[part 3 of 11: packages /Communication/PDUs to /SoftwareTypes/ComponentTypes]
AUTOSAR XML (schema 00048)
package /Communication/PDUs  (continued)
  pdu SIGIPDU_RR_GetPackageData_call_Cis_ICC_8155_Android_ADCC_AomDB: has-dynamic-length=true, length=1312, transmission-mode-true-timing=event-controlled-timing=number-of-repetitions=0
    signal SIG_RR_GetPackageData_call_Cis_ICC_8155_Android_ADCC_AomDB: start 0, 10432 bit, opaque, data-transformations=SOME_IP_Default_Transformation, data-type-policy=TRANSFORMING-I-SIGNAL, someip-transformation-i-signal-props{transformer=SOME_IP_Default_Transformer, message-type=REQUEST}, dynamic-length=true, transfer-property=TRIGGERED, to ADCC
  pdu SIGIPDU_RR_GetPackageData_return_Cis_ICC_8155_Android_ADCC_AomDB: has-dynamic-length=true, length=2097164, transmission-mode-true-timing=event-controlled-timing=number-of-repetitions=0
    signal SIG_RR_GetPackageData_return_Cis_ICC_8155_Android_ADCC_AomDB: start 0, 16777248 bit, opaque, data-transformations=SOME_IP_Default_Transformation, data-type-policy=TRANSFORMING-I-SIGNAL, someip-transformation-i-signal-props{transformer=SOME_IP_Default_Transformer, message-type=RESPONSE}, dynamic-length=true, transfer-property=TRIGGERED, to ICC_8155_Android
  general purpose i pdu TPSIGIPDU_RR_GetPackageData_return_Cis_ICC_8155_Android_ADCC_AomDB: category=SOMEIP_SEGMENTED_IPDU, length=1400
  pdu SIGIPDU_RR_GetPackageData_call_Cis_ICC_8155_QNX_ADCC_AomDB: has-dynamic-length=true, length=1312, transmission-mode-true-timing=event-controlled-timing=number-of-repetitions=0
    signal SIG_RR_GetPackageData_call_Cis_ICC_8155_QNX_ADCC_AomDB: start 0, 10432 bit, opaque, data-transformations=SOME_IP_Default_Transformation, data-type-policy=TRANSFORMING-I-SIGNAL, someip-transformation-i-signal-props{transformer=SOME_IP_Default_Transformer, message-type=REQUEST}, dynamic-length=true, transfer-property=TRIGGERED, to ADCC
  pdu SIGIPDU_RR_GetPackageData_return_Cis_ICC_8155_QNX_ADCC_AomDB: has-dynamic-length=true, length=2097164, transmission-mode-true-timing=event-controlled-timing=number-of-repetitions=0
    signal SIG_RR_GetPackageData_return_Cis_ICC_8155_QNX_ADCC_AomDB: start 0, 16777248 bit, opaque, data-transformations=SOME_IP_Default_Transformation, data-type-policy=TRANSFORMING-I-SIGNAL, someip-transformation-i-signal-props{transformer=SOME_IP_Default_Transformer, message-type=RESPONSE}, dynamic-length=true, transfer-property=TRIGGERED, to ICC_8155_QNX
  general purpose i pdu TPSIGIPDU_RR_GetPackageData_return_Cis_ICC_8155_QNX_ADCC_AomDB: category=SOMEIP_SEGMENTED_IPDU, length=1400
  pdu SIGIPDU_Event_notifyRtMatchRes_ADCC_RtMM: has-dynamic-length=false, length=14304, transmission-mode-true-timing=event-controlled-timing=number-of-repetitions=0
    signal SIG_Event_notifyRtMatchRes_ADCC_RtMM: start 0, 114368 bit, opaque, data-transformations=SOME_IP_Default_Transformation, data-type-policy=TRANSFORMING-I-SIGNAL, someip-transformation-i-signal-props{transformer=SOME_IP_Default_Transformer, message-type=NOTIFICATION}, transfer-property=TRIGGERED, to ICC_8155_Android
  general purpose i pdu TPSIGIPDU_Event_notifyRtMatchRes_ADCC_RtMM: category=SOMEIP_SEGMENTED_IPDU, length=1400
  pdu SIGIPDU_Event_notifyRtMatchRes_ADCC_RtMM_1: has-dynamic-length=false, length=14304, transmission-mode-true-timing=event-controlled-timing=number-of-repetitions=0
    signal SIG_Event_notifyRtMatchRes_ADCC_RtMM_1: start 0, 114368 bit, opaque, data-transformations=SOME_IP_Default_Transformation, data-type-policy=TRANSFORMING-I-SIGNAL, someip-transformation-i-signal-props{transformer=SOME_IP_Default_Transformer, message-type=NOTIFICATION}, transfer-property=TRIGGERED, to ICC_8155_QNX
  general purpose i pdu TPSIGIPDU_Event_notifyRtMatchRes_ADCC_RtMM_1: category=SOMEIP_SEGMENTED_IPDU, length=1400
  pdu SIGIPDU_Event_NtfDynamicObjectList_FCM_DrivingHmiEnv: has-dynamic-length=true, length=2032, transmission-mode-true-timing=event-controlled-timing=number-of-repetitions=0
    signal SIG_Event_NtfDynamicObjectList_FCM_DrivingHmiEnv: start 0, 16192 bit, opaque, data-transformations=SOME_IP_Default_Transformation, data-type-policy=TRANSFORMING-I-SIGNAL, someip-transformation-i-signal-props{transformer=SOME_IP_Default_Transformer, message-type=NOTIFICATION}, dynamic-length=true, transfer-property=TRIGGERED, to ICC_8155_QNX
  general purpose i pdu TPSIGIPDU_Event_NtfDynamicObjectList_FCM_DrivingHmiEnv: category=SOMEIP_SEGMENTED_IPDU, length=1400
  pdu SIGIPDU_Event_NtfStaticObjectList_FCM_DrivingHmiEnv: has-dynamic-length=true, length=1696, transmission-mode-true-timing=event-controlled-timing=number-of-repetitions=0
    signal SIG_Event_NtfStaticObjectList_FCM_DrivingHmiEnv: start 0, 13504 bit, opaque, data-transformations=SOME_IP_Default_Transformation, data-type-policy=TRANSFORMING-I-SIGNAL, someip-transformation-i-signal-props{transformer=SOME_IP_Default_Transformer, message-type=NOTIFICATION}, dynamic-length=true, transfer-property=TRIGGERED, to ICC_8155_QNX
  general purpose i pdu TPSIGIPDU_Event_NtfStaticObjectList_FCM_DrivingHmiEnv: category=SOMEIP_SEGMENTED_IPDU, length=1400
  pdu SIGIPDU_Event_NtfLaneLineList_FCM_DrivingHmiEnv: has-dynamic-length=true, length=332, transmission-mode-true-timing=event-controlled-timing=number-of-repetitions=0
    signal SIG_Event_NtfLaneLineList_FCM_DrivingHmiEnv: start 0, 2592 bit, opaque, data-transformations=SOME_IP_Default_Transformation, data-type-policy=TRANSFORMING-I-SIGNAL, someip-transformation-i-signal-props{transformer=SOME_IP_Default_Transformer, message-type=NOTIFICATION}, dynamic-length=true, transfer-property=TRIGGERED, to ICC_8155_QNX
  pdu SIGIPDU_Event_NtfLaneLineList_2_FCM_DrivingHmiEnv: has-dynamic-length=true, length=146224, transmission-mode-true-timing=event-controlled-timing=number-of-repetitions=0
    signal SIG_Event_NtfLaneLineList_2_FCM_DrivingHmiEnv: start 0, 1169728 bit, opaque, data-transformations=SOME_IP_Default_Transformation, data-type-policy=TRANSFORMING-I-SIGNAL, someip-transformation-i-signal-props{transformer=SOME_IP_Default_Transformer, message-type=NOTIFICATION}, dynamic-length=true, transfer-property=TRIGGERED, to ICC_8155_QNX
  general purpose i pdu TPSIGIPDU_Event_NtfLaneLineList_2_FCM_DrivingHmiEnv: category=SOMEIP_SEGMENTED_IPDU, length=1400
  pdu SIGIPDU_Event_NtfEgoFusionPose_FCM_DrivingHmiEnv: has-dynamic-length=false, length=56, transmission-mode-true-timing=event-controlled-timing=number-of-repetitions=0
    signal SIG_Event_NtfEgoFusionPose_FCM_DrivingHmiEnv: start 0, 384 bit, opaque, data-transformations=SOME_IP_Default_Transformation, data-type-policy=TRANSFORMING-I-SIGNAL, someip-transformation-i-signal-props{transformer=SOME_IP_Default_Transformer, message-type=NOTIFICATION}, transfer-property=TRIGGERED, to ICC_8155_QNX
  pdu SIGIPDU_Event_NtfDynamicObjectList_2_FCM_DrivingHmiEnv: has-dynamic-length=true, length=8416, transmission-mode-true-timing=event-controlled-timing=number-of-repetitions=0
    signal SIG_Event_NtfDynamicObjectList_2_FCM_DrivingHmiEnv: start 0, 67264 bit, opaque, data-transformations=SOME_IP_Default_Transformation, data-type-policy=TRANSFORMING-I-SIGNAL, someip-transformation-i-signal-props{transformer=SOME_IP_Default_Transformer, message-type=NOTIFICATION}, dynamic-length=true, transfer-property=TRIGGERED, to ICC_8155_QNX
  general purpose i pdu TPSIGIPDU_Event_NtfDynamicObjectList_2_FCM_DrivingHmiEnv: category=SOMEIP_SEGMENTED_IPDU, length=1400
  pdu SIGIPDU_Event_NtfStaticObjectList_2_FCM_DrivingHmiEnv: has-dynamic-length=true, length=4816, transmission-mode-true-timing=event-controlled-timing=number-of-repetitions=0
    signal SIG_Event_NtfStaticObjectList_2_FCM_DrivingHmiEnv: start 0, 38464 bit, opaque, data-transformations=SOME_IP_Default_Transformation, data-type-policy=TRANSFORMING-I-SIGNAL, someip-transformation-i-signal-props{transformer=SOME_IP_Default_Transformer, message-type=NOTIFICATION}, dynamic-length=true, transfer-property=TRIGGERED, to ICC_8155_QNX
  general purpose i pdu TPSIGIPDU_Event_NtfStaticObjectList_2_FCM_DrivingHmiEnv: category=SOMEIP_SEGMENTED_IPDU, length=1400
  pdu SIGIPDU_Event_NtfDynamicObjectList_FCM_DrivingHmiEnv_1: has-dynamic-length=true, length=2032, transmission-mode-true-timing=event-controlled-timing=number-of-repetitions=0
    signal SIG_Event_NtfDynamicObjectList_FCM_DrivingHmiEnv_1: start 0, 16192 bit, opaque, data-transformations=SOME_IP_Default_Transformation, data-type-policy=TRANSFORMING-I-SIGNAL, someip-transformation-i-signal-props{transformer=SOME_IP_Default_Transformer, message-type=NOTIFICATION}, dynamic-length=true, transfer-property=TRIGGERED, to ICC_8155_Android
  general purpose i pdu TPSIGIPDU_Event_NtfDynamicObjectList_FCM_DrivingHmiEnv_1: category=SOMEIP_SEGMENTED_IPDU, length=1400
  pdu SIGIPDU_Event_NtfStaticObjectList_FCM_DrivingHmiEnv_1: has-dynamic-length=true, length=1696, transmission-mode-true-timing=event-controlled-timing=number-of-repetitions=0
    signal SIG_Event_NtfStaticObjectList_FCM_DrivingHmiEnv_1: start 0, 13504 bit, opaque, data-transformations=SOME_IP_Default_Transformation, data-type-policy=TRANSFORMING-I-SIGNAL, someip-transformation-i-signal-props{transformer=SOME_IP_Default_Transformer, message-type=NOTIFICATION}, dynamic-length=true, transfer-property=TRIGGERED, to ICC_8155_Android
  general purpose i pdu TPSIGIPDU_Event_NtfStaticObjectList_FCM_DrivingHmiEnv_1: category=SOMEIP_SEGMENTED_IPDU, length=1400
  pdu SIGIPDU_Event_NtfLaneLineList_FCM_DrivingHmiEnv_1: has-dynamic-length=true, length=332, transmission-mode-true-timing=event-controlled-timing=number-of-repetitions=0
    signal SIG_Event_NtfLaneLineList_FCM_DrivingHmiEnv_1: start 0, 2592 bit, opaque, data-transformations=SOME_IP_Default_Transformation, data-type-policy=TRANSFORMING-I-SIGNAL, someip-transformation-i-signal-props{transformer=SOME_IP_Default_Transformer, message-type=NOTIFICATION}, dynamic-length=true, transfer-property=TRIGGERED, to ICC_8155_Android
  pdu SIGIPDU_Event_NtfLaneLineList_2_FCM_DrivingHmiEnv_1: has-dynamic-length=true, length=146224, transmission-mode-true-timing=event-controlled-timing=number-of-repetitions=0
    signal SIG_Event_NtfLaneLineList_2_FCM_DrivingHmiEnv_1: start 0, 1169728 bit, opaque, data-transformations=SOME_IP_Default_Transformation, data-type-policy=TRANSFORMING-I-SIGNAL, someip-transformation-i-signal-props{transformer=SOME_IP_Default_Transformer, message-type=NOTIFICATION}, dynamic-length=true, transfer-property=TRIGGERED, to ICC_8155_Android
  general purpose i pdu TPSIGIPDU_Event_NtfLaneLineList_2_FCM_DrivingHmiEnv_1: category=SOMEIP_SEGMENTED_IPDU, length=1400
  pdu SIGIPDU_Event_NtfEgoFusionPose_FCM_DrivingHmiEnv_1: has-dynamic-length=false, length=56, transmission-mode-true-timing=event-controlled-timing=number-of-repetitions=0
    signal SIG_Event_NtfEgoFusionPose_FCM_DrivingHmiEnv_1: start 0, 384 bit, opaque, data-transformations=SOME_IP_Default_Transformation, data-type-policy=TRANSFORMING-I-SIGNAL, someip-transformation-i-signal-props{transformer=SOME_IP_Default_Transformer, message-type=NOTIFICATION}, transfer-property=TRIGGERED, to ICC_8155_Android
  pdu SIGIPDU_Event_NtfDynamicObjectList_2_FCM_DrivingHmiEnv_1: has-dynamic-length=true, length=8416, transmission-mode-true-timing=event-controlled-timing=number-of-repetitions=0
    signal SIG_Event_NtfDynamicObjectList_2_FCM_DrivingHmiEnv_1: start 0, 67264 bit, opaque, data-transformations=SOME_IP_Default_Transformation, data-type-policy=TRANSFORMING-I-SIGNAL, someip-transformation-i-signal-props{transformer=SOME_IP_Default_Transformer, message-type=NOTIFICATION}, dynamic-length=true, transfer-property=TRIGGERED, to ICC_8155_Android
  general purpose i pdu TPSIGIPDU_Event_NtfDynamicObjectList_2_FCM_DrivingHmiEnv_1: category=SOMEIP_SEGMENTED_IPDU, length=1400
  pdu SIGIPDU_Event_NtfStaticObjectList_2_FCM_DrivingHmiEnv_1: has-dynamic-length=true, length=4816, transmission-mode-true-timing=event-controlled-timing=number-of-repetitions=0
    signal SIG_Event_NtfStaticObjectList_2_FCM_DrivingHmiEnv_1: start 0, 38464 bit, opaque, data-transformations=SOME_IP_Default_Transformation, data-type-policy=TRANSFORMING-I-SIGNAL, someip-transformation-i-signal-props{transformer=SOME_IP_Default_Transformer, message-type=NOTIFICATION}, dynamic-length=true, transfer-property=TRIGGERED, to ICC_8155_Android
  general purpose i pdu TPSIGIPDU_Event_NtfStaticObjectList_2_FCM_DrivingHmiEnv_1: category=SOMEIP_SEGMENTED_IPDU, length=1400
  pdu SIGIPDU_Event_NtfActiveSafetyFcnInfo_FCM_ActiveSafetyInfo: has-dynamic-length=false, length=27, transmission-mode-true-timing=event-controlled-timing=number-of-repetitions=0
    signal SIG_Event_NtfActiveSafetyFcnInfo_FCM_ActiveSafetyInfo: start 0, 40 bit, opaque, data-transformations=SOMEIP_E2E_Transformer_PROFILE_04_B, data-type-policy=TRANSFORMING-I-SIGNAL, transfer-property=TRIGGERED, to ICC_8155_Android
  pdu SIGIPDU_Event_NtfAEBTargetObjInfo_FCM_ActiveSafetyInfo: has-dynamic-length=false, length=24, transmission-mode-true-timing=event-controlled-timing=number-of-repetitions=0
    signal SIG_Event_NtfAEBTargetObjInfo_FCM_ActiveSafetyInfo: start 0, 128 bit, opaque, data-transformations=SOME_IP_Default_Transformation, data-type-policy=TRANSFORMING-I-SIGNAL, someip-transformation-i-signal-props{transformer=SOME_IP_Default_Transformer, message-type=NOTIFICATION}, transfer-property=TRIGGERED, to ICC_8155_Android
  pdu SIGIPDU_Event_NtfActiveSafetyFcnInfo_2_FCM_ActiveSafetyInfo: has-dynamic-length=false, length=64, transmission-mode-true-timing=event-controlled-timing=number-of-repetitions=0
    signal SIG_Event_NtfActiveSafetyFcnInfo_2_FCM_ActiveSafetyInfo: start 0, 448 bit, opaque, data-transformations=SOME_IP_Default_Transformation, data-type-policy=TRANSFORMING-I-SIGNAL, someip-transformation-i-signal-props{transformer=SOME_IP_Default_Transformer, message-type=NOTIFICATION}, transfer-property=TRIGGERED, to ICC_8155_Android
  pdu SIGIPDU_Event_NtfAEBTargetObjInfo_2_FCM_ActiveSafetyInfo: has-dynamic-length=false, length=32, transmission-mode-true-timing=event-controlled-timing=number-of-repetitions=0
    signal SIG_Event_NtfAEBTargetObjInfo_2_FCM_ActiveSafetyInfo: start 0, 192 bit, opaque, data-transformations=SOME_IP_Default_Transformation, data-type-policy=TRANSFORMING-I-SIGNAL, someip-transformation-i-signal-props{transformer=SOME_IP_Default_Transformer, message-type=NOTIFICATION}, transfer-property=TRIGGERED, to ICC_8155_Android
  pdu SIGIPDU_Event_NtfActiveSafetyFcnInfo_FCM_ActiveSafetyInfo_1: has-dynamic-length=false, length=27, transmission-mode-true-timing=event-controlled-timing=number-of-repetitions=0
    signal SIG_Event_NtfActiveSafetyFcnInfo_FCM_ActiveSafetyInfo_1: start 0, 40 bit, opaque, data-transformations=SOMEIP_E2E_Transformer_PROFILE_04_B, data-type-policy=TRANSFORMING-I-SIGNAL, transfer-property=TRIGGERED, to ICC_8155_QNX
  pdu SIGIPDU_Event_NtfAEBTargetObjInfo_FCM_ActiveSafetyInfo_1: has-dynamic-length=false, length=24, transmission-mode-true-timing=event-controlled-timing=number-of-repetitions=0
    signal SIG_Event_NtfAEBTargetObjInfo_FCM_ActiveSafetyInfo_1: start 0, 128 bit, opaque, data-transformations=SOME_IP_Default_Transformation, data-type-policy=TRANSFORMING-I-SIGNAL, someip-transformation-i-signal-props{transformer=SOME_IP_Default_Transformer, message-type=NOTIFICATION}, transfer-property=TRIGGERED, to ICC_8155_QNX
  pdu SIGIPDU_Event_NtfActiveSafetyFcnInfo_2_FCM_ActiveSafetyInfo_1: has-dynamic-length=false, length=64, transmission-mode-true-timing=event-controlled-timing=number-of-repetitions=0
    signal SIG_Event_NtfActiveSafetyFcnInfo_2_FCM_ActiveSafetyInfo_1: start 0, 448 bit, opaque, data-transformations=SOME_IP_Default_Transformation, data-type-policy=TRANSFORMING-I-SIGNAL, someip-transformation-i-signal-props{transformer=SOME_IP_Default_Transformer, message-type=NOTIFICATION}, transfer-property=TRIGGERED, to ICC_8155_QNX
  pdu SIGIPDU_Event_NtfAEBTargetObjInfo_2_FCM_ActiveSafetyInfo_1: has-dynamic-length=false, length=32, transmission-mode-true-timing=event-controlled-timing=number-of-repetitions=0
    signal SIG_Event_NtfAEBTargetObjInfo_2_FCM_ActiveSafetyInfo_1: start 0, 192 bit, opaque, data-transformations=SOME_IP_Default_Transformation, data-type-policy=TRANSFORMING-I-SIGNAL, someip-transformation-i-signal-props{transformer=SOME_IP_Default_Transformer, message-type=NOTIFICATION}, transfer-property=TRIGGERED, to ICC_8155_QNX
  pdu SIGIPDU_Event_NtfTrafficSign_FCM_DrivingFuncInfo: has-dynamic-length=false, length=24, transmission-mode-true-timing=event-controlled-timing=number-of-repetitions=0
    signal SIG_Event_NtfTrafficSign_FCM_DrivingFuncInfo: start 0, 128 bit, opaque, data-transformations=SOME_IP_Default_Transformation, data-type-policy=TRANSFORMING-I-SIGNAL, someip-transformation-i-signal-props{transformer=SOME_IP_Default_Transformer, message-type=NOTIFICATION}, transfer-property=TRIGGERED, to ICC_8155_Android
  pdu SIGIPDU_Event_NtfISLIinfo_FCM_DrivingFuncInfo: has-dynamic-length=false, length=16, transmission-mode-true-timing=event-controlled-timing=number-of-repetitions=0
    signal SIG_Event_NtfISLIinfo_FCM_DrivingFuncInfo: start 0, 64 bit, opaque, data-transformations=SOME_IP_Default_Transformation, data-type-policy=TRANSFORMING-I-SIGNAL, someip-transformation-i-signal-props{transformer=SOME_IP_Default_Transformer, message-type=NOTIFICATION}, transfer-property=TRIGGERED, to ICC_8155_Android
  pdu SIGIPDU_Event_NtfACCinfo_FCM_DrivingFuncInfo: has-dynamic-length=false, length=40, transmission-mode-true-timing=event-controlled-timing=number-of-repetitions=0
    signal SIG_Event_NtfACCinfo_FCM_DrivingFuncInfo: start 0, 144 bit, opaque, data-transformations=SOMEIP_E2E_Transformer_PROFILE_04_B, data-type-policy=TRANSFORMING-I-SIGNAL, transfer-property=TRIGGERED, to ICC_8155_Android
  pdu SIGIPDU_Event_NtfICAInfo_FCM_DrivingFuncInfo: has-dynamic-length=false, length=12, transmission-mode-true-timing=event-controlled-timing=number-of-repetitions=0
    signal SIG_Event_NtfICAInfo_FCM_DrivingFuncInfo: start 0, 32 bit, opaque, data-transformations=SOME_IP_Default_Transformation, data-type-policy=TRANSFORMING-I-SIGNAL, someip-transformation-i-signal-props{transformer=SOME_IP_Default_Transformer, message-type=NOTIFICATION}, transfer-property=TRIGGERED, to ICC_8155_Android
  pdu SIGIPDU_Event_NtfIntelligentEvasionInfo_FCM_DrivingFuncInfo: has-dynamic-length=false, length=11, transmission-mode-true-timing=event-controlled-timing=number-of-repetitions=0
    signal SIG_Event_NtfIntelligentEvasionInfo_FCM_DrivingFuncInfo: start 0, 24 bit, opaque, data-transformations=SOME_IP_Default_Transformation, data-type-policy=TRANSFORMING-I-SIGNAL, someip-transformation-i-signal-props{transformer=SOME_IP_Default_Transformer, message-type=NOTIFICATION}, transfer-property=TRIGGERED, to ICC_8155_Android
  pdu SIGIPDU_Event_NtfHodDmsInfo_FCM_DrivingFuncInfo: has-dynamic-length=false, length=12, transmission-mode-true-timing=event-controlled-timing=number-of-repetitions=0
    signal SIG_Event_NtfHodDmsInfo_FCM_DrivingFuncInfo: start 0, 32 bit, opaque, data-transformations=SOME_IP_Default_Transformation, data-type-policy=TRANSFORMING-I-SIGNAL, someip-transformation-i-signal-props{transformer=SOME_IP_Default_Transformer, message-type=NOTIFICATION}, transfer-property=TRIGGERED, to ICC_8155_Android
  pdu SIGIPDU_Event_NtfLSSInfo_FCM_DrivingFuncInfo: has-dynamic-length=false, length=16, transmission-mode-true-timing=event-controlled-timing=number-of-repetitions=0
    signal SIG_Event_NtfLSSInfo_FCM_DrivingFuncInfo: start 0, 64 bit, opaque, data-transformations=SOME_IP_Default_Transformation, data-type-policy=TRANSFORMING-I-SIGNAL, someip-transformation-i-signal-props{transformer=SOME_IP_Default_Transformer, message-type=NOTIFICATION}, transfer-property=TRIGGERED, to ICC_8155_Android
  pdu SIGIPDU_Event_NtfESSInfo_FCM_DrivingFuncInfo: has-dynamic-length=false, length=12, transmission-mode-true-timing=event-controlled-timing=number-of-repetitions=0
    signal SIG_Event_NtfESSInfo_FCM_DrivingFuncInfo: start 0, 32 bit, opaque, data-transformations=SOME_IP_Default_Transformation, data-type-policy=TRANSFORMING-I-SIGNAL, someip-transformation-i-signal-props{transformer=SOME_IP_Default_Transformer, message-type=NOTIFICATION}, transfer-property=TRIGGERED, to ICC_8155_Android
  pdu SIGIPDU_Event_NtfDAIInfo_FCM_DrivingFuncInfo: has-dynamic-length=false, length=10, transmission-mode-true-timing=event-controlled-timing=number-of-repetitions=0
    signal SIG_Event_NtfDAIInfo_FCM_DrivingFuncInfo: start 0, 16 bit, opaque, data-transformations=SOME_IP_Default_Transformation, data-type-policy=TRANSFORMING-I-SIGNAL, someip-transformation-i-signal-props{transformer=SOME_IP_Default_Transformer, message-type=NOTIFICATION}, transfer-property=TRIGGERED, to ICC_8155_Android
  pdu SIGIPDU_Event_NtfISLIinfo_2_FCM_DrivingFuncInfo: has-dynamic-length=false, length=69, transmission-mode-true-timing=event-controlled-timing=number-of-repetitions=0
    signal SIG_Event_NtfISLIinfo_2_FCM_DrivingFuncInfo: start 0, 488 bit, opaque, data-transformations=SOME_IP_Default_Transformation, data-type-policy=TRANSFORMING-I-SIGNAL, someip-transformation-i-signal-props{transformer=SOME_IP_Default_Transformer, message-type=NOTIFICATION}, transfer-property=TRIGGERED, to ICC_8155_Android
  pdu SIGIPDU_Event_NtfLSSInfo_2_FCM_DrivingFuncInfo: has-dynamic-length=false, length=68, transmission-mode-true-timing=event-controlled-timing=number-of-repetitions=0
    signal SIG_Event_NtfLSSInfo_2_FCM_DrivingFuncInfo: start 0, 480 bit, opaque, data-transformations=SOME_IP_Default_Transformation, data-type-policy=TRANSFORMING-I-SIGNAL, someip-transformation-i-signal-props{transformer=SOME_IP_Default_Transformer, message-type=NOTIFICATION}, transfer-property=TRIGGERED, to ICC_8155_Android
  pdu SIGIPDU_Event_NtfDrivingSoundInfo_FCM_DrivingFuncInfo: has-dynamic-length=false, length=39, transmission-mode-true-timing=event-controlled-timing=number-of-repetitions=0
    signal SIG_Event_NtfDrivingSoundInfo_FCM_DrivingFuncInfo: start 0, 248 bit, opaque, data-transformations=SOME_IP_Default_Transformation, data-type-policy=TRANSFORMING-I-SIGNAL, someip-transformation-i-signal-props{transformer=SOME_IP_Default_Transformer, message-type=NOTIFICATION}, transfer-property=TRIGGERED, to ICC_8155_Android
  pdu SIGIPDU_Event_NtfIHCInfo_FCM_DrivingFuncInfo: has-dynamic-length=false, length=60, transmission-mode-true-timing=event-controlled-timing=number-of-repetitions=0
    signal SIG_Event_NtfIHCInfo_FCM_DrivingFuncInfo: start 0, 416 bit, opaque, data-transformations=SOME_IP_Default_Transformation, data-type-policy=TRANSFORMING-I-SIGNAL, someip-transformation-i-signal-props{transformer=SOME_IP_Default_Transformer, message-type=NOTIFICATION}, transfer-property=TRIGGERED, to ICC_8155_Android
  pdu SIGIPDU_Event_NtfHNOPfunctionInfo_FCM_DrivingFuncInfo: has-dynamic-length=false, length=536, transmission-mode-true-timing=event-controlled-timing=number-of-repetitions=0
    signal SIG_Event_NtfHNOPfunctionInfo_FCM_DrivingFuncInfo: start 0, 4224 bit, opaque, data-transformations=SOME_IP_Default_Transformation, data-type-policy=TRANSFORMING-I-SIGNAL, someip-transformation-i-signal-props{transformer=SOME_IP_Default_Transformer, message-type=NOTIFICATION}, transfer-property=TRIGGERED, to ICC_8155_Android
  pdu SIGIPDU_Event_NtfTrafficSign_FCM_DrivingFuncInfo_1: has-dynamic-length=false, length=24, transmission-mode-true-timing=event-controlled-timing=number-of-repetitions=0
    signal SIG_Event_NtfTrafficSign_FCM_DrivingFuncInfo_1: start 0, 128 bit, opaque, data-transformations=SOME_IP_Default_Transformation, data-type-policy=TRANSFORMING-I-SIGNAL, someip-transformation-i-signal-props{transformer=SOME_IP_Default_Transformer, message-type=NOTIFICATION}, transfer-property=TRIGGERED, to ICC_8155_QNX
  pdu SIGIPDU_Event_NtfISLIinfo_FCM_DrivingFuncInfo_1: has-dynamic-length=false, length=16, transmission-mode-true-timing=event-controlled-timing=number-of-repetitions=0
    signal SIG_Event_NtfISLIinfo_FCM_DrivingFuncInfo_1: start 0, 64 bit, opaque, data-transformations=SOME_IP_Default_Transformation, data-type-policy=TRANSFORMING-I-SIGNAL, someip-transformation-i-signal-props{transformer=SOME_IP_Default_Transformer, message-type=NOTIFICATION}, transfer-property=TRIGGERED, to ICC_8155_QNX
  pdu SIGIPDU_Event_NtfACCinfo_FCM_DrivingFuncInfo_1: has-dynamic-length=false, length=40, transmission-mode-true-timing=event-controlled-timing=number-of-repetitions=0
    signal SIG_Event_NtfACCinfo_FCM_DrivingFuncInfo_1: start 0, 144 bit, opaque, data-transformations=SOMEIP_E2E_Transformer_PROFILE_04_B, data-type-policy=TRANSFORMING-I-SIGNAL, transfer-property=TRIGGERED, to ICC_8155_QNX
  pdu SIGIPDU_Event_NtfICAInfo_FCM_DrivingFuncInfo_1: has-dynamic-length=false, length=12, transmission-mode-true-timing=event-controlled-timing=number-of-repetitions=0
    signal SIG_Event_NtfICAInfo_FCM_DrivingFuncInfo_1: start 0, 32 bit, opaque, data-transformations=SOME_IP_Default_Transformation, data-type-policy=TRANSFORMING-I-SIGNAL, someip-transformation-i-signal-props{transformer=SOME_IP_Default_Transformer, message-type=NOTIFICATION}, transfer-property=TRIGGERED, to ICC_8155_QNX
  pdu SIGIPDU_Event_NtfIntelligentEvasionInfo_FCM_DrivingFuncInfo_1: has-dynamic-length=false, length=11, transmission-mode-true-timing=event-controlled-timing=number-of-repetitions=0
    signal SIG_Event_NtfIntelligentEvasionInfo_FCM_DrivingFuncInfo_1: start 0, 24 bit, opaque, data-transformations=SOME_IP_Default_Transformation, data-type-policy=TRANSFORMING-I-SIGNAL, someip-transformation-i-signal-props{transformer=SOME_IP_Default_Transformer, message-type=NOTIFICATION}, transfer-property=TRIGGERED, to ICC_8155_QNX
  pdu SIGIPDU_Event_NtfHodDmsInfo_FCM_DrivingFuncInfo_1: has-dynamic-length=false, length=12, transmission-mode-true-timing=event-controlled-timing=number-of-repetitions=0
    signal SIG_Event_NtfHodDmsInfo_FCM_DrivingFuncInfo_1: start 0, 32 bit, opaque, data-transformations=SOME_IP_Default_Transformation, data-type-policy=TRANSFORMING-I-SIGNAL, someip-transformation-i-signal-props{transformer=SOME_IP_Default_Transformer, message-type=NOTIFICATION}, transfer-property=TRIGGERED, to ICC_8155_QNX
  pdu SIGIPDU_Event_NtfLSSInfo_FCM_DrivingFuncInfo_1: has-dynamic-length=false, length=16, transmission-mode-true-timing=event-controlled-timing=number-of-repetitions=0
    signal SIG_Event_NtfLSSInfo_FCM_DrivingFuncInfo_1: start 0, 64 bit, opaque, data-transformations=SOME_IP_Default_Transformation, data-type-policy=TRANSFORMING-I-SIGNAL, someip-transformation-i-signal-props{transformer=SOME_IP_Default_Transformer, message-type=NOTIFICATION}, transfer-property=TRIGGERED, to ICC_8155_QNX
  pdu SIGIPDU_Event_NtfESSInfo_FCM_DrivingFuncInfo_1: has-dynamic-length=false, length=12, transmission-mode-true-timing=event-controlled-timing=number-of-repetitions=0
    signal SIG_Event_NtfESSInfo_FCM_DrivingFuncInfo_1: start 0, 32 bit, opaque, data-transformations=SOME_IP_Default_Transformation, data-type-policy=TRANSFORMING-I-SIGNAL, someip-transformation-i-signal-props{transformer=SOME_IP_Default_Transformer, message-type=NOTIFICATION}, transfer-property=TRIGGERED, to ICC_8155_QNX
  pdu SIGIPDU_Event_NtfDAIInfo_FCM_DrivingFuncInfo_1: has-dynamic-length=false, length=10, transmission-mode-true-timing=event-controlled-timing=number-of-repetitions=0
    signal SIG_Event_NtfDAIInfo_FCM_DrivingFuncInfo_1: start 0, 16 bit, opaque, data-transformations=SOME_IP_Default_Transformation, data-type-policy=TRANSFORMING-I-SIGNAL, someip-transformation-i-signal-props{transformer=SOME_IP_Default_Transformer, message-type=NOTIFICATION}, transfer-property=TRIGGERED, to ICC_8155_QNX
  pdu SIGIPDU_Event_NtfISLIinfo_2_FCM_DrivingFuncInfo_1: has-dynamic-length=false, length=69, transmission-mode-true-timing=event-controlled-timing=number-of-repetitions=0
    signal SIG_Event_NtfISLIinfo_2_FCM_DrivingFuncInfo_1: start 0, 488 bit, opaque, data-transformations=SOME_IP_Default_Transformation, data-type-policy=TRANSFORMING-I-SIGNAL, someip-transformation-i-signal-props{transformer=SOME_IP_Default_Transformer, message-type=NOTIFICATION}, transfer-property=TRIGGERED, to ICC_8155_QNX
  pdu SIGIPDU_Event_NtfLSSInfo_2_FCM_DrivingFuncInfo_1: has-dynamic-length=false, length=68, transmission-mode-true-timing=event-controlled-timing=number-of-repetitions=0
    signal SIG_Event_NtfLSSInfo_2_FCM_DrivingFuncInfo_1: start 0, 480 bit, opaque, data-transformations=SOME_IP_Default_Transformation, data-type-policy=TRANSFORMING-I-SIGNAL, someip-transformation-i-signal-props{transformer=SOME_IP_Default_Transformer, message-type=NOTIFICATION}, transfer-property=TRIGGERED, to ICC_8155_QNX
  pdu SIGIPDU_Event_NtfDrivingSoundInfo_FCM_DrivingFuncInfo_1: has-dynamic-length=false, length=39, transmission-mode-true-timing=event-controlled-timing=number-of-repetitions=0
    signal SIG_Event_NtfDrivingSoundInfo_FCM_DrivingFuncInfo_1: start 0, 248 bit, opaque, data-transformations=SOME_IP_Default_Transformation, data-type-policy=TRANSFORMING-I-SIGNAL, someip-transformation-i-signal-props{transformer=SOME_IP_Default_Transformer, message-type=NOTIFICATION}, transfer-property=TRIGGERED, to ICC_8155_QNX
  pdu SIGIPDU_Event_NtfIHCInfo_FCM_DrivingFuncInfo_1: has-dynamic-length=false, length=60, transmission-mode-true-timing=event-controlled-timing=number-of-repetitions=0
    signal SIG_Event_NtfIHCInfo_FCM_DrivingFuncInfo_1: start 0, 416 bit, opaque, data-transformations=SOME_IP_Default_Transformation, data-type-policy=TRANSFORMING-I-SIGNAL, someip-transformation-i-signal-props{transformer=SOME_IP_Default_Transformer, message-type=NOTIFICATION}, transfer-property=TRIGGERED, to ICC_8155_QNX
  pdu SIGIPDU_Event_NtfHNOPfunctionInfo_FCM_DrivingFuncInfo_1: has-dynamic-length=false, length=536, transmission-mode-true-timing=event-controlled-timing=number-of-repetitions=0
    signal SIG_Event_NtfHNOPfunctionInfo_FCM_DrivingFuncInfo_1: start 0, 4224 bit, opaque, data-transformations=SOME_IP_Default_Transformation, data-type-policy=TRANSFORMING-I-SIGNAL, someip-transformation-i-signal-props{transformer=SOME_IP_Default_Transformer, message-type=NOTIFICATION}, transfer-property=TRIGGERED, to ICC_8155_QNX
  pdu SIGIPDU_Event_notifyDVRSts_FCM_DVRSts: has-dynamic-length=false, length=9, transmission-mode-true-timing=event-controlled-timing=number-of-repetitions=0
    signal SIG_Event_notifyDVRSts_FCM_DVRSts: start 0, 8 bit, opaque, data-transformations=SOME_IP_Default_Transformation, data-type-policy=TRANSFORMING-I-SIGNAL, someip-transformation-i-signal-props{transformer=SOME_IP_Default_Transformer, message-type=NOTIFICATION}, transfer-property=TRIGGERED, to ICC_8155_Android
  pdu SIGIPDU_Event_notifyDVRcameraSts_FCM_DVRSts: has-dynamic-length=false, length=9, transmission-mode-true-timing=event-controlled-timing=number-of-repetitions=0
    signal SIG_Event_notifyDVRcameraSts_FCM_DVRSts: start 0, 8 bit, opaque, data-transformations=SOME_IP_Default_Transformation, data-type-policy=TRANSFORMING-I-SIGNAL, someip-transformation-i-signal-props{transformer=SOME_IP_Default_Transformer, message-type=NOTIFICATION}, transfer-property=TRIGGERED, to ICC_8155_Android
  pdu SIGIPDU_Event_notifyCameraInterParm_FCM_DVRSts: has-dynamic-length=false, length=104, transmission-mode-true-timing=event-controlled-timing=number-of-repetitions=0
    signal SIG_Event_notifyCameraInterParm_FCM_DVRSts: start 0, 768 bit, opaque, data-transformations=SOME_IP_Default_Transformation, data-type-policy=TRANSFORMING-I-SIGNAL, someip-transformation-i-signal-props{transformer=SOME_IP_Default_Transformer, message-type=NOTIFICATION}, transfer-property=TRIGGERED, to ICC_8155_Android
  pdu SIGIPDU_RR_getCameraInterParm_call_Cis_ICC_8155_Android_FCM_DVRSts: has-dynamic-length=true, length=8, transmission-mode-true-timing=event-controlled-timing=number-of-repetitions=0
    signal SIG_RR_getCameraInterParm_call_Cis_ICC_8155_Android_FCM_DVRSts: start 0, 0 bit, opaque, data-transformations=SOME_IP_Default_Transformation, data-type-policy=TRANSFORMING-I-SIGNAL, someip-transformation-i-signal-props{transformer=SOME_IP_Default_Transformer, message-type=REQUEST}, dynamic-length=true, transfer-property=TRIGGERED, to FCM
  pdu SIGIPDU_RR_getCameraInterParm_return_Cis_ICC_8155_Android_FCM_DVRSts: has-dynamic-length=false, length=104, transmission-mode-true-timing=event-controlled-timing=number-of-repetitions=0
    signal SIG_RR_getCameraInterParm_return_Cis_ICC_8155_Android_FCM_DVRSts: start 0, 768 bit, opaque, data-transformations=SOME_IP_Default_Transformation, data-type-policy=TRANSFORMING-I-SIGNAL, someip-transformation-i-signal-props{transformer=SOME_IP_Default_Transformer, message-type=RESPONSE}, transfer-property=TRIGGERED, to ICC_8155_Android
  pdu SIGIPDU_Event_notifyDVRSts_FCM_DVRSts_1: has-dynamic-length=false, length=9, transmission-mode-true-timing=event-controlled-timing=number-of-repetitions=0
    signal SIG_Event_notifyDVRSts_FCM_DVRSts_1: start 0, 8 bit, opaque, data-transformations=SOME_IP_Default_Transformation, data-type-policy=TRANSFORMING-I-SIGNAL, someip-transformation-i-signal-props{transformer=SOME_IP_Default_Transformer, message-type=NOTIFICATION}, transfer-property=TRIGGERED, to ICC_8155_QNX
  pdu SIGIPDU_Event_notifyDVRcameraSts_FCM_DVRSts_1: has-dynamic-length=false, length=9, transmission-mode-true-timing=event-controlled-timing=number-of-repetitions=0
    signal SIG_Event_notifyDVRcameraSts_FCM_DVRSts_1: start 0, 8 bit, opaque, data-transformations=SOME_IP_Default_Transformation, data-type-policy=TRANSFORMING-I-SIGNAL, someip-transformation-i-signal-props{transformer=SOME_IP_Default_Transformer, message-type=NOTIFICATION}, transfer-property=TRIGGERED, to ICC_8155_QNX
  pdu SIGIPDU_Event_notifyCameraInterParm_FCM_DVRSts_1: has-dynamic-length=false, length=104, transmission-mode-true-timing=event-controlled-timing=number-of-repetitions=0
    signal SIG_Event_notifyCameraInterParm_FCM_DVRSts_1: start 0, 768 bit, opaque, data-transformations=SOME_IP_Default_Transformation, data-type-policy=TRANSFORMING-I-SIGNAL, someip-transformation-i-signal-props{transformer=SOME_IP_Default_Transformer, message-type=NOTIFICATION}, transfer-property=TRIGGERED, to ICC_8155_QNX
  pdu SIGIPDU_RR_getCameraInterParm_call_Cis_ICC_8155_QNX_FCM_DVRSts: has-dynamic-length=true, length=8, transmission-mode-true-timing=event-controlled-timing=number-of-repetitions=0
    signal SIG_RR_getCameraInterParm_call_Cis_ICC_8155_QNX_FCM_DVRSts: start 0, 0 bit, opaque, data-transformations=SOME_IP_Default_Transformation, data-type-policy=TRANSFORMING-I-SIGNAL, someip-transformation-i-signal-props{transformer=SOME_IP_Default_Transformer, message-type=REQUEST}, dynamic-length=true, transfer-property=TRIGGERED, to FCM
  pdu SIGIPDU_RR_getCameraInterParm_return_Cis_ICC_8155_QNX_FCM_DVRSts: has-dynamic-length=false, length=104, transmission-mode-true-timing=event-controlled-timing=number-of-repetitions=0
    signal SIG_RR_getCameraInterParm_return_Cis_ICC_8155_QNX_FCM_DVRSts: start 0, 768 bit, opaque, data-transformations=SOME_IP_Default_Transformation, data-type-policy=TRANSFORMING-I-SIGNAL, someip-transformation-i-signal-props{transformer=SOME_IP_Default_Transformer, message-type=RESPONSE}, transfer-property=TRIGGERED, to ICC_8155_QNX
  pdu SIGIPDU_RR_GetUUIDCodeResponse_call_Cis_TBOX_FCM_UUID: has-dynamic-length=false, length=9, transmission-mode-true-timing=event-controlled-timing=number-of-repetitions=0
    signal SIG_RR_GetUUIDCodeResponse_call_Cis_TBOX_FCM_UUID: start 0, 8 bit, opaque, data-transformations=SOME_IP_Default_Transformation, data-type-policy=TRANSFORMING-I-SIGNAL, someip-transformation-i-signal-props{transformer=SOME_IP_Default_Transformer, message-type=REQUEST}, transfer-property=TRIGGERED, to FCM
  pdu SIGIPDU_RR_GetUUIDCodeResponse_return_Cis_TBOX_FCM_UUID: has-dynamic-length=false, length=140, transmission-mode-true-timing=event-controlled-timing=number-of-repetitions=0
    signal SIG_RR_GetUUIDCodeResponse_return_Cis_TBOX_FCM_UUID: start 0, 1056 bit, opaque, data-transformations=SOME_IP_Default_Transformation, data-type-policy=TRANSFORMING-I-SIGNAL, someip-transformation-i-signal-props{transformer=SOME_IP_Default_Transformer, message-type=RESPONSE}, transfer-property=TRIGGERED, to TBOX
  pdu SIGIPDU_RR_GetUUIDCodeResponse_call_Cis_ADCC_FCM_UUID: has-dynamic-length=false, length=9, transmission-mode-true-timing=event-controlled-timing=number-of-repetitions=0
    signal SIG_RR_GetUUIDCodeResponse_call_Cis_ADCC_FCM_UUID: start 0, 8 bit, opaque, data-transformations=SOME_IP_Default_Transformation, data-type-policy=TRANSFORMING-I-SIGNAL, someip-transformation-i-signal-props{transformer=SOME_IP_Default_Transformer, message-type=REQUEST}, transfer-property=TRIGGERED, to FCM
  pdu SIGIPDU_RR_GetUUIDCodeResponse_return_Cis_ADCC_FCM_UUID: has-dynamic-length=false, length=140, transmission-mode-true-timing=event-controlled-timing=number-of-repetitions=0
    signal SIG_RR_GetUUIDCodeResponse_return_Cis_ADCC_FCM_UUID: start 0, 1056 bit, opaque, data-transformations=SOME_IP_Default_Transformation, data-type-policy=TRANSFORMING-I-SIGNAL, someip-transformation-i-signal-props{transformer=SOME_IP_Default_Transformer, message-type=RESPONSE}, transfer-property=TRIGGERED, to ADCC
  pdu SIGIPDU_RR_GetUUIDCodeResponse_call_Cis_LCM_FCM_UUID: has-dynamic-length=false, length=9, transmission-mode-true-timing=event-controlled-timing=number-of-repetitions=0
    signal SIG_RR_GetUUIDCodeResponse_call_Cis_LCM_FCM_UUID: start 0, 8 bit, opaque, data-transformations=SOME_IP_Default_Transformation, data-type-policy=TRANSFORMING-I-SIGNAL, someip-transformation-i-signal-props{transformer=SOME_IP_Default_Transformer, message-type=REQUEST}, transfer-property=TRIGGERED, to FCM
  pdu SIGIPDU_RR_GetUUIDCodeResponse_return_Cis_LCM_FCM_UUID: has-dynamic-length=false, length=140, transmission-mode-true-timing=event-controlled-timing=number-of-repetitions=0
    signal SIG_RR_GetUUIDCodeResponse_return_Cis_LCM_FCM_UUID: start 0, 1056 bit, opaque, data-transformations=SOME_IP_Default_Transformation, data-type-policy=TRANSFORMING-I-SIGNAL, someip-transformation-i-signal-props{transformer=SOME_IP_Default_Transformer, message-type=RESPONSE}, transfer-property=TRIGGERED, to LCM
  pdu SIGIPDU_RR_GetUUIDCodeResponse_call_Cis_ICC_8155_Android_FCM_UUID: has-dynamic-length=false, length=9, transmission-mode-true-timing=event-controlled-timing=number-of-repetitions=0
    signal SIG_RR_GetUUIDCodeResponse_call_Cis_ICC_8155_Android_FCM_UUID: start 0, 8 bit, opaque, data-transformations=SOME_IP_Default_Transformation, data-type-policy=TRANSFORMING-I-SIGNAL, someip-transformation-i-signal-props{transformer=SOME_IP_Default_Transformer, message-type=REQUEST}, transfer-property=TRIGGERED, to FCM
  pdu SIGIPDU_RR_GetUUIDCodeResponse_return_Cis_ICC_8155_Android_FCM_UUID: has-dynamic-length=false, length=140, transmission-mode-true-timing=event-controlled-timing=number-of-repetitions=0
    signal SIG_RR_GetUUIDCodeResponse_return_Cis_ICC_8155_Android_FCM_UUID: start 0, 1056 bit, opaque, data-transformations=SOME_IP_Default_Transformation, data-type-policy=TRANSFORMING-I-SIGNAL, someip-transformation-i-signal-props{transformer=SOME_IP_Default_Transformer, message-type=RESPONSE}, transfer-property=TRIGGERED, to ICC_8155_Android
  pdu SIGIPDU_Event_NtfIMUInfo_LCM_ICC_Data: has-dynamic-length=false, length=40, transmission-mode-true-timing=event-controlled-timing=number-of-repetitions=0
    signal SIG_Event_NtfIMUInfo_LCM_ICC_Data: start 0, 256 bit, opaque, data-transformations=SOME_IP_Default_Transformation, data-type-policy=TRANSFORMING-I-SIGNAL, someip-transformation-i-signal-props{transformer=SOME_IP_Default_Transformer, message-type=NOTIFICATION}, transfer-property=TRIGGERED, to ICC_8155_QNX
  pdu SIGIPDU_Event_NtfGRawInfo_LCM_ADCC_RawData: has-dynamic-length=true, length=1036, transmission-mode-true-timing=event-controlled-timing=number-of-repetitions=0
    signal SIG_Event_NtfGRawInfo_LCM_ADCC_RawData: start 0, 8224 bit, opaque, data-transformations=SOME_IP_Default_Transformation, data-type-policy=TRANSFORMING-I-SIGNAL, someip-transformation-i-signal-props{transformer=SOME_IP_Default_Transformer, message-type=NOTIFICATION}, dynamic-length=true, transfer-property=TRIGGERED, to ADCC
  pdu SIGIPDU_Event_NtfActiveSafetyFcnInfo_Act_ADCC_ActiveSafetyInfo: has-dynamic-length=false, length=27, transmission-mode-true-timing=event-controlled-timing=number-of-repetitions=0
    signal SIG_Event_NtfActiveSafetyFcnInfo_Act_ADCC_ActiveSafetyInfo: start 0, 40 bit, opaque, data-transformations=SOMEIP_E2E_Transformer_PROFILE_04_B, data-type-policy=TRANSFORMING-I-SIGNAL, transfer-property=TRIGGERED, to ICC_8155_Android
  pdu SIGIPDU_Event_NtfAEBTargetObjInfo_Act_ADCC_ActiveSafetyInfo: has-dynamic-length=false, length=24, transmission-mode-true-timing=event-controlled-timing=number-of-repetitions=0
    signal SIG_Event_NtfAEBTargetObjInfo_Act_ADCC_ActiveSafetyInfo: start 0, 128 bit, opaque, data-transformations=SOME_IP_Default_Transformation, data-type-policy=TRANSFORMING-I-SIGNAL, someip-transformation-i-signal-props{transformer=SOME_IP_Default_Transformer, message-type=NOTIFICATION}, transfer-property=TRIGGERED, to ICC_8155_Android
  pdu SIGIPDU_Event_NtfActiveSafetyFcnInfo_Act_2_ADCC_ActiveSafetyInfo: has-dynamic-length=false, length=64, transmission-mode-true-timing=event-controlled-timing=number-of-repetitions=0
    signal SIG_Event_NtfActiveSafetyFcnInfo_Act_2_ADCC_ActiveSafetyInfo: start 0, 448 bit, opaque, data-transformations=SOME_IP_Default_Transformation, data-type-policy=TRANSFORMING-I-SIGNAL, someip-transformation-i-signal-props{transformer=SOME_IP_Default_Transformer, message-type=NOTIFICATION}, transfer-property=TRIGGERED, to ICC_8155_Android
  pdu SIGIPDU_Event_NtfAEBTargetObjInfo_Act_2_ADCC_ActiveSafetyInfo: has-dynamic-length=true, length=92, transmission-mode-true-timing=event-controlled-timing=number-of-repetitions=0
    signal SIG_Event_NtfAEBTargetObjInfo_Act_2_ADCC_ActiveSafetyInfo: start 0, 672 bit, opaque, data-transformations=SOME_IP_Default_Transformation, data-type-policy=TRANSFORMING-I-SIGNAL, someip-transformation-i-signal-props{transformer=SOME_IP_Default_Transformer, message-type=NOTIFICATION}, dynamic-length=true, transfer-property=TRIGGERED, to ICC_8155_Android
  pdu SIGIPDU_Event_NtfAEBTargetObjInfo_Act_3_ADCC_ActiveSafetyInfo: has-dynamic-length=false, length=32, transmission-mode-true-timing=event-controlled-timing=number-of-repetitions=0
    signal SIG_Event_NtfAEBTargetObjInfo_Act_3_ADCC_ActiveSafetyInfo: start 0, 192 bit, opaque, data-transformations=SOME_IP_Default_Transformation, data-type-policy=TRANSFORMING-I-SIGNAL, someip-transformation-i-signal-props{transformer=SOME_IP_Default_Transformer, message-type=NOTIFICATION}, transfer-property=TRIGGERED, to ICC_8155_Android
  pdu SIGIPDU_Event_NtfActiveSafetyFcnInfo_Act_ADCC_ActiveSafetyInfo_1: has-dynamic-length=false, length=27, transmission-mode-true-timing=event-controlled-timing=number-of-repetitions=0
    signal SIG_Event_NtfActiveSafetyFcnInfo_Act_ADCC_ActiveSafetyInfo_1: start 0, 40 bit, opaque, data-transformations=SOMEIP_E2E_Transformer_PROFILE_04_B, data-type-policy=TRANSFORMING-I-SIGNAL, transfer-property=TRIGGERED, to ICC_8155_QNX
  pdu SIGIPDU_Event_NtfAEBTargetObjInfo_Act_ADCC_ActiveSafetyInfo_1: has-dynamic-length=false, length=24, transmission-mode-true-timing=event-controlled-timing=number-of-repetitions=0
    signal SIG_Event_NtfAEBTargetObjInfo_Act_ADCC_ActiveSafetyInfo_1: start 0, 128 bit, opaque, data-transformations=SOME_IP_Default_Transformation, data-type-policy=TRANSFORMING-I-SIGNAL, someip-transformation-i-signal-props{transformer=SOME_IP_Default_Transformer, message-type=NOTIFICATION}, transfer-property=TRIGGERED, to ICC_8155_QNX
  pdu SIGIPDU_Event_NtfActiveSafetyFcnInfo_Act_2_ADCC_ActiveSafetyInfo_1: has-dynamic-length=false, length=64, transmission-mode-true-timing=event-controlled-timing=number-of-repetitions=0
    signal SIG_Event_NtfActiveSafetyFcnInfo_Act_2_ADCC_ActiveSafetyInfo_1: start 0, 448 bit, opaque, data-transformations=SOME_IP_Default_Transformation, data-type-policy=TRANSFORMING-I-SIGNAL, someip-transformation-i-signal-props{transformer=SOME_IP_Default_Transformer, message-type=NOTIFICATION}, transfer-property=TRIGGERED, to ICC_8155_QNX
  pdu SIGIPDU_Event_NtfAEBTargetObjInfo_Act_2_ADCC_ActiveSafetyInfo_1: has-dynamic-length=true, length=92, transmission-mode-true-timing=event-controlled-timing=number-of-repetitions=0
    signal SIG_Event_NtfAEBTargetObjInfo_Act_2_ADCC_ActiveSafetyInfo_1: start 0, 672 bit, opaque, data-transformations=SOME_IP_Default_Transformation, data-type-policy=TRANSFORMING-I-SIGNAL, someip-transformation-i-signal-props{transformer=SOME_IP_Default_Transformer, message-type=NOTIFICATION}, dynamic-length=true, transfer-property=TRIGGERED, to ICC_8155_QNX
  pdu SIGIPDU_Event_NtfAEBTargetObjInfo_Act_3_ADCC_ActiveSafetyInfo_1: has-dynamic-length=false, length=32, transmission-mode-true-timing=event-controlled-timing=number-of-repetitions=0
    signal SIG_Event_NtfAEBTargetObjInfo_Act_3_ADCC_ActiveSafetyInfo_1: start 0, 192 bit, opaque, data-transformations=SOME_IP_Default_Transformation, data-type-policy=TRANSFORMING-I-SIGNAL, someip-transformation-i-signal-props{transformer=SOME_IP_Default_Transformer, message-type=NOTIFICATION}, transfer-property=TRIGGERED, to ICC_8155_QNX
  pdu SIGIPDU_RR_GetUUIDCodeResponse_UUID_call_Cis_TBOX_ADCC_UUID: has-dynamic-length=false, length=9, transmission-mode-true-timing=event-controlled-timing=number-of-repetitions=0
    signal SIG_RR_GetUUIDCodeResponse_UUID_call_Cis_TBOX_ADCC_UUID: start 0, 8 bit, opaque, data-transformations=SOME_IP_Default_Transformation, data-type-policy=TRANSFORMING-I-SIGNAL, someip-transformation-i-signal-props{transformer=SOME_IP_Default_Transformer, message-type=REQUEST}, transfer-property=TRIGGERED, to ADCC
  pdu SIGIPDU_RR_GetUUIDCodeResponse_UUID_return_Cis_TBOX_ADCC_UUID: has-dynamic-length=false, length=140, transmission-mode-true-timing=event-controlled-timing=number-of-repetitions=0
    signal SIG_RR_GetUUIDCodeResponse_UUID_return_Cis_TBOX_ADCC_UUID: start 0, 1056 bit, opaque, data-transformations=SOME_IP_Default_Transformation, data-type-policy=TRANSFORMING-I-SIGNAL, someip-transformation-i-signal-props{transformer=SOME_IP_Default_Transformer, message-type=RESPONSE}, transfer-property=TRIGGERED, to TBOX
  pdu SIGIPDU_RR_GetUUIDCodeResponse_UUID_call_Cis_LCM_ADCC_UUID: has-dynamic-length=false, length=9, transmission-mode-true-timing=event-controlled-timing=number-of-repetitions=0
    signal SIG_RR_GetUUIDCodeResponse_UUID_call_Cis_LCM_ADCC_UUID: start 0, 8 bit, opaque, data-transformations=SOME_IP_Default_Transformation, data-type-policy=TRANSFORMING-I-SIGNAL, someip-transformation-i-signal-props{transformer=SOME_IP_Default_Transformer, message-type=REQUEST}, transfer-property=TRIGGERED, to ADCC
  pdu SIGIPDU_RR_GetUUIDCodeResponse_UUID_return_Cis_LCM_ADCC_UUID: has-dynamic-length=false, length=140, transmission-mode-true-timing=event-controlled-timing=number-of-repetitions=0
    signal SIG_RR_GetUUIDCodeResponse_UUID_return_Cis_LCM_ADCC_UUID: start 0, 1056 bit, opaque, data-transformations=SOME_IP_Default_Transformation, data-type-policy=TRANSFORMING-I-SIGNAL, someip-transformation-i-signal-props{transformer=SOME_IP_Default_Transformer, message-type=RESPONSE}, transfer-property=TRIGGERED, to LCM
  pdu SIGIPDU_RR_GetUUIDCodeResponse_UUID_call_Cis_ICC_8155_Android_ADCC_UUID: has-dynamic-length=false, length=9, transmission-mode-true-timing=event-controlled-timing=number-of-repetitions=0
    signal SIG_RR_GetUUIDCodeResponse_UUID_call_Cis_ICC_8155_Android_ADCC_UUID: start 0, 8 bit, opaque, data-transformations=SOME_IP_Default_Transformation, data-type-policy=TRANSFORMING-I-SIGNAL, someip-transformation-i-signal-props{transformer=SOME_IP_Default_Transformer, message-type=REQUEST}, transfer-property=TRIGGERED, to ADCC
  pdu SIGIPDU_RR_GetUUIDCodeResponse_UUID_return_Cis_ICC_8155_Android_ADCC_UUID: has-dynamic-length=false, length=140, transmission-mode-true-timing=event-controlled-timing=number-of-repetitions=0
    signal SIG_RR_GetUUIDCodeResponse_UUID_return_Cis_ICC_8155_Android_ADCC_UUID: start 0, 1056 bit, opaque, data-transformations=SOME_IP_Default_Transformation, data-type-policy=TRANSFORMING-I-SIGNAL, someip-transformation-i-signal-props{transformer=SOME_IP_Default_Transformer, message-type=RESPONSE}, transfer-property=TRIGGERED, to ICC_8155_Android
  pdu SIGIPDU_Event_NtfSensorSt_FCM_FCM_SensorInfo: has-dynamic-length=false, length=37, transmission-mode-true-timing=event-controlled-timing=number-of-repetitions=0
    signal SIG_Event_NtfSensorSt_FCM_FCM_SensorInfo: start 0, 232 bit, opaque, data-transformations=SOME_IP_Default_Transformation, data-type-policy=TRANSFORMING-I-SIGNAL, someip-transformation-i-signal-props{transformer=SOME_IP_Default_Transformer, message-type=NOTIFICATION}, transfer-property=TRIGGERED, to ICC_8155_Android
  pdu SIGIPDU_Event_NtfSensorSt_FCM_FCM_SensorInfo_1: has-dynamic-length=false, length=37, transmission-mode-true-timing=event-controlled-timing=number-of-repetitions=0
    signal SIG_Event_NtfSensorSt_FCM_FCM_SensorInfo_1: start 0, 232 bit, opaque, data-transformations=SOME_IP_Default_Transformation, data-type-policy=TRANSFORMING-I-SIGNAL, someip-transformation-i-signal-props{transformer=SOME_IP_Default_Transformer, message-type=NOTIFICATION}, transfer-property=TRIGGERED, to ICC_8155_QNX
  pdu SIGIPDU_Event_Event_NetworkStatus_ICC_TBOX_SystemInfo_ICC: has-dynamic-length=false, length=88, transmission-mode-true-timing=event-controlled-timing=number-of-repetitions=0
    signal SIG_Event_Event_NetworkStatus_ICC_TBOX_SystemInfo_ICC: start 0, 640 bit, opaque, data-transformations=SOME_IP_Default_Transformation, data-type-policy=TRANSFORMING-I-SIGNAL, someip-transformation-i-signal-props{transformer=SOME_IP_Default_Transformer, message-type=NOTIFICATION}, transfer-property=TRIGGERED, to ADCC
  pdu SIGIPDU_RR_RR_SIMCardinfo_ICC_call_Cis_ADCC_TBOX_SystemInfo_ICC: has-dynamic-length=true, length=8, transmission-mode-true-timing=event-controlled-timing=number-of-repetitions=0
    signal SIG_RR_RR_SIMCardinfo_ICC_call_Cis_ADCC_TBOX_SystemInfo_ICC: start 0, 0 bit, opaque, data-transformations=SOME_IP_Default_Transformation, data-type-policy=TRANSFORMING-I-SIGNAL, someip-transformation-i-signal-props{transformer=SOME_IP_Default_Transformer, message-type=REQUEST}, dynamic-length=true, transfer-property=TRIGGERED, to ICC_8155_QNX
  pdu SIGIPDU_RR_RR_SIMCardinfo_ICC_return_Cis_ADCC_TBOX_SystemInfo_ICC: has-dynamic-length=false, length=76, transmission-mode-true-timing=event-controlled-timing=number-of-repetitions=0
    signal SIG_RR_RR_SIMCardinfo_ICC_return_Cis_ADCC_TBOX_SystemInfo_ICC: start 0, 544 bit, opaque, data-transformations=SOME_IP_Default_Transformation, data-type-policy=TRANSFORMING-I-SIGNAL, someip-transformation-i-signal-props{transformer=SOME_IP_Default_Transformer, message-type=RESPONSE}, transfer-property=TRIGGERED, to ADCC
  pdu SIGIPDU_RR_RR_TSPConnectionState_ICC_call_Cis_ADCC_TBOX_SystemInfo_ICC: has-dynamic-length=true, length=8, transmission-mode-true-timing=event-controlled-timing=number-of-repetitions=0
    signal SIG_RR_RR_TSPConnectionState_ICC_call_Cis_ADCC_TBOX_SystemInfo_ICC: start 0, 0 bit, opaque, data-transformations=SOME_IP_Default_Transformation, data-type-policy=TRANSFORMING-I-SIGNAL, someip-transformation-i-signal-props{transformer=SOME_IP_Default_Transformer, message-type=REQUEST}, dynamic-length=true, transfer-property=TRIGGERED, to ICC_8155_QNX
  pdu SIGIPDU_RR_RR_TSPConnectionState_ICC_return_Cis_ADCC_TBOX_SystemInfo_ICC: has-dynamic-length=false, length=9, transmission-mode-true-timing=event-controlled-timing=number-of-repetitions=0
    signal SIG_RR_RR_TSPConnectionState_ICC_return_Cis_ADCC_TBOX_SystemInfo_ICC: start 0, 8 bit, opaque, data-transformations=SOME_IP_Default_Transformation, data-type-policy=TRANSFORMING-I-SIGNAL, someip-transformation-i-signal-props{transformer=SOME_IP_Default_Transformer, message-type=RESPONSE}, transfer-property=TRIGGERED, to ADCC
  pdu SIGIPDU_RR_RR_KL15State_ICC_call_Cis_ADCC_TBOX_SystemInfo_ICC: has-dynamic-length=true, length=8, transmission-mode-true-timing=event-controlled-timing=number-of-repetitions=0
    signal SIG_RR_RR_KL15State_ICC_call_Cis_ADCC_TBOX_SystemInfo_ICC: start 0, 0 bit, opaque, data-transformations=SOME_IP_Default_Transformation, data-type-policy=TRANSFORMING-I-SIGNAL, someip-transformation-i-signal-props{transformer=SOME_IP_Default_Transformer, message-type=REQUEST}, dynamic-length=true, transfer-property=TRIGGERED, to ICC_8155_QNX
  pdu SIGIPDU_RR_RR_KL15State_ICC_return_Cis_ADCC_TBOX_SystemInfo_ICC: has-dynamic-length=false, length=9, transmission-mode-true-timing=event-controlled-timing=number-of-repetitions=0
    signal SIG_RR_RR_KL15State_ICC_return_Cis_ADCC_TBOX_SystemInfo_ICC: start 0, 8 bit, opaque, data-transformations=SOME_IP_Default_Transformation, data-type-policy=TRANSFORMING-I-SIGNAL, someip-transformation-i-signal-props{transformer=SOME_IP_Default_Transformer, message-type=RESPONSE}, transfer-property=TRIGGERED, to ADCC
  pdu SIGIPDU_Event_notifyDVRSts_ADCC_ADCC_DVRSts: has-dynamic-length=false, length=9, transmission-mode-true-timing=event-controlled-timing=number-of-repetitions=0
    signal SIG_Event_notifyDVRSts_ADCC_ADCC_DVRSts: start 0, 8 bit, opaque, data-transformations=SOME_IP_Default_Transformation, data-type-policy=TRANSFORMING-I-SIGNAL, someip-transformation-i-signal-props{transformer=SOME_IP_Default_Transformer, message-type=NOTIFICATION}, transfer-property=TRIGGERED, to ICC_8155_Android
  pdu SIGIPDU_Event_notifyDVRcameraSts_ADCC_ADCC_DVRSts: has-dynamic-length=false, length=9, transmission-mode-true-timing=event-controlled-timing=number-of-repetitions=0
    signal SIG_Event_notifyDVRcameraSts_ADCC_ADCC_DVRSts: start 0, 8 bit, opaque, data-transformations=SOME_IP_Default_Transformation, data-type-policy=TRANSFORMING-I-SIGNAL, someip-transformation-i-signal-props{transformer=SOME_IP_Default_Transformer, message-type=NOTIFICATION}, transfer-property=TRIGGERED, to ICC_8155_Android
  pdu SIGIPDU_Event_notifyCameraInterParm_ADCC_ADCC_DVRSts: has-dynamic-length=false, length=104, transmission-mode-true-timing=event-controlled-timing=number-of-repetitions=0
    signal SIG_Event_notifyCameraInterParm_ADCC_ADCC_DVRSts: start 0, 768 bit, opaque, data-transformations=SOME_IP_Default_Transformation, data-type-policy=TRANSFORMING-I-SIGNAL, someip-transformation-i-signal-props{transformer=SOME_IP_Default_Transformer, message-type=NOTIFICATION}, transfer-property=TRIGGERED, to ICC_8155_Android
  pdu SIGIPDU_RR_getCameraInterParm_ADCC_call_Cis_ICC_8155_Android_ADCC_DVRSts: has-dynamic-length=true, length=8, transmission-mode-true-timing=event-controlled-timing=number-of-repetitions=0
    signal SIG_RR_getCameraInterParm_ADCC_call_Cis_ICC_8155_Android_ADCC_DVRSts: start 0, 0 bit, opaque, data-transformations=SOME_IP_Default_Transformation, data-type-policy=TRANSFORMING-I-SIGNAL, someip-transformation-i-signal-props{transformer=SOME_IP_Default_Transformer, message-type=REQUEST}, dynamic-length=true, transfer-property=TRIGGERED, to ADCC
  pdu SIGIPDU_RR_getCameraInterParm_ADCC_return_Cis_ICC_8155_Android_ADCC_DVRSts: has-dynamic-length=false, length=104, transmission-mode-true-timing=event-controlled-timing=number-of-repetitions=0
    signal SIG_RR_getCameraInterParm_ADCC_return_Cis_ICC_8155_Android_ADCC_DVRSts: start 0, 768 bit, opaque, data-transformations=SOME_IP_Default_Transformation, data-type-policy=TRANSFORMING-I-SIGNAL, someip-transformation-i-signal-props{transformer=SOME_IP_Default_Transformer, message-type=RESPONSE}, transfer-property=TRIGGERED, to ICC_8155_Android
  pdu SIGIPDU_Event_notifyDVRSts_ADCC_ADCC_DVRSts_1: has-dynamic-length=false, length=9, transmission-mode-true-timing=event-controlled-timing=number-of-repetitions=0
    signal SIG_Event_notifyDVRSts_ADCC_ADCC_DVRSts_1: start 0, 8 bit, opaque, data-transformations=SOME_IP_Default_Transformation, data-type-policy=TRANSFORMING-I-SIGNAL, someip-transformation-i-signal-props{transformer=SOME_IP_Default_Transformer, message-type=NOTIFICATION}, transfer-property=TRIGGERED, to ICC_8155_QNX
  pdu SIGIPDU_Event_notifyDVRcameraSts_ADCC_ADCC_DVRSts_1: has-dynamic-length=false, length=9, transmission-mode-true-timing=event-controlled-timing=number-of-repetitions=0
    signal SIG_Event_notifyDVRcameraSts_ADCC_ADCC_DVRSts_1: start 0, 8 bit, opaque, data-transformations=SOME_IP_Default_Transformation, data-type-policy=TRANSFORMING-I-SIGNAL, someip-transformation-i-signal-props{transformer=SOME_IP_Default_Transformer, message-type=NOTIFICATION}, transfer-property=TRIGGERED, to ICC_8155_QNX
  pdu SIGIPDU_Event_notifyCameraInterParm_ADCC_ADCC_DVRSts_1: has-dynamic-length=false, length=104, transmission-mode-true-timing=event-controlled-timing=number-of-repetitions=0
    signal SIG_Event_notifyCameraInterParm_ADCC_ADCC_DVRSts_1: start 0, 768 bit, opaque, data-transformations=SOME_IP_Default_Transformation, data-type-policy=TRANSFORMING-I-SIGNAL, someip-transformation-i-signal-props{transformer=SOME_IP_Default_Transformer, message-type=NOTIFICATION}, transfer-property=TRIGGERED, to ICC_8155_QNX
  pdu SIGIPDU_RR_getCameraInterParm_ADCC_call_Cis_ICC_8155_QNX_ADCC_DVRSts: has-dynamic-length=true, length=8, transmission-mode-true-timing=event-controlled-timing=number-of-repetitions=0
    signal SIG_RR_getCameraInterParm_ADCC_call_Cis_ICC_8155_QNX_ADCC_DVRSts: start 0, 0 bit, opaque, data-transformations=SOME_IP_Default_Transformation, data-type-policy=TRANSFORMING-I-SIGNAL, someip-transformation-i-signal-props{transformer=SOME_IP_Default_Transformer, message-type=REQUEST}, dynamic-length=true, transfer-property=TRIGGERED, to ADCC
  pdu SIGIPDU_RR_getCameraInterParm_ADCC_return_Cis_ICC_8155_QNX_ADCC_DVRSts: has-dynamic-length=false, length=104, transmission-mode-true-timing=event-controlled-timing=number-of-repetitions=0
    signal SIG_RR_getCameraInterParm_ADCC_return_Cis_ICC_8155_QNX_ADCC_DVRSts: start 0, 768 bit, opaque, data-transformations=SOME_IP_Default_Transformation, data-type-policy=TRANSFORMING-I-SIGNAL, someip-transformation-i-signal-props{transformer=SOME_IP_Default_Transformer, message-type=RESPONSE}, transfer-property=TRIGGERED, to ICC_8155_QNX
  pdu SIGIPDU_Event_notifyData_ID_ADAS_DataInLoop: has-dynamic-length=false, length=12, transmission-mode-true-timing=event-controlled-timing=number-of-repetitions=0
    signal SIG_Event_notifyData_ID_ADAS_DataInLoop: start 0, 32 bit, opaque, data-transformations=SOME_IP_Default_Transformation, data-type-policy=TRANSFORMING-I-SIGNAL, someip-transformation-i-signal-props{transformer=SOME_IP_Default_Transformer, message-type=NOTIFICATION}, transfer-property=TRIGGERED, to ICC_8155_Android
  pdu SIGIPDU_Event_notifyDataInLoop_1_ADAS_DataInLoop: has-dynamic-length=false, length=1208, transmission-mode-true-timing=event-controlled-timing=number-of-repetitions=0
    signal SIG_Event_notifyDataInLoop_1_ADAS_DataInLoop: start 0, 9600 bit, opaque, data-transformations=SOME_IP_Default_Transformation, data-type-policy=TRANSFORMING-I-SIGNAL, someip-transformation-i-signal-props{transformer=SOME_IP_Default_Transformer, message-type=NOTIFICATION}, transfer-property=TRIGGERED, to ICC_8155_Android
  pdu SIGIPDU_Event_notifyDataInLoop_2_ADAS_DataInLoop: has-dynamic-length=false, length=1208, transmission-mode-true-timing=event-controlled-timing=number-of-repetitions=0
    signal SIG_Event_notifyDataInLoop_2_ADAS_DataInLoop: start 0, 9600 bit, opaque, data-transformations=SOME_IP_Default_Transformation, data-type-policy=TRANSFORMING-I-SIGNAL, someip-transformation-i-signal-props{transformer=SOME_IP_Default_Transformer, message-type=NOTIFICATION}, transfer-property=TRIGGERED, to ICC_8155_Android
  pdu SIGIPDU_Event_notifyDataInLoop_3_ADAS_DataInLoop: has-dynamic-length=false, length=1208, transmission-mode-true-timing=event-controlled-timing=number-of-repetitions=0
    signal SIG_Event_notifyDataInLoop_3_ADAS_DataInLoop: start 0, 9600 bit, opaque, data-transformations=SOME_IP_Default_Transformation, data-type-policy=TRANSFORMING-I-SIGNAL, someip-transformation-i-signal-props{transformer=SOME_IP_Default_Transformer, message-type=NOTIFICATION}, transfer-property=TRIGGERED, to ICC_8155_Android
  pdu SIGIPDU_Event_notifyDataInLoop_ADAS_DataInLoop: has-dynamic-length=false, length=1208, transmission-mode-true-timing=event-controlled-timing=number-of-repetitions=0
    signal SIG_Event_notifyDataInLoop_ADAS_DataInLoop: start 0, 9600 bit, opaque, data-transformations=SOME_IP_Default_Transformation, data-type-policy=TRANSFORMING-I-SIGNAL, someip-transformation-i-signal-props{transformer=SOME_IP_Default_Transformer, message-type=NOTIFICATION}, transfer-property=TRIGGERED, to ICC_8155_Android
  pdu SIGIPDU_Event_notifyUnixTimestamp_IVI_UnixTimestamp: has-dynamic-length=false, length=16, transmission-mode-true-timing=event-controlled-timing=number-of-repetitions=0
    signal SIG_Event_notifyUnixTimestamp_IVI_UnixTimestamp: start 0, 64 bit, opaque, data-transformations=SOME_IP_Default_Transformation, data-type-policy=TRANSFORMING-I-SIGNAL, someip-transformation-i-signal-props{transformer=SOME_IP_Default_Transformer, message-type=NOTIFICATION}, transfer-property=TRIGGERED, to FCM
  pdu SIGIPDU_Event_notifyGNSSInfo_ADAS_GNSSInfo: has-dynamic-length=false, length=4122, transmission-mode-true-timing=event-controlled-timing=number-of-repetitions=0
    signal SIG_Event_notifyGNSSInfo_ADAS_GNSSInfo: start 0, 32912 bit, opaque, data-transformations=SOME_IP_Default_Transformation, data-type-policy=TRANSFORMING-I-SIGNAL, someip-transformation-i-signal-props{transformer=SOME_IP_Default_Transformer, message-type=NOTIFICATION}, transfer-property=TRIGGERED, to ICC_8155_Android
  general purpose i pdu TPSIGIPDU_Event_notifyGNSSInfo_ADAS_GNSSInfo: category=SOMEIP_SEGMENTED_IPDU, length=1400
  pdu SIGIPDU_RR_RR_ADASGNSSType_call_Cis_ICC_8155_Android_ADAS_GNSSInfo: has-dynamic-length=false, length=9, transmission-mode-true-timing=event-controlled-timing=number-of-repetitions=0
    signal SIG_RR_RR_ADASGNSSType_call_Cis_ICC_8155_Android_ADAS_GNSSInfo: start 0, 8 bit, opaque, data-transformations=SOME_IP_Default_Transformation, data-type-policy=TRANSFORMING-I-SIGNAL, someip-transformation-i-signal-props{transformer=SOME_IP_Default_Transformer, message-type=REQUEST}, transfer-property=TRIGGERED, to ADCC
  pdu SIGIPDU_RR_RR_ADASGNSSType_return_Cis_ICC_8155_Android_ADAS_GNSSInfo: has-dynamic-length=false, length=9, transmission-mode-true-timing=event-controlled-timing=number-of-repetitions=0
    signal SIG_RR_RR_ADASGNSSType_return_Cis_ICC_8155_Android_ADAS_GNSSInfo: start 0, 8 bit, opaque, data-transformations=SOME_IP_Default_Transformation, data-type-policy=TRANSFORMING-I-SIGNAL, someip-transformation-i-signal-props{transformer=SOME_IP_Default_Transformer, message-type=RESPONSE}, transfer-property=TRIGGERED, to ICC_8155_Android
  pdu SIGIPDU_Event_notifyGNSSInfo_ADAS_GNSSInfo_1: has-dynamic-length=false, length=4122, transmission-mode-true-timing=event-controlled-timing=number-of-repetitions=0
    signal SIG_Event_notifyGNSSInfo_ADAS_GNSSInfo_1: start 0, 32912 bit, opaque, data-transformations=SOME_IP_Default_Transformation, data-type-policy=TRANSFORMING-I-SIGNAL, someip-transformation-i-signal-props{transformer=SOME_IP_Default_Transformer, message-type=NOTIFICATION}, transfer-property=TRIGGERED, to ICC_8155_QNX
  general purpose i pdu TPSIGIPDU_Event_notifyGNSSInfo_ADAS_GNSSInfo_1: category=SOMEIP_SEGMENTED_IPDU, length=1400
  pdu SIGIPDU_RR_RR_ADASGNSSType_call_Cis_ICC_8155_QNX_ADAS_GNSSInfo: has-dynamic-length=false, length=9, transmission-mode-true-timing=event-controlled-timing=number-of-repetitions=0
    signal SIG_RR_RR_ADASGNSSType_call_Cis_ICC_8155_QNX_ADAS_GNSSInfo: start 0, 8 bit, opaque, data-transformations=SOME_IP_Default_Transformation, data-type-policy=TRANSFORMING-I-SIGNAL, someip-transformation-i-signal-props{transformer=SOME_IP_Default_Transformer, message-type=REQUEST}, transfer-property=TRIGGERED, to ADCC
  pdu SIGIPDU_RR_RR_ADASGNSSType_return_Cis_ICC_8155_QNX_ADAS_GNSSInfo: has-dynamic-length=false, length=9, transmission-mode-true-timing=event-controlled-timing=number-of-repetitions=0
    signal SIG_RR_RR_ADASGNSSType_return_Cis_ICC_8155_QNX_ADAS_GNSSInfo: start 0, 8 bit, opaque, data-transformations=SOME_IP_Default_Transformation, data-type-policy=TRANSFORMING-I-SIGNAL, someip-transformation-i-signal-props{transformer=SOME_IP_Default_Transformer, message-type=RESPONSE}, transfer-property=TRIGGERED, to ICC_8155_QNX
package /SoftwareTypes/ComponentTypes
  composition sw component type RootCompositionType
    component AM_CompositionPrototype67: type=AM_CompositionPrototype67
  composition sw component type AM_CompositionPrototype67
    101 x component:
      eHMI_ParkingUI_Provider: type=eHMI_ParkingUI_Provider
      eHMI_ParkingUIConsumer_ADCC: type=eHMI_ParkingUI_Consumer
      eHMI_ADASSetting_Provider: type=eHMI_ADASSetting_Provider
      eHMI_ADASSettingConsumer_ADCC: type=eHMI_ADASSetting_Consumer
      eHMI_ADASSettingConsumer_FCM: type=eHMI_ADASSetting_Consumer
      eHMI_DVRSet_Provider: type=eHMI_DVRSet_Provider
      eHMI_DVRSetConsumer_FCM: type=eHMI_DVRSet_Consumer
      TBOX_TimeManagement_Provider: type=TBOX_TimeManagement_Provider
      TBOX_TimeManagementConsumer_ICC_8155_Android: type=TBOX_TimeManagement_Consumer
      TBOX_ResSwtSts_Provider: type=TBOX_ResSwtSts_Provider
      TBOX_ResSwtStsConsumer_ICC_8155_Android: type=TBOX_ResSwtSts_Consumer
      TBOX_SystemInfo_Provider: type=TBOX_SystemInfo_Provider
      TBOX_SystemInfoConsumer_ADCC: type=TBOX_SystemInfo_Consumer
      TBOX_SystemInfoConsumer_LCM: type=TBOX_SystemInfo_Consumer
      TBOX_SystemInfoConsumer_ICC_8155_Android: type=TBOX_SystemInfo_Consumer
      TBOX_BEICALL_Provider: type=TBOX_BEICALL_Provider
      TBOX_BEICALLConsumer_ICC_8155_Android: type=TBOX_BEICALL_Consumer
      TBOX_USBUpdate_Provider: type=TBOX_USBUpdate_Provider
      TBOX_USBUpdateConsumer_ICC_8155_Android: type=TBOX_USBUpdate_Consumer
      TBOX_USBTBOXlog_Provider: type=TBOX_USBTBOXlog_Provider
      TBOX_USBTBOXlogConsumer_ICC_8155_Android: type=TBOX_USBTBOXlog_Consumer
      TBOX_GNSSInfo_Provider: type=TBOX_GNSSInfo_Provider
      TBOX_GNSSInfoConsumer_ICC_8155_Android: type=TBOX_GNSSInfo_Consumer
      TBOX_GNSSInfoConsumer_ADCC: type=TBOX_GNSSInfo_Consumer
      ICC_Android_OutService_Provider: type=ICC_Android_OutService_Provider
      ICC_Android_OutServiceConsumer_TBOX: type=ICC_Android_OutService_Consumer
      ICC_Aom_Provider: type=ICC_Aom_Provider
      ICC_AomConsumer_ADCC: type=ICC_Aom_Consumer
      ICC_SDmapInfo_Provider: type=ICC_SDmapInfo_Provider
      ICC_SDmapInfoConsumer_ADCC: type=ICC_SDmapInfo_Consumer
      ICC_SDmapInfoConsumer_FCM: type=ICC_SDmapInfo_Consumer
      ICC_SDmapInfo_2_Provider: type=ICC_SDmapInfo_2_Provider
      ICC_SDmapInfo_2Consumer_ADCC: type=ICC_SDmapInfo_2_Consumer
      ICC_SDmapInfo_2Consumer_FCM: type=ICC_SDmapInfo_2_Consumer
      ADCC_DrivingHmiEnv_Provider: type=ADCC_DrivingHmiEnv_Provider
      ADCC_DrivingHmiEnvConsumer_ICC_8155_Android: type=ADCC_DrivingHmiEnv_Consumer
      ADCC_DrivingHmiEnvConsumer_ICC_8155_QNX: type=ADCC_DrivingHmiEnv_Consumer
      ADCC_SensorInfo_Provider: type=ADCC_SensorInfo_Provider
      ADCC_SensorInfoConsumer_ICC_8155_Android: type=ADCC_SensorInfo_Consumer
      ADCC_SensorInfoConsumer_ICC_8155_QNX: type=ADCC_SensorInfo_Consumer
      ADCC_DrivingFuncInfo_Provider: type=ADCC_DrivingFuncInfo_Provider
      ADCC_DrivingFuncInfoConsumer_ICC_8155_Android: type=ADCC_DrivingFuncInfo_Consumer
      ADCC_DrivingFuncInfoConsumer_ICC_8155_QNX: type=ADCC_DrivingFuncInfo_Consumer
      ADCC_ParkingFuncInfo_Provider: type=ADCC_ParkingFuncInfo_Provider
      ADCC_ParkingFuncInfoConsumer_ICC_8155_Android: type=ADCC_ParkingFuncInfo_Consumer
      ADCC_ParkingFuncInfoConsumer_ICC_8155_QNX: type=ADCC_ParkingFuncInfo_Consumer
      ADCC_ParkingHmiEnv_Provider: type=ADCC_ParkingHmiEnv_Provider
      ADCC_ParkingHmiEnvConsumer_ICC_8155_Android: type=ADCC_ParkingHmiEnv_Consumer
      ADCC_ParkingHmiEnvConsumer_ICC_8155_QNX: type=ADCC_ParkingHmiEnv_Consumer
      ADCC_AomMMSt_Provider: type=ADCC_AomMMSt_Provider
      ADCC_AomMMStConsumer_ICC_8155_Android: type=ADCC_AomMMSt_Consumer
      ADCC_AomMMStConsumer_ICC_8155_QNX: type=ADCC_AomMMSt_Consumer
      ADCC_AomDB_Provider: type=ADCC_AomDB_Provider
      ADCC_AomDBConsumer_ICC_8155_Android: type=ADCC_AomDB_Consumer
      ADCC_AomDBConsumer_ICC_8155_QNX: type=ADCC_AomDB_Consumer
      ADCC_RtMM_Provider: type=ADCC_RtMM_Provider
      ADCC_RtMMConsumer_ICC_8155_Android: type=ADCC_RtMM_Consumer
      ADCC_RtMMConsumer_ICC_8155_QNX: type=ADCC_RtMM_Consumer
      FCM_DrivingHmiEnv_Provider: type=FCM_DrivingHmiEnv_Provider
      FCM_DrivingHmiEnvConsumer_ICC_8155_QNX: type=FCM_DrivingHmiEnv_Consumer
      FCM_DrivingHmiEnvConsumer_ICC_8155_Android: type=FCM_DrivingHmiEnv_Consumer
      FCM_ActiveSafetyInfo_Provider: type=FCM_ActiveSafetyInfo_Provider
      FCM_ActiveSafetyInfoConsumer_ICC_8155_Android: type=FCM_ActiveSafetyInfo_Consumer
      FCM_ActiveSafetyInfoConsumer_ICC_8155_QNX: type=FCM_ActiveSafetyInfo_Consumer
      FCM_DrivingFuncInfo_Provider: type=FCM_DrivingFuncInfo_Provider
      FCM_DrivingFuncInfoConsumer_ICC_8155_Android: type=FCM_DrivingFuncInfo_Consumer
      FCM_DrivingFuncInfoConsumer_ICC_8155_QNX: type=FCM_DrivingFuncInfo_Consumer
      FCM_DVRSts_Provider: type=FCM_DVRSts_Provider
      FCM_DVRStsConsumer_ICC_8155_Android: type=FCM_DVRSts_Consumer
      FCM_DVRStsConsumer_ICC_8155_QNX: type=FCM_DVRSts_Consumer
      FCM_UUID_Provider: type=FCM_UUID_Provider
      FCM_UUIDConsumer_TBOX: type=FCM_UUID_Consumer
      FCM_UUIDConsumer_ADCC: type=FCM_UUID_Consumer
      FCM_UUIDConsumer_LCM: type=FCM_UUID_Consumer
      FCM_UUIDConsumer_ICC_8155_Android: type=FCM_UUID_Consumer
      LCM_ICC_Data_Provider: type=LCM_ICC_Data_Provider
      LCM_ICC_DataConsumer_ICC_8155_QNX: type=LCM_ICC_Data_Consumer
      LCM_ADCC_RawData_Provider: type=LCM_ADCC_RawData_Provider
      LCM_ADCC_RawDataConsumer_ADCC: type=LCM_ADCC_RawData_Consumer
      ADCC_ActiveSafetyInfo_Provider: type=ADCC_ActiveSafetyInfo_Provider
      ADCC_ActiveSafetyInfoConsumer_ICC_8155_Android: type=ADCC_ActiveSafetyInfo_Consumer
      ADCC_ActiveSafetyInfoConsumer_ICC_8155_QNX: type=ADCC_ActiveSafetyInfo_Consumer
      ADCC_UUID_Provider: type=ADCC_UUID_Provider
      ADCC_UUIDConsumer_TBOX: type=ADCC_UUID_Consumer
      ADCC_UUIDConsumer_LCM: type=ADCC_UUID_Consumer
      ADCC_UUIDConsumer_ICC_8155_Android: type=ADCC_UUID_Consumer
      FCM_SensorInfo_Provider: type=FCM_SensorInfo_Provider
      FCM_SensorInfoConsumer_ICC_8155_Android: type=FCM_SensorInfo_Consumer
      FCM_SensorInfoConsumer_ICC_8155_QNX: type=FCM_SensorInfo_Consumer
      TBOX_SystemInfo_ICC_Provider: type=TBOX_SystemInfo_ICC_Provider
      TBOX_SystemInfo_ICCConsumer_ADCC: type=TBOX_SystemInfo_ICC_Consumer
      ADCC_DVRSts_Provider: type=ADCC_DVRSts_Provider
      ADCC_DVRStsConsumer_ICC_8155_Android: type=ADCC_DVRSts_Consumer
      ADCC_DVRStsConsumer_ICC_8155_QNX: type=ADCC_DVRSts_Consumer
      ADAS_DataInLoop_Provider: type=ADAS_DataInLoop_Provider
      ADAS_DataInLoopConsumer_ICC_8155_Android: type=ADAS_DataInLoop_Consumer
      IVI_UnixTimestamp_Provider: type=IVI_UnixTimestamp_Provider
      IVI_UnixTimestampConsumer_FCM: type=IVI_UnixTimestamp_Consumer
      ADAS_GNSSInfo_Provider: type=ADAS_GNSSInfo_Provider
      ADAS_GNSSInfoConsumer_ICC_8155_Android: type=ADAS_GNSSInfo_Consumer
      ADAS_GNSSInfoConsumer_ICC_8155_QNX: type=ADAS_GNSSInfo_Consumer
    connect TBOX_ResSwtSts_Provider.ServerPort_TBOX_ResSwtSts -> TBOX_ResSwtStsConsumer_ICC_8155_Android.ClientPort_TBOX_ResSwtSts
    connect TBOX_SystemInfo_Provider.ServerPort_TBOX_SystemInfo -> TBOX_SystemInfoConsumer_ADCC.ClientPort_TBOX_SystemInfo
    connect TBOX_SystemInfo_Provider.ServerPort_TBOX_SystemInfo -> TBOX_SystemInfoConsumer_LCM.ClientPort_TBOX_SystemInfo
    connect TBOX_SystemInfo_Provider.ServerPort_TBOX_SystemInfo -> TBOX_SystemInfoConsumer_ICC_8155_Android.ClientPort_TBOX_SystemInfo
    connect TBOX_BEICALL_Provider.ServerPort_TBOX_BEICALL -> TBOX_BEICALLConsumer_ICC_8155_Android.ClientPort_TBOX_BEICALL
    connect TBOX_USBUpdate_Provider.ServerPort_TBOX_USBUpdate -> TBOX_USBUpdateConsumer_ICC_8155_Android.ClientPort_TBOX_USBUpdate
    connect TBOX_USBTBOXlog_Provider.ServerPort_TBOX_USBTBOXlog -> TBOX_USBTBOXlogConsumer_ICC_8155_Android.ClientPort_TBOX_USBTBOXlog
    connect TBOX_GNSSInfo_Provider.ServerPort_TBOX_GNSSInfo -> TBOX_GNSSInfoConsumer_ICC_8155_Android.ClientPort_TBOX_GNSSInfo
    connect TBOX_GNSSInfo_Provider.ServerPort_TBOX_GNSSInfo -> TBOX_GNSSInfoConsumer_ADCC.ClientPort_TBOX_GNSSInfo
    connect ICC_Aom_Provider.ServerPort_ICC_Aom -> ICC_AomConsumer_ADCC.ClientPort_ICC_Aom
    connect ADCC_SensorInfo_Provider.ServerPort_ADCC_SensorInfo -> ADCC_SensorInfoConsumer_ICC_8155_Android.ClientPort_ADCC_SensorInfo
    connect ADCC_SensorInfo_Provider.ServerPort_ADCC_SensorInfo -> ADCC_SensorInfoConsumer_ICC_8155_QNX.ClientPort_ADCC_SensorInfo
    connect ADCC_AomDB_Provider.ServerPort_ADCC_AomDB -> ADCC_AomDBConsumer_ICC_8155_Android.ClientPort_ADCC_AomDB
    connect ADCC_AomDB_Provider.ServerPort_ADCC_AomDB -> ADCC_AomDBConsumer_ICC_8155_QNX.ClientPort_ADCC_AomDB
    connect FCM_DVRSts_Provider.ServerPort_FCM_DVRSts -> FCM_DVRStsConsumer_ICC_8155_Android.ClientPort_FCM_DVRSts
    connect FCM_DVRSts_Provider.ServerPort_FCM_DVRSts -> FCM_DVRStsConsumer_ICC_8155_QNX.ClientPort_FCM_DVRSts
    connect FCM_UUID_Provider.ServerPort_FCM_UUID -> FCM_UUIDConsumer_TBOX.ClientPort_FCM_UUID
    connect FCM_UUID_Provider.ServerPort_FCM_UUID -> FCM_UUIDConsumer_ADCC.ClientPort_FCM_UUID
    connect FCM_UUID_Provider.ServerPort_FCM_UUID -> FCM_UUIDConsumer_LCM.ClientPort_FCM_UUID
    connect FCM_UUID_Provider.ServerPort_FCM_UUID -> FCM_UUIDConsumer_ICC_8155_Android.ClientPort_FCM_UUID
    connect ADCC_UUID_Provider.ServerPort_ADCC_UUID -> ADCC_UUIDConsumer_TBOX.ClientPort_ADCC_UUID
    connect ADCC_UUID_Provider.ServerPort_ADCC_UUID -> ADCC_UUIDConsumer_LCM.ClientPort_ADCC_UUID
    connect ADCC_UUID_Provider.ServerPort_ADCC_UUID -> ADCC_UUIDConsumer_ICC_8155_Android.ClientPort_ADCC_UUID
    connect TBOX_SystemInfo_ICC_Provider.ServerPort_TBOX_SystemInfo_ICC -> TBOX_SystemInfo_ICCConsumer_ADCC.ClientPort_TBOX_SystemInfo_ICC
    connect ADCC_DVRSts_Provider.ServerPort_ADCC_DVRSts -> ADCC_DVRStsConsumer_ICC_8155_Android.ClientPort_ADCC_DVRSts
    connect ADCC_DVRSts_Provider.ServerPort_ADCC_DVRSts -> ADCC_DVRStsConsumer_ICC_8155_QNX.ClientPort_ADCC_DVRSts
    connect ADAS_GNSSInfo_Provider.ServerPort_ADAS_GNSSInfo -> ADAS_GNSSInfoConsumer_ICC_8155_Android.ClientPort_ADAS_GNSSInfo
    connect ADAS_GNSSInfo_Provider.ServerPort_ADAS_GNSSInfo -> ADAS_GNSSInfoConsumer_ICC_8155_QNX.ClientPort_ADAS_GNSSInfo
    connect eHMI_ParkingUI_Provider.eHMI_ParkingUI_NtfParkingFuncModReq_SndP -> eHMI_ParkingUIConsumer_ADCC.eHMI_ParkingUI_NtfParkingFuncModReq_RcvP
    connect eHMI_ParkingUI_Provider.eHMI_ParkingUI_NtfApaRpaFcnOperating_SndP -> eHMI_ParkingUIConsumer_ADCC.eHMI_ParkingUI_NtfApaRpaFcnOperating_RcvP
    connect eHMI_ParkingUI_Provider.eHMI_ParkingUI_NtfHpaFcnOperating_SndP -> eHMI_ParkingUIConsumer_ADCC.eHMI_ParkingUI_NtfHpaFcnOperating_RcvP
    connect eHMI_ParkingUI_Provider.eHMI_ParkingUI_NtfVpaFcnOperating_SndP -> eHMI_ParkingUIConsumer_ADCC.eHMI_ParkingUI_NtfVpaFcnOperating_RcvP
    connect eHMI_ParkingUI_Provider.eHMI_ParkingUI_NtfMraFcnOperating_SndP -> eHMI_ParkingUIConsumer_ADCC.eHMI_ParkingUI_NtfMraFcnOperating_RcvP
    connect eHMI_ParkingUI_Provider.eHMI_ParkingUI_NtfSVSStatus_SndP -> eHMI_ParkingUIConsumer_ADCC.eHMI_ParkingUI_NtfSVSStatus_RcvP
    connect eHMI_ParkingUI_Provider.eHMI_ParkingUI_NtfApaRpaFcnOperating_2_SndP -> eHMI_ParkingUIConsumer_ADCC.eHMI_ParkingUI_NtfApaRpaFcnOperating_2_RcvP
    connect eHMI_ParkingUI_Provider.eHMI_ParkingUI_NtfHpaFcnOperating_2_SndP -> eHMI_ParkingUIConsumer_ADCC.eHMI_ParkingUI_NtfHpaFcnOperating_2_RcvP
    connect eHMI_ADASSetting_Provider.eHMI_ADASSetting_NtfADASSettingInfo_SndP -> eHMI_ADASSettingConsumer_ADCC.eHMI_ADASSetting_NtfADASSettingInfo_RcvP
    connect eHMI_ADASSetting_Provider.eHMI_ADASSetting_NtfADASSettingInfo_2_SndP -> eHMI_ADASSettingConsumer_ADCC.eHMI_ADASSetting_NtfADASSettingInfo_2_RcvP
    connect eHMI_ADASSetting_Provider.eHMI_ADASSetting_NtfADASSettingInfo_3_SndP -> eHMI_ADASSettingConsumer_ADCC.eHMI_ADASSetting_NtfADASSettingInfo_3_RcvP
    connect eHMI_ADASSetting_Provider.eHMI_ADASSetting_NtfADASSettingInfo_SndP -> eHMI_ADASSettingConsumer_FCM.eHMI_ADASSetting_NtfADASSettingInfo_RcvP
    connect eHMI_ADASSetting_Provider.eHMI_ADASSetting_NtfADASSettingInfo_2_SndP -> eHMI_ADASSettingConsumer_FCM.eHMI_ADASSetting_NtfADASSettingInfo_2_RcvP
    connect eHMI_ADASSetting_Provider.eHMI_ADASSetting_NtfADASSettingInfo_3_SndP -> eHMI_ADASSettingConsumer_FCM.eHMI_ADASSetting_NtfADASSettingInfo_3_RcvP
    connect eHMI_DVRSet_Provider.eHMI_DVRSet_notifyDVRRequest_SndP -> eHMI_DVRSetConsumer_FCM.eHMI_DVRSet_notifyDVRRequest_RcvP
    connect TBOX_TimeManagement_Provider.TBOX_TimeManagement_notifyTimeManagement_SndP -> TBOX_TimeManagementConsumer_ICC_8155_Android.TBOX_TimeManagement_notifyTimeManagement_RcvP
    connect TBOX_ResSwtSts_Provider.TBOX_ResSwtSts_notify5GSwtSts_Fb_SndP -> TBOX_ResSwtStsConsumer_ICC_8155_Android.TBOX_ResSwtSts_notify5GSwtSts_Fb_RcvP
    connect TBOX_ResSwtSts_Provider.TBOX_ResSwtSts_notifyV2XSwtSts_Fb_SndP -> TBOX_ResSwtStsConsumer_ICC_8155_Android.TBOX_ResSwtSts_notifyV2XSwtSts_Fb_RcvP
    connect TBOX_ResSwtSts_Provider.TBOX_ResSwtSts_notifyDownLogSwtSts_Fb_SndP -> TBOX_ResSwtStsConsumer_ICC_8155_Android.TBOX_ResSwtSts_notifyDownLogSwtSts_Fb_RcvP
    connect TBOX_ResSwtSts_Provider.TBOX_ResSwtSts_notifyUSBUpdateSwtSts_Fb_SndP -> TBOX_ResSwtStsConsumer_ICC_8155_Android.TBOX_ResSwtSts_notifyUSBUpdateSwtSts_Fb_RcvP
    connect TBOX_ResSwtSts_Provider.TBOX_ResSwtSts_notifyResumeFactorySet_Fb_SndP -> TBOX_ResSwtStsConsumer_ICC_8155_Android.TBOX_ResSwtSts_notifyResumeFactorySet_Fb_RcvP
    connect TBOX_SystemInfo_Provider.TBOX_SystemInfo_Event_NetworkStatus_SndP -> TBOX_SystemInfoConsumer_ADCC.TBOX_SystemInfo_Event_NetworkStatus_RcvP
    connect TBOX_SystemInfo_Provider.TBOX_SystemInfo_Event_VehicleDiagStatus_SndP -> TBOX_SystemInfoConsumer_ADCC.TBOX_SystemInfo_Event_VehicleDiagStatus_RcvP
    connect TBOX_SystemInfo_Provider.TBOX_SystemInfo_Event_NetworkStatus_SndP -> TBOX_SystemInfoConsumer_LCM.TBOX_SystemInfo_Event_NetworkStatus_RcvP
    connect TBOX_SystemInfo_Provider.TBOX_SystemInfo_Event_VehicleDiagStatus_SndP -> TBOX_SystemInfoConsumer_LCM.TBOX_SystemInfo_Event_VehicleDiagStatus_RcvP
    connect TBOX_SystemInfo_Provider.TBOX_SystemInfo_Event_NetworkStatus_SndP -> TBOX_SystemInfoConsumer_ICC_8155_Android.TBOX_SystemInfo_Event_NetworkStatus_RcvP
    connect TBOX_SystemInfo_Provider.TBOX_SystemInfo_Event_VehicleDiagStatus_SndP -> TBOX_SystemInfoConsumer_ICC_8155_Android.TBOX_SystemInfo_Event_VehicleDiagStatus_RcvP
    connect TBOX_BEICALL_Provider.TBOX_BEICALL_Event_UploadBEICALLSts_SndP -> TBOX_BEICALLConsumer_ICC_8155_Android.TBOX_BEICALL_Event_UploadBEICALLSts_RcvP
    connect TBOX_BEICALL_Provider.TBOX_BEICALL_notifyEcallMdoe_SndP -> TBOX_BEICALLConsumer_ICC_8155_Android.TBOX_BEICALL_notifyEcallMdoe_RcvP
    connect TBOX_USBUpdate_Provider.TBOX_USBUpdate_Event_UsbUpdateSta_SndP -> TBOX_USBUpdateConsumer_ICC_8155_Android.TBOX_USBUpdate_Event_UsbUpdateSta_RcvP
    connect TBOX_USBUpdateConsumer_ICC_8155_Android.TBOX_USBUpdate_FF_UpdateCompleted_SndP -> TBOX_USBUpdate_Provider.TBOX_USBUpdate_FF_UpdateCompleted_RcvP
    connect TBOX_GNSSInfo_Provider.TBOX_GNSSInfo_Event_GNSSInfo1_SndP -> TBOX_GNSSInfoConsumer_ICC_8155_Android.TBOX_GNSSInfo_Event_GNSSInfo1_RcvP
    connect TBOX_GNSSInfo_Provider.TBOX_GNSSInfo_Event_GNSSInfo1_SndP -> TBOX_GNSSInfoConsumer_ADCC.TBOX_GNSSInfo_Event_GNSSInfo1_RcvP
    connect ICC_Android_OutService_Provider.ICC_Android_OutService_notifyEcallMdoeFed_SndP -> ICC_Android_OutServiceConsumer_TBOX.ICC_Android_OutService_notifyEcallMdoeFed_RcvP
    connect ICC_Aom_Provider.ICC_Aom_notifyADCC_Command_SndP -> ICC_AomConsumer_ADCC.ICC_Aom_notifyADCC_Command_RcvP
    connect ICC_SDmapInfo_Provider.ICC_SDmapInfo_NtfSDmapInfo_SndP -> ICC_SDmapInfoConsumer_ADCC.ICC_SDmapInfo_NtfSDmapInfo_RcvP
    connect ICC_SDmapInfo_Provider.ICC_SDmapInfo_notifyNOA_SDMapPosInfo_SndP -> ICC_SDmapInfoConsumer_ADCC.ICC_SDmapInfo_notifyNOA_SDMapPosInfo_RcvP
    connect ICC_SDmapInfo_Provider.ICC_SDmapInfo_notifyNOA_SDMapStubInfo_SndP -> ICC_SDmapInfoConsumer_ADCC.ICC_SDmapInfo_notifyNOA_SDMapStubInfo_RcvP
    connect ICC_SDmapInfo_Provider.ICC_SDmapInfo_notifyNOA_SDMapSegmentInfo_SndP -> ICC_SDmapInfoConsumer_ADCC.ICC_SDmapInfo_notifyNOA_SDMapSegmentInfo_RcvP
    connect ICC_SDmapInfo_Provider.ICC_SDmapInfo_notifyNOA_SDMapShortInfo_SndP -> ICC_SDmapInfoConsumer_ADCC.ICC_SDmapInfo_notifyNOA_SDMapShortInfo_RcvP
    connect ICC_SDmapInfo_Provider.ICC_SDmapInfo_notifyNOA_SDMapLongInfo_SndP -> ICC_SDmapInfoConsumer_ADCC.ICC_SDmapInfo_notifyNOA_SDMapLongInfo_RcvP
    connect ICC_SDmapInfo_Provider.ICC_SDmapInfo_notifyNOA_SDMapMetaInfo_SndP -> ICC_SDmapInfoConsumer_ADCC.ICC_SDmapInfo_notifyNOA_SDMapMetaInfo_RcvP
    connect ICC_SDmapInfo_Provider.ICC_SDmapInfo_NtfSDmapInfo_international_SndP -> ICC_SDmapInfoConsumer_ADCC.ICC_SDmapInfo_NtfSDmapInfo_international_RcvP
    connect ICC_SDmapInfo_Provider.ICC_SDmapInfo_NtfSDmapLaneInfo_SndP -> ICC_SDmapInfoConsumer_ADCC.ICC_SDmapInfo_NtfSDmapLaneInfo_RcvP
    connect ICC_SDmapInfo_Provider.ICC_SDmapInfo_NtfSDmapInfo_SndP -> ICC_SDmapInfoConsumer_FCM.ICC_SDmapInfo_NtfSDmapInfo_RcvP
    connect ICC_SDmapInfo_Provider.ICC_SDmapInfo_notifyNOA_SDMapPosInfo_SndP -> ICC_SDmapInfoConsumer_FCM.ICC_SDmapInfo_notifyNOA_SDMapPosInfo_RcvP
    connect ICC_SDmapInfo_Provider.ICC_SDmapInfo_notifyNOA_SDMapStubInfo_SndP -> ICC_SDmapInfoConsumer_FCM.ICC_SDmapInfo_notifyNOA_SDMapStubInfo_RcvP
    connect ICC_SDmapInfo_Provider.ICC_SDmapInfo_notifyNOA_SDMapSegmentInfo_SndP -> ICC_SDmapInfoConsumer_FCM.ICC_SDmapInfo_notifyNOA_SDMapSegmentInfo_RcvP
    connect ICC_SDmapInfo_Provider.ICC_SDmapInfo_notifyNOA_SDMapShortInfo_SndP -> ICC_SDmapInfoConsumer_FCM.ICC_SDmapInfo_notifyNOA_SDMapShortInfo_RcvP
    connect ICC_SDmapInfo_Provider.ICC_SDmapInfo_notifyNOA_SDMapLongInfo_SndP -> ICC_SDmapInfoConsumer_FCM.ICC_SDmapInfo_notifyNOA_SDMapLongInfo_RcvP
    connect ICC_SDmapInfo_Provider.ICC_SDmapInfo_notifyNOA_SDMapMetaInfo_SndP -> ICC_SDmapInfoConsumer_FCM.ICC_SDmapInfo_notifyNOA_SDMapMetaInfo_RcvP
    connect ICC_SDmapInfo_Provider.ICC_SDmapInfo_NtfSDmapInfo_international_SndP -> ICC_SDmapInfoConsumer_FCM.ICC_SDmapInfo_NtfSDmapInfo_international_RcvP
    connect ICC_SDmapInfo_Provider.ICC_SDmapInfo_NtfSDmapLaneInfo_SndP -> ICC_SDmapInfoConsumer_FCM.ICC_SDmapInfo_NtfSDmapLaneInfo_RcvP
    connect ICC_SDmapInfo_2_Provider.ICC_SDmapInfo_2_NtfSDmapRouteInfo_SndP -> ICC_SDmapInfo_2Consumer_ADCC.ICC_SDmapInfo_2_NtfSDmapRouteInfo_RcvP
    connect ICC_SDmapInfo_2_Provider.ICC_SDmapInfo_2_NtfSDmapTBTNaviInfo_SndP -> ICC_SDmapInfo_2Consumer_ADCC.ICC_SDmapInfo_2_NtfSDmapTBTNaviInfo_RcvP
    connect ICC_SDmapInfo_2_Provider.ICC_SDmapInfo_2_NtfSDmapNaviCameraInfo_SndP -> ICC_SDmapInfo_2Consumer_ADCC.ICC_SDmapInfo_2_NtfSDmapNaviCameraInfo_RcvP
    connect ICC_SDmapInfo_2_Provider.ICC_SDmapInfo_2_NtfSDmapCruiseFacilityInfo_SndP -> ICC_SDmapInfo_2Consumer_ADCC.ICC_SDmapInfo_2_NtfSDmapCruiseFacilityInfo_RcvP
    connect ICC_SDmapInfo_2_Provider.ICC_SDmapInfo_2_NtfSDmapTrafficLightCDInfo_SndP -> ICC_SDmapInfo_2Consumer_ADCC.ICC_SDmapInfo_2_NtfSDmapTrafficLightCDInfo_RcvP
    connect ICC_SDmapInfo_2_Provider.ICC_SDmapInfo_2_NtfSDmapNaviIntCamDynInfo_SndP -> ICC_SDmapInfo_2Consumer_ADCC.ICC_SDmapInfo_2_NtfSDmapNaviIntCamDynInfo_RcvP
    connect ICC_SDmapInfo_2_Provider.ICC_SDmapInfo_2_NtfSDmapNaviWeatherInfo_SndP -> ICC_SDmapInfo_2Consumer_ADCC.ICC_SDmapInfo_2_NtfSDmapNaviWeatherInfo_RcvP
    connect ICC_SDmapInfo_2_Provider.ICC_SDmapInfo_2_NtfSDmapNaviCongestionInfo_SndP -> ICC_SDmapInfo_2Consumer_ADCC.ICC_SDmapInfo_2_NtfSDmapNaviCongestionInfo_RcvP
    connect ICC_SDmapInfo_2_Provider.ICC_SDmapInfo_2_NtfSDmapNaviGreenWaveCarSpd_SndP -> ICC_SDmapInfo_2Consumer_ADCC.ICC_SDmapInfo_2_NtfSDmapNaviGreenWaveCarSpd_RcvP
    connect ICC_SDmapInfo_2_Provider.ICC_SDmapInfo_2_notifySDmapLaneInfo_SndP -> ICC_SDmapInfo_2Consumer_ADCC.ICC_SDmapInfo_2_notifySDmapLaneInfo_RcvP
    connect ICC_SDmapInfo_2_Provider.ICC_SDmapInfo_2_NtfSDmapMixForkInfo_SndP -> ICC_SDmapInfo_2Consumer_ADCC.ICC_SDmapInfo_2_NtfSDmapMixForkInfo_RcvP
    connect ICC_SDmapInfo_2_Provider.ICC_SDmapInfo_2_NtfSDmapMyLocationInfo_SndP -> ICC_SDmapInfo_2Consumer_ADCC.ICC_SDmapInfo_2_NtfSDmapMyLocationInfo_RcvP
    connect ICC_SDmapInfo_2_Provider.ICC_SDmapInfo_2_NtfSDmapNaviStatusInfo_SndP -> ICC_SDmapInfo_2Consumer_ADCC.ICC_SDmapInfo_2_NtfSDmapNaviStatusInfo_RcvP
    connect ICC_SDmapInfo_2_Provider.ICC_SDmapInfo_2_NtfSDmapSoundInfo_SndP -> ICC_SDmapInfo_2Consumer_ADCC.ICC_SDmapInfo_2_NtfSDmapSoundInfo_RcvP
    connect ICC_SDmapInfo_2_Provider.ICC_SDmapInfo_2_NtfSDmapRouteOption_SndP -> ICC_SDmapInfo_2Consumer_ADCC.ICC_SDmapInfo_2_NtfSDmapRouteOption_RcvP
    connect ICC_SDmapInfo_2_Provider.ICC_SDmapInfo_2_NtfSDmapCruiseInfo_SndP -> ICC_SDmapInfo_2Consumer_ADCC.ICC_SDmapInfo_2_NtfSDmapCruiseInfo_RcvP
    connect ICC_SDmapInfo_2_Provider.ICC_SDmapInfo_2_NtfSDmapNaviRoadInfo_SndP -> ICC_SDmapInfo_2Consumer_ADCC.ICC_SDmapInfo_2_NtfSDmapNaviRoadInfo_RcvP
    connect ICC_SDmapInfo_2_Provider.ICC_SDmapInfo_2_NtfSDmapAheadLaneInfo_SndP -> ICC_SDmapInfo_2Consumer_ADCC.ICC_SDmapInfo_2_NtfSDmapAheadLaneInfo_RcvP
    connect ICC_SDmapInfo_2_Provider.ICC_SDmapInfo_2_NtfSDmapTollGateInfo_SndP -> ICC_SDmapInfo_2Consumer_ADCC.ICC_SDmapInfo_2_NtfSDmapTollGateInfo_RcvP
    connect ICC_SDmapInfo_2_Provider.ICC_SDmapInfo_2_NtfSDmapServiceAreaInfo_SndP -> ICC_SDmapInfo_2Consumer_ADCC.ICC_SDmapInfo_2_NtfSDmapServiceAreaInfo_RcvP
    connect ICC_SDmapInfo_2_Provider.ICC_SDmapInfo_2_NtfSDmapTunnelInfo_SndP -> ICC_SDmapInfo_2Consumer_ADCC.ICC_SDmapInfo_2_NtfSDmapTunnelInfo_RcvP
    connect ICC_SDmapInfo_2_Provider.ICC_SDmapInfo_2_NtfSDmapRampInfo_SndP -> ICC_SDmapInfo_2Consumer_ADCC.ICC_SDmapInfo_2_NtfSDmapRampInfo_RcvP
    connect ICC_SDmapInfo_2_Provider.ICC_SDmapInfo_2_NtfSDmapFacilityInfo_SndP -> ICC_SDmapInfo_2Consumer_ADCC.ICC_SDmapInfo_2_NtfSDmapFacilityInfo_RcvP
    connect ICC_SDmapInfo_2_Provider.ICC_SDmapInfo_2_NtfSDmapLocMatchInfo_SndP -> ICC_SDmapInfo_2Consumer_ADCC.ICC_SDmapInfo_2_NtfSDmapLocMatchInfo_RcvP
    connect ICC_SDmapInfo_2_Provider.ICC_SDmapInfo_2_notifySDmapTollGateLaneInfo_SndP -> ICC_SDmapInfo_2Consumer_ADCC.ICC_SDmapInfo_2_notifySDmapTollGateLaneInfo_RcvP
    connect ICC_SDmapInfo_2_Provider.ICC_SDmapInfo_2_notifySDmapNavArriveAim_SndP -> ICC_SDmapInfo_2Consumer_ADCC.ICC_SDmapInfo_2_notifySDmapNavArriveAim_RcvP
    connect ICC_SDmapInfo_2_Provider.ICC_SDmapInfo_2_NtfSDmapRouteInfo_SndP -> ICC_SDmapInfo_2Consumer_FCM.ICC_SDmapInfo_2_NtfSDmapRouteInfo_RcvP
    connect ICC_SDmapInfo_2_Provider.ICC_SDmapInfo_2_NtfSDmapTBTNaviInfo_SndP -> ICC_SDmapInfo_2Consumer_FCM.ICC_SDmapInfo_2_NtfSDmapTBTNaviInfo_RcvP
    connect ICC_SDmapInfo_2_Provider.ICC_SDmapInfo_2_NtfSDmapNaviCameraInfo_SndP -> ICC_SDmapInfo_2Consumer_FCM.ICC_SDmapInfo_2_NtfSDmapNaviCameraInfo_RcvP
    connect ICC_SDmapInfo_2_Provider.ICC_SDmapInfo_2_NtfSDmapCruiseFacilityInfo_SndP -> ICC_SDmapInfo_2Consumer_FCM.ICC_SDmapInfo_2_NtfSDmapCruiseFacilityInfo_RcvP
    connect ICC_SDmapInfo_2_Provider.ICC_SDmapInfo_2_NtfSDmapTrafficLightCDInfo_SndP -> ICC_SDmapInfo_2Consumer_FCM.ICC_SDmapInfo_2_NtfSDmapTrafficLightCDInfo_RcvP
    connect ICC_SDmapInfo_2_Provider.ICC_SDmapInfo_2_NtfSDmapNaviIntCamDynInfo_SndP -> ICC_SDmapInfo_2Consumer_FCM.ICC_SDmapInfo_2_NtfSDmapNaviIntCamDynInfo_RcvP
    connect ICC_SDmapInfo_2_Provider.ICC_SDmapInfo_2_NtfSDmapNaviWeatherInfo_SndP -> ICC_SDmapInfo_2Consumer_FCM.ICC_SDmapInfo_2_NtfSDmapNaviWeatherInfo_RcvP
    connect ICC_SDmapInfo_2_Provider.ICC_SDmapInfo_2_NtfSDmapNaviCongestionInfo_SndP -> ICC_SDmapInfo_2Consumer_FCM.ICC_SDmapInfo_2_NtfSDmapNaviCongestionInfo_RcvP
    connect ICC_SDmapInfo_2_Provider.ICC_SDmapInfo_2_NtfSDmapNaviGreenWaveCarSpd_SndP -> ICC_SDmapInfo_2Consumer_FCM.ICC_SDmapInfo_2_NtfSDmapNaviGreenWaveCarSpd_RcvP
    connect ICC_SDmapInfo_2_Provider.ICC_SDmapInfo_2_notifySDmapLaneInfo_SndP -> ICC_SDmapInfo_2Consumer_FCM.ICC_SDmapInfo_2_notifySDmapLaneInfo_RcvP
    connect ICC_SDmapInfo_2_Provider.ICC_SDmapInfo_2_NtfSDmapMixForkInfo_SndP -> ICC_SDmapInfo_2Consumer_FCM.ICC_SDmapInfo_2_NtfSDmapMixForkInfo_RcvP
    connect ICC_SDmapInfo_2_Provider.ICC_SDmapInfo_2_NtfSDmapMyLocationInfo_SndP -> ICC_SDmapInfo_2Consumer_FCM.ICC_SDmapInfo_2_NtfSDmapMyLocationInfo_RcvP
    connect ICC_SDmapInfo_2_Provider.ICC_SDmapInfo_2_NtfSDmapNaviStatusInfo_SndP -> ICC_SDmapInfo_2Consumer_FCM.ICC_SDmapInfo_2_NtfSDmapNaviStatusInfo_RcvP
    connect ICC_SDmapInfo_2_Provider.ICC_SDmapInfo_2_NtfSDmapSoundInfo_SndP -> ICC_SDmapInfo_2Consumer_FCM.ICC_SDmapInfo_2_NtfSDmapSoundInfo_RcvP
    connect ICC_SDmapInfo_2_Provider.ICC_SDmapInfo_2_NtfSDmapRouteOption_SndP -> ICC_SDmapInfo_2Consumer_FCM.ICC_SDmapInfo_2_NtfSDmapRouteOption_RcvP
    connect ICC_SDmapInfo_2_Provider.ICC_SDmapInfo_2_NtfSDmapCruiseInfo_SndP -> ICC_SDmapInfo_2Consumer_FCM.ICC_SDmapInfo_2_NtfSDmapCruiseInfo_RcvP
    connect ICC_SDmapInfo_2_Provider.ICC_SDmapInfo_2_NtfSDmapNaviRoadInfo_SndP -> ICC_SDmapInfo_2Consumer_FCM.ICC_SDmapInfo_2_NtfSDmapNaviRoadInfo_RcvP
    connect ICC_SDmapInfo_2_Provider.ICC_SDmapInfo_2_NtfSDmapAheadLaneInfo_SndP -> ICC_SDmapInfo_2Consumer_FCM.ICC_SDmapInfo_2_NtfSDmapAheadLaneInfo_RcvP
    connect ICC_SDmapInfo_2_Provider.ICC_SDmapInfo_2_NtfSDmapTollGateInfo_SndP -> ICC_SDmapInfo_2Consumer_FCM.ICC_SDmapInfo_2_NtfSDmapTollGateInfo_RcvP
    connect ICC_SDmapInfo_2_Provider.ICC_SDmapInfo_2_NtfSDmapServiceAreaInfo_SndP -> ICC_SDmapInfo_2Consumer_FCM.ICC_SDmapInfo_2_NtfSDmapServiceAreaInfo_RcvP
    connect ICC_SDmapInfo_2_Provider.ICC_SDmapInfo_2_NtfSDmapTunnelInfo_SndP -> ICC_SDmapInfo_2Consumer_FCM.ICC_SDmapInfo_2_NtfSDmapTunnelInfo_RcvP
    connect ICC_SDmapInfo_2_Provider.ICC_SDmapInfo_2_NtfSDmapRampInfo_SndP -> ICC_SDmapInfo_2Consumer_FCM.ICC_SDmapInfo_2_NtfSDmapRampInfo_RcvP
    connect ICC_SDmapInfo_2_Provider.ICC_SDmapInfo_2_NtfSDmapFacilityInfo_SndP -> ICC_SDmapInfo_2Consumer_FCM.ICC_SDmapInfo_2_NtfSDmapFacilityInfo_RcvP
    connect ICC_SDmapInfo_2_Provider.ICC_SDmapInfo_2_NtfSDmapLocMatchInfo_SndP -> ICC_SDmapInfo_2Consumer_FCM.ICC_SDmapInfo_2_NtfSDmapLocMatchInfo_RcvP
    connect ICC_SDmapInfo_2_Provider.ICC_SDmapInfo_2_notifySDmapTollGateLaneInfo_SndP -> ICC_SDmapInfo_2Consumer_FCM.ICC_SDmapInfo_2_notifySDmapTollGateLaneInfo_RcvP
    connect ICC_SDmapInfo_2_Provider.ICC_SDmapInfo_2_notifySDmapNavArriveAim_SndP -> ICC_SDmapInfo_2Consumer_FCM.ICC_SDmapInfo_2_notifySDmapNavArriveAim_RcvP
    connect ADCC_DrivingHmiEnv_Provider.ADCC_DrivingHmiEnv_NtfDynamicObjectList_Drvg_SndP -> ADCC_DrivingHmiEnvConsumer_ICC_8155_Android.ADCC_DrivingHmiEnv_NtfDynamicObjectList_Drvg_RcvP
    connect ADCC_DrivingHmiEnv_Provider.ADCC_DrivingHmiEnv_NtfStaticObjectList_Drvg_SndP -> ADCC_DrivingHmiEnvConsumer_ICC_8155_Android.ADCC_DrivingHmiEnv_NtfStaticObjectList_Drvg_RcvP
    connect ADCC_DrivingHmiEnv_Provider.ADCC_DrivingHmiEnv_NtfLaneLineListt_Drvg_SndP -> ADCC_DrivingHmiEnvConsumer_ICC_8155_Android.ADCC_DrivingHmiEnv_NtfLaneLineListt_Drvg_RcvP
    connect ADCC_DrivingHmiEnv_Provider.ADCC_DrivingHmiEnv_NtfEgoFusionPose_Drvg_SndP -> ADCC_DrivingHmiEnvConsumer_ICC_8155_Android.ADCC_DrivingHmiEnv_NtfEgoFusionPose_Drvg_RcvP
    connect ADCC_DrivingHmiEnv_Provider.ADCC_DrivingHmiEnv_NtfRoadMarkerList_SndP -> ADCC_DrivingHmiEnvConsumer_ICC_8155_Android.ADCC_DrivingHmiEnv_NtfRoadMarkerList_RcvP
    connect ADCC_DrivingHmiEnv_Provider.ADCC_DrivingHmiEnv_NtfLaneLineListt_Drvg_2_SndP -> ADCC_DrivingHmiEnvConsumer_ICC_8155_Android.ADCC_DrivingHmiEnv_NtfLaneLineListt_Drvg_2_RcvP
    connect ADCC_DrivingHmiEnv_Provider.ADCC_DrivingHmiEnv_NtfEgoPose_SndP -> ADCC_DrivingHmiEnvConsumer_ICC_8155_Android.ADCC_DrivingHmiEnv_NtfEgoPose_RcvP
    connect ADCC_DrivingHmiEnv_Provider.ADCC_DrivingHmiEnv_NtfFusionMapData_SndP -> ADCC_DrivingHmiEnvConsumer_ICC_8155_Android.ADCC_DrivingHmiEnv_NtfFusionMapData_RcvP
    connect ADCC_DrivingHmiEnv_Provider.ADCC_DrivingHmiEnv_NtfRoadMarkerListSupplement_SndP -> ADCC_DrivingHmiEnvConsumer_ICC_8155_Android.ADCC_DrivingHmiEnv_NtfRoadMarkerListSupplement_RcvP
    connect ADCC_DrivingHmiEnv_Provider.ADCC_DrivingHmiEnv_NtfTrafficLightList_Drvg_SndP -> ADCC_DrivingHmiEnvConsumer_ICC_8155_Android.ADCC_DrivingHmiEnv_NtfTrafficLightList_Drvg_RcvP
    connect ADCC_DrivingHmiEnv_Provider.ADCC_DrivingHmiEnv_NtfFreeSpaceList_Drvg_SndP -> ADCC_DrivingHmiEnvConsumer_ICC_8155_Android.ADCC_DrivingHmiEnv_NtfFreeSpaceList_Drvg_RcvP
    connect ADCC_DrivingHmiEnv_Provider.ADCC_DrivingHmiEnv_Ntf3DTrafficSignList_Drvg_SndP -> ADCC_DrivingHmiEnvConsumer_ICC_8155_Android.ADCC_DrivingHmiEnv_Ntf3DTrafficSignList_Drvg_RcvP
    connect ADCC_DrivingHmiEnv_Provider.ADCC_DrivingHmiEnv_NtfDynamicObjectList_Drvg_2_SndP -> ADCC_DrivingHmiEnvConsumer_ICC_8155_Android.ADCC_DrivingHmiEnv_NtfDynamicObjectList_Drvg_2_RcvP
    connect ADCC_DrivingHmiEnv_Provider.ADCC_DrivingHmiEnv_NtfStaticObjectList_Drvg_2_SndP -> ADCC_DrivingHmiEnvConsumer_ICC_8155_Android.ADCC_DrivingHmiEnv_NtfStaticObjectList_Drvg_2_RcvP
    connect ADCC_DrivingHmiEnv_Provider.ADCC_DrivingHmiEnv_NtfRoadMarkerList_2_SndP -> ADCC_DrivingHmiEnvConsumer_ICC_8155_Android.ADCC_DrivingHmiEnv_NtfRoadMarkerList_2_RcvP
    connect ADCC_DrivingHmiEnv_Provider.ADCC_DrivingHmiEnv_NtfRoadSurfaceMes_SndP -> ADCC_DrivingHmiEnvConsumer_ICC_8155_Android.ADCC_DrivingHmiEnv_NtfRoadSurfaceMes_RcvP
    connect ADCC_DrivingHmiEnv_Provider.ADCC_DrivingHmiEnv_NtfDynamicObjectList_Drvg_SndP -> ADCC_DrivingHmiEnvConsumer_ICC_8155_QNX.ADCC_DrivingHmiEnv_NtfDynamicObjectList_Drvg_RcvP
    connect ADCC_DrivingHmiEnv_Provider.ADCC_DrivingHmiEnv_NtfStaticObjectList_Drvg_SndP -> ADCC_DrivingHmiEnvConsumer_ICC_8155_QNX.ADCC_DrivingHmiEnv_NtfStaticObjectList_Drvg_RcvP
    connect ADCC_DrivingHmiEnv_Provider.ADCC_DrivingHmiEnv_NtfLaneLineListt_Drvg_SndP -> ADCC_DrivingHmiEnvConsumer_ICC_8155_QNX.ADCC_DrivingHmiEnv_NtfLaneLineListt_Drvg_RcvP
    connect ADCC_DrivingHmiEnv_Provider.ADCC_DrivingHmiEnv_NtfEgoFusionPose_Drvg_SndP -> ADCC_DrivingHmiEnvConsumer_ICC_8155_QNX.ADCC_DrivingHmiEnv_NtfEgoFusionPose_Drvg_RcvP
    connect ADCC_DrivingHmiEnv_Provider.ADCC_DrivingHmiEnv_NtfRoadMarkerList_SndP -> ADCC_DrivingHmiEnvConsumer_ICC_8155_QNX.ADCC_DrivingHmiEnv_NtfRoadMarkerList_RcvP
    connect ADCC_DrivingHmiEnv_Provider.ADCC_DrivingHmiEnv_NtfLaneLineListt_Drvg_2_SndP -> ADCC_DrivingHmiEnvConsumer_ICC_8155_QNX.ADCC_DrivingHmiEnv_NtfLaneLineListt_Drvg_2_RcvP
    connect ADCC_DrivingHmiEnv_Provider.ADCC_DrivingHmiEnv_NtfEgoPose_SndP -> ADCC_DrivingHmiEnvConsumer_ICC_8155_QNX.ADCC_DrivingHmiEnv_NtfEgoPose_RcvP
    connect ADCC_DrivingHmiEnv_Provider.ADCC_DrivingHmiEnv_NtfFusionMapData_SndP -> ADCC_DrivingHmiEnvConsumer_ICC_8155_QNX.ADCC_DrivingHmiEnv_NtfFusionMapData_RcvP
    connect ADCC_DrivingHmiEnv_Provider.ADCC_DrivingHmiEnv_NtfRoadMarkerListSupplement_SndP -> ADCC_DrivingHmiEnvConsumer_ICC_8155_QNX.ADCC_DrivingHmiEnv_NtfRoadMarkerListSupplement_RcvP
    connect ADCC_DrivingHmiEnv_Provider.ADCC_DrivingHmiEnv_NtfTrafficLightList_Drvg_SndP -> ADCC_DrivingHmiEnvConsumer_ICC_8155_QNX.ADCC_DrivingHmiEnv_NtfTrafficLightList_Drvg_RcvP
    connect ADCC_DrivingHmiEnv_Provider.ADCC_DrivingHmiEnv_NtfFreeSpaceList_Drvg_SndP -> ADCC_DrivingHmiEnvConsumer_ICC_8155_QNX.ADCC_DrivingHmiEnv_NtfFreeSpaceList_Drvg_RcvP
    connect ADCC_DrivingHmiEnv_Provider.ADCC_DrivingHmiEnv_Ntf3DTrafficSignList_Drvg_SndP -> ADCC_DrivingHmiEnvConsumer_ICC_8155_QNX.ADCC_DrivingHmiEnv_Ntf3DTrafficSignList_Drvg_RcvP
    connect ADCC_DrivingHmiEnv_Provider.ADCC_DrivingHmiEnv_NtfDynamicObjectList_Drvg_2_SndP -> ADCC_DrivingHmiEnvConsumer_ICC_8155_QNX.ADCC_DrivingHmiEnv_NtfDynamicObjectList_Drvg_2_RcvP
    connect ADCC_DrivingHmiEnv_Provider.ADCC_DrivingHmiEnv_NtfStaticObjectList_Drvg_2_SndP -> ADCC_DrivingHmiEnvConsumer_ICC_8155_QNX.ADCC_DrivingHmiEnv_NtfStaticObjectList_Drvg_2_RcvP
    connect ADCC_DrivingHmiEnv_Provider.ADCC_DrivingHmiEnv_NtfRoadMarkerList_2_SndP -> ADCC_DrivingHmiEnvConsumer_ICC_8155_QNX.ADCC_DrivingHmiEnv_NtfRoadMarkerList_2_RcvP
    connect ADCC_DrivingHmiEnv_Provider.ADCC_DrivingHmiEnv_NtfRoadSurfaceMes_SndP -> ADCC_DrivingHmiEnvConsumer_ICC_8155_QNX.ADCC_DrivingHmiEnv_NtfRoadSurfaceMes_RcvP
    connect ADCC_SensorInfo_Provider.ADCC_SensorInfo_NtfSensorSt_SndP -> ADCC_SensorInfoConsumer_ICC_8155_Android.ADCC_SensorInfo_NtfSensorSt_RcvP
    connect ADCC_SensorInfo_Provider.ADCC_SensorInfo_CamStreamStResp_SndP -> ADCC_SensorInfoConsumer_ICC_8155_Android.ADCC_SensorInfo_CamStreamStResp_RcvP
    connect ADCC_SensorInfoConsumer_ICC_8155_Android.ADCC_SensorInfo_CamStreamSwtReq_SndP -> ADCC_SensorInfo_Provider.ADCC_SensorInfo_CamStreamSwtReq_RcvP
    connect ADCC_SensorInfo_Provider.ADCC_SensorInfo_NtfSensorSt_SndP -> ADCC_SensorInfoConsumer_ICC_8155_QNX.ADCC_SensorInfo_NtfSensorSt_RcvP
    connect ADCC_SensorInfo_Provider.ADCC_SensorInfo_CamStreamStResp_SndP -> ADCC_SensorInfoConsumer_ICC_8155_QNX.ADCC_SensorInfo_CamStreamStResp_RcvP
    connect ADCC_SensorInfoConsumer_ICC_8155_QNX.ADCC_SensorInfo_CamStreamSwtReq_SndP -> ADCC_SensorInfo_Provider.ADCC_SensorInfo_CamStreamSwtReq_RcvP
    connect ADCC_DrivingFuncInfo_Provider.ADCC_DrivingFuncInfo_NtfTrafficSign_Drvg_SndP -> ADCC_DrivingFuncInfoConsumer_ICC_8155_Android.ADCC_DrivingFuncInfo_NtfTrafficSign_Drvg_RcvP
    connect ADCC_DrivingFuncInfo_Provider.ADCC_DrivingFuncInfo_NtfISLIInfo_Drvg_SndP -> ADCC_DrivingFuncInfoConsumer_ICC_8155_Android.ADCC_DrivingFuncInfo_NtfISLIInfo_Drvg_RcvP
    connect ADCC_DrivingFuncInfo_Provider.ADCC_DrivingFuncInfo_NtfACCInfo_Drvg_SndP -> ADCC_DrivingFuncInfoConsumer_ICC_8155_Android.ADCC_DrivingFuncInfo_NtfACCInfo_Drvg_RcvP
    connect ADCC_DrivingFuncInfo_Provider.ADCC_DrivingFuncInfo_NtfALCInfo_Drvg_SndP -> ADCC_DrivingFuncInfoConsumer_ICC_8155_Android.ADCC_DrivingFuncInfo_NtfALCInfo_Drvg_RcvP
    connect ADCC_DrivingFuncInfo_Provider.ADCC_DrivingFuncInfo_NtfICAInfo_Drvg_SndP -> ADCC_DrivingFuncInfoConsumer_ICC_8155_Android.ADCC_DrivingFuncInfo_NtfICAInfo_Drvg_RcvP
    connect ADCC_DrivingFuncInfo_Provider.ADCC_DrivingFuncInfo_NtfIntelligentEvasionInfo_Drvg_SndP -> ADCC_DrivingFuncInfoConsumer_ICC_8155_Android.ADCC_DrivingFuncInfo_NtfIntelligentEvasionInfo_Drvg_RcvP
    connect ADCC_DrivingFuncInfo_Provider.ADCC_DrivingFuncInfo_NtfHNOPfunctionInfo_Drvg_SndP -> ADCC_DrivingFuncInfoConsumer_ICC_8155_Android.ADCC_DrivingFuncInfo_NtfHNOPfunctionInfo_Drvg_RcvP
    connect ADCC_DrivingFuncInfo_Provider.ADCC_DrivingFuncInfo_NtfUNOPfunctionInfo_Drvg_SndP -> ADCC_DrivingFuncInfoConsumer_ICC_8155_Android.ADCC_DrivingFuncInfo_NtfUNOPfunctionInfo_Drvg_RcvP
    connect ADCC_DrivingFuncInfo_Provider.ADCC_DrivingFuncInfo_NtfHodDmsInfo_Drvg_SndP -> ADCC_DrivingFuncInfoConsumer_ICC_8155_Android.ADCC_DrivingFuncInfo_NtfHodDmsInfo_Drvg_RcvP
    connect ADCC_DrivingFuncInfo_Provider.ADCC_DrivingFuncInfo_NtfLSSInfo_Drvg_SndP -> ADCC_DrivingFuncInfoConsumer_ICC_8155_Android.ADCC_DrivingFuncInfo_NtfLSSInfo_Drvg_RcvP
    connect ADCC_DrivingFuncInfo_Provider.ADCC_DrivingFuncInfo_NtfESSInfo_Drvg_SndP -> ADCC_DrivingFuncInfoConsumer_ICC_8155_Android.ADCC_DrivingFuncInfo_NtfESSInfo_Drvg_RcvP
    connect ADCC_DrivingFuncInfo_Provider.ADCC_DrivingFuncInfo_NtfDAIInfo_Drvg_SndP -> ADCC_DrivingFuncInfoConsumer_ICC_8155_Android.ADCC_DrivingFuncInfo_NtfDAIInfo_Drvg_RcvP
    connect ADCC_DrivingFuncInfo_Provider.ADCC_DrivingFuncInfo_NtfNRAInfo_Drvg_SndP -> ADCC_DrivingFuncInfoConsumer_ICC_8155_Android.ADCC_DrivingFuncInfo_NtfNRAInfo_Drvg_RcvP
    connect ADCC_DrivingFuncInfo_Provider.ADCC_DrivingFuncInfo_NtfDrivingSoundInfo_Drvg_SndP -> ADCC_DrivingFuncInfoConsumer_ICC_8155_Android.ADCC_DrivingFuncInfo_NtfDrivingSoundInfo_Drvg_RcvP
    connect ADCC_DrivingFuncInfo_Provider.ADCC_DrivingFuncInfo_NtfMNPInfo_Drvg_SndP -> ADCC_DrivingFuncInfoConsumer_ICC_8155_Android.ADCC_DrivingFuncInfo_NtfMNPInfo_Drvg_RcvP
    connect ADCC_DrivingFuncInfo_Provider.ADCC_DrivingFuncInfo_NtfMNPRoutesInfo_Drvg_SndP -> ADCC_DrivingFuncInfoConsumer_ICC_8155_Android.ADCC_DrivingFuncInfo_NtfMNPRoutesInfo_Drvg_RcvP
    connect ADCC_DrivingFuncInfo_Provider.ADCC_DrivingFuncInfo_NtfIHCInfo_Drvg_SndP -> ADCC_DrivingFuncInfoConsumer_ICC_8155_Android.ADCC_DrivingFuncInfo_NtfIHCInfo_Drvg_RcvP
    connect ADCC_DrivingFuncInfo_Provider.ADCC_DrivingFuncInfo_NtfISLIInfo_Drvg_2_SndP -> ADCC_DrivingFuncInfoConsumer_ICC_8155_Android.ADCC_DrivingFuncInfo_NtfISLIInfo_Drvg_2_RcvP
    connect ADCC_DrivingFuncInfo_Provider.ADCC_DrivingFuncInfo_NtfALCInfo_Drvg_2_SndP -> ADCC_DrivingFuncInfoConsumer_ICC_8155_Android.ADCC_DrivingFuncInfo_NtfALCInfo_Drvg_2_RcvP
    connect ADCC_DrivingFuncInfo_Provider.ADCC_DrivingFuncInfo_NtfICAInfo_Drvg_2_SndP -> ADCC_DrivingFuncInfoConsumer_ICC_8155_Android.ADCC_DrivingFuncInfo_NtfICAInfo_Drvg_2_RcvP
    connect ADCC_DrivingFuncInfo_Provider.ADCC_DrivingFuncInfo_NtfLSSInfo_Drvg_2_SndP -> ADCC_DrivingFuncInfoConsumer_ICC_8155_Android.ADCC_DrivingFuncInfo_NtfLSSInfo_Drvg_2_RcvP
    connect ADCC_DrivingFuncInfo_Provider.ADCC_DrivingFuncInfo_NtfESSInfo_Drvg_2_SndP -> ADCC_DrivingFuncInfoConsumer_ICC_8155_Android.ADCC_DrivingFuncInfo_NtfESSInfo_Drvg_2_RcvP
    connect ADCC_DrivingFuncInfo_Provider.ADCC_DrivingFuncInfo_NtfTrafficSignIdentify_Drvg_SndP -> ADCC_DrivingFuncInfoConsumer_ICC_8155_Android.ADCC_DrivingFuncInfo_NtfTrafficSignIdentify_Drvg_RcvP
    connect ADCC_DrivingFuncInfo_Provider.ADCC_DrivingFuncInfo_NtfACCSupplementInfo_Drvg_SndP -> ADCC_DrivingFuncInfoConsumer_ICC_8155_Android.ADCC_DrivingFuncInfo_NtfACCSupplementInfo_Drvg_RcvP
    connect ADCC_DrivingFuncInfo_Provider.ADCC_DrivingFuncInfo_NtfHNOPSupplementInfo_Drvg_SndP -> ADCC_DrivingFuncInfoConsumer_ICC_8155_Android.ADCC_DrivingFuncInfo_NtfHNOPSupplementInfo_Drvg_RcvP
    connect ADCC_DrivingFuncInfo_Provider.ADCC_DrivingFuncInfo_NtfMNPAllRoutesInfo_Drvg_SndP -> ADCC_DrivingFuncInfoConsumer_ICC_8155_Android.ADCC_DrivingFuncInfo_NtfMNPAllRoutesInfo_Drvg_RcvP
    connect ADCC_DrivingFuncInfo_Provider.ADCC_DrivingFuncInfo_NtfMNPMemRouteInfo_Drvg_SndP -> ADCC_DrivingFuncInfoConsumer_ICC_8155_Android.ADCC_DrivingFuncInfo_NtfMNPMemRouteInfo_Drvg_RcvP
    connect ADCC_DrivingFuncInfo_Provider.ADCC_DrivingFuncInfo_NtfTLRInfo_Drvg_SndP -> ADCC_DrivingFuncInfoConsumer_ICC_8155_Android.ADCC_DrivingFuncInfo_NtfTLRInfo_Drvg_RcvP
    connect ADCC_DrivingFuncInfo_Provider.ADCC_DrivingFuncInfo_NtfTLAInfo_Drvg_SndP -> ADCC_DrivingFuncInfoConsumer_ICC_8155_Android.ADCC_DrivingFuncInfo_NtfTLAInfo_Drvg_RcvP
    connect ADCC_DrivingFuncInfo_Provider.ADCC_DrivingFuncInfo_NtfMNPInfo_Drvg_2_SndP -> ADCC_DrivingFuncInfoConsumer_ICC_8155_Android.ADCC_DrivingFuncInfo_NtfMNPInfo_Drvg_2_RcvP
    connect ADCC_DrivingFuncInfo_Provider.ADCC_DrivingFuncInfo_NtfTrafficSign_Drvg_2_SndP -> ADCC_DrivingFuncInfoConsumer_ICC_8155_Android.ADCC_DrivingFuncInfo_NtfTrafficSign_Drvg_2_RcvP
    connect ADCC_DrivingFuncInfo_Provider.ADCC_DrivingFuncInfo_TolNtfADDrivingCardinfo_SndP -> ADCC_DrivingFuncInfoConsumer_ICC_8155_Android.ADCC_DrivingFuncInfo_TolNtfADDrivingCardinfo_RcvP
    connect ADCC_DrivingFuncInfo_Provider.ADCC_DrivingFuncInfo_SglNtfADDrivingCardinfo_SndP -> ADCC_DrivingFuncInfoConsumer_ICC_8155_Android.ADCC_DrivingFuncInfo_SglNtfADDrivingCardinfo_RcvP
    connect ADCC_DrivingFuncInfo_Provider.ADCC_DrivingFuncInfo_NtfTrafficSign_Drvg_SndP -> ADCC_DrivingFuncInfoConsumer_ICC_8155_QNX.ADCC_DrivingFuncInfo_NtfTrafficSign_Drvg_RcvP
    connect ADCC_DrivingFuncInfo_Provider.ADCC_DrivingFuncInfo_NtfISLIInfo_Drvg_SndP -> ADCC_DrivingFuncInfoConsumer_ICC_8155_QNX.ADCC_DrivingFuncInfo_NtfISLIInfo_Drvg_RcvP
    connect ADCC_DrivingFuncInfo_Provider.ADCC_DrivingFuncInfo_NtfACCInfo_Drvg_SndP -> ADCC_DrivingFuncInfoConsumer_ICC_8155_QNX.ADCC_DrivingFuncInfo_NtfACCInfo_Drvg_RcvP
    connect ADCC_DrivingFuncInfo_Provider.ADCC_DrivingFuncInfo_NtfALCInfo_Drvg_SndP -> ADCC_DrivingFuncInfoConsumer_ICC_8155_QNX.ADCC_DrivingFuncInfo_NtfALCInfo_Drvg_RcvP
    connect ADCC_DrivingFuncInfo_Provider.ADCC_DrivingFuncInfo_NtfICAInfo_Drvg_SndP -> ADCC_DrivingFuncInfoConsumer_ICC_8155_QNX.ADCC_DrivingFuncInfo_NtfICAInfo_Drvg_RcvP
    connect ADCC_DrivingFuncInfo_Provider.ADCC_DrivingFuncInfo_NtfIntelligentEvasionInfo_Drvg_SndP -> ADCC_DrivingFuncInfoConsumer_ICC_8155_QNX.ADCC_DrivingFuncInfo_NtfIntelligentEvasionInfo_Drvg_RcvP
    connect ADCC_DrivingFuncInfo_Provider.ADCC_DrivingFuncInfo_NtfHNOPfunctionInfo_Drvg_SndP -> ADCC_DrivingFuncInfoConsumer_ICC_8155_QNX.ADCC_DrivingFuncInfo_NtfHNOPfunctionInfo_Drvg_RcvP
    connect ADCC_DrivingFuncInfo_Provider.ADCC_DrivingFuncInfo_NtfUNOPfunctionInfo_Drvg_SndP -> ADCC_DrivingFuncInfoConsumer_ICC_8155_QNX.ADCC_DrivingFuncInfo_NtfUNOPfunctionInfo_Drvg_RcvP
    connect ADCC_DrivingFuncInfo_Provider.ADCC_DrivingFuncInfo_NtfHodDmsInfo_Drvg_SndP -> ADCC_DrivingFuncInfoConsumer_ICC_8155_QNX.ADCC_DrivingFuncInfo_NtfHodDmsInfo_Drvg_RcvP
    connect ADCC_DrivingFuncInfo_Provider.ADCC_DrivingFuncInfo_NtfLSSInfo_Drvg_SndP -> ADCC_DrivingFuncInfoConsumer_ICC_8155_QNX.ADCC_DrivingFuncInfo_NtfLSSInfo_Drvg_RcvP
    connect ADCC_DrivingFuncInfo_Provider.ADCC_DrivingFuncInfo_NtfESSInfo_Drvg_SndP -> ADCC_DrivingFuncInfoConsumer_ICC_8155_QNX.ADCC_DrivingFuncInfo_NtfESSInfo_Drvg_RcvP
    connect ADCC_DrivingFuncInfo_Provider.ADCC_DrivingFuncInfo_NtfDAIInfo_Drvg_SndP -> ADCC_DrivingFuncInfoConsumer_ICC_8155_QNX.ADCC_DrivingFuncInfo_NtfDAIInfo_Drvg_RcvP
    connect ADCC_DrivingFuncInfo_Provider.ADCC_DrivingFuncInfo_NtfNRAInfo_Drvg_SndP -> ADCC_DrivingFuncInfoConsumer_ICC_8155_QNX.ADCC_DrivingFuncInfo_NtfNRAInfo_Drvg_RcvP
    connect ADCC_DrivingFuncInfo_Provider.ADCC_DrivingFuncInfo_NtfDrivingSoundInfo_Drvg_SndP -> ADCC_DrivingFuncInfoConsumer_ICC_8155_QNX.ADCC_DrivingFuncInfo_NtfDrivingSoundInfo_Drvg_RcvP
    connect ADCC_DrivingFuncInfo_Provider.ADCC_DrivingFuncInfo_NtfMNPInfo_Drvg_SndP -> ADCC_DrivingFuncInfoConsumer_ICC_8155_QNX.ADCC_DrivingFuncInfo_NtfMNPInfo_Drvg_RcvP
    connect ADCC_DrivingFuncInfo_Provider.ADCC_DrivingFuncInfo_NtfMNPRoutesInfo_Drvg_SndP -> ADCC_DrivingFuncInfoConsumer_ICC_8155_QNX.ADCC_DrivingFuncInfo_NtfMNPRoutesInfo_Drvg_RcvP
    connect ADCC_DrivingFuncInfo_Provider.ADCC_DrivingFuncInfo_NtfIHCInfo_Drvg_SndP -> ADCC_DrivingFuncInfoConsumer_ICC_8155_QNX.ADCC_DrivingFuncInfo_NtfIHCInfo_Drvg_RcvP
    connect ADCC_DrivingFuncInfo_Provider.ADCC_DrivingFuncInfo_NtfISLIInfo_Drvg_2_SndP -> ADCC_DrivingFuncInfoConsumer_ICC_8155_QNX.ADCC_DrivingFuncInfo_NtfISLIInfo_Drvg_2_RcvP
    connect ADCC_DrivingFuncInfo_Provider.ADCC_DrivingFuncInfo_NtfALCInfo_Drvg_2_SndP -> ADCC_DrivingFuncInfoConsumer_ICC_8155_QNX.ADCC_DrivingFuncInfo_NtfALCInfo_Drvg_2_RcvP
    connect ADCC_DrivingFuncInfo_Provider.ADCC_DrivingFuncInfo_NtfICAInfo_Drvg_2_SndP -> ADCC_DrivingFuncInfoConsumer_ICC_8155_QNX.ADCC_DrivingFuncInfo_NtfICAInfo_Drvg_2_RcvP
    connect ADCC_DrivingFuncInfo_Provider.ADCC_DrivingFuncInfo_NtfLSSInfo_Drvg_2_SndP -> ADCC_DrivingFuncInfoConsumer_ICC_8155_QNX.ADCC_DrivingFuncInfo_NtfLSSInfo_Drvg_2_RcvP
    connect ADCC_DrivingFuncInfo_Provider.ADCC_DrivingFuncInfo_NtfESSInfo_Drvg_2_SndP -> ADCC_DrivingFuncInfoConsumer_ICC_8155_QNX.ADCC_DrivingFuncInfo_NtfESSInfo_Drvg_2_RcvP
    connect ADCC_DrivingFuncInfo_Provider.ADCC_DrivingFuncInfo_NtfTrafficSignIdentify_Drvg_SndP -> ADCC_DrivingFuncInfoConsumer_ICC_8155_QNX.ADCC_DrivingFuncInfo_NtfTrafficSignIdentify_Drvg_RcvP
    connect ADCC_DrivingFuncInfo_Provider.ADCC_DrivingFuncInfo_NtfACCSupplementInfo_Drvg_SndP -> ADCC_DrivingFuncInfoConsumer_ICC_8155_QNX.ADCC_DrivingFuncInfo_NtfACCSupplementInfo_Drvg_RcvP
    connect ADCC_DrivingFuncInfo_Provider.ADCC_DrivingFuncInfo_NtfHNOPSupplementInfo_Drvg_SndP -> ADCC_DrivingFuncInfoConsumer_ICC_8155_QNX.ADCC_DrivingFuncInfo_NtfHNOPSupplementInfo_Drvg_RcvP
    connect ADCC_DrivingFuncInfo_Provider.ADCC_DrivingFuncInfo_NtfMNPAllRoutesInfo_Drvg_SndP -> ADCC_DrivingFuncInfoConsumer_ICC_8155_QNX.ADCC_DrivingFuncInfo_NtfMNPAllRoutesInfo_Drvg_RcvP
    connect ADCC_DrivingFuncInfo_Provider.ADCC_DrivingFuncInfo_NtfMNPMemRouteInfo_Drvg_SndP -> ADCC_DrivingFuncInfoConsumer_ICC_8155_QNX.ADCC_DrivingFuncInfo_NtfMNPMemRouteInfo_Drvg_RcvP
    connect ADCC_DrivingFuncInfo_Provider.ADCC_DrivingFuncInfo_NtfTLRInfo_Drvg_SndP -> ADCC_DrivingFuncInfoConsumer_ICC_8155_QNX.ADCC_DrivingFuncInfo_NtfTLRInfo_Drvg_RcvP
    connect ADCC_DrivingFuncInfo_Provider.ADCC_DrivingFuncInfo_NtfTLAInfo_Drvg_SndP -> ADCC_DrivingFuncInfoConsumer_ICC_8155_QNX.ADCC_DrivingFuncInfo_NtfTLAInfo_Drvg_RcvP
    connect ADCC_DrivingFuncInfo_Provider.ADCC_DrivingFuncInfo_NtfMNPInfo_Drvg_2_SndP -> ADCC_DrivingFuncInfoConsumer_ICC_8155_QNX.ADCC_DrivingFuncInfo_NtfMNPInfo_Drvg_2_RcvP
    connect ADCC_DrivingFuncInfo_Provider.ADCC_DrivingFuncInfo_NtfTrafficSign_Drvg_2_SndP -> ADCC_DrivingFuncInfoConsumer_ICC_8155_QNX.ADCC_DrivingFuncInfo_NtfTrafficSign_Drvg_2_RcvP
    connect ADCC_DrivingFuncInfo_Provider.ADCC_DrivingFuncInfo_TolNtfADDrivingCardinfo_SndP -> ADCC_DrivingFuncInfoConsumer_ICC_8155_QNX.ADCC_DrivingFuncInfo_TolNtfADDrivingCardinfo_RcvP
    connect ADCC_DrivingFuncInfo_Provider.ADCC_DrivingFuncInfo_SglNtfADDrivingCardinfo_SndP -> ADCC_DrivingFuncInfoConsumer_ICC_8155_QNX.ADCC_DrivingFuncInfo_SglNtfADDrivingCardinfo_RcvP
    connect ADCC_ParkingFuncInfo_Provider.ADCC_ParkingFuncInfo_NtfParkingGenaralInfo_SndP -> ADCC_ParkingFuncInfoConsumer_ICC_8155_Android.ADCC_ParkingFuncInfo_NtfParkingGenaralInfo_RcvP
    connect ADCC_ParkingFuncInfo_Provider.ADCC_ParkingFuncInfo_NtfAPARPAInfo_SndP -> ADCC_ParkingFuncInfoConsumer_ICC_8155_Android.ADCC_ParkingFuncInfo_NtfAPARPAInfo_RcvP
    connect ADCC_ParkingFuncInfo_Provider.ADCC_ParkingFuncInfo_NtfAdvanceParkingInfo_SndP -> ADCC_ParkingFuncInfoConsumer_ICC_8155_Android.ADCC_ParkingFuncInfo_NtfAdvanceParkingInfo_RcvP
    connect ADCC_ParkingFuncInfo_Provider.ADCC_ParkingFuncInfo_NtfHPAPathDetail_SndP -> ADCC_ParkingFuncInfoConsumer_ICC_8155_Android.ADCC_ParkingFuncInfo_NtfHPAPathDetail_RcvP
    connect ADCC_ParkingFuncInfo_Provider.ADCC_ParkingFuncInfo_NtfHPATrainigPathInfo_SndP -> ADCC_ParkingFuncInfoConsumer_ICC_8155_Android.ADCC_ParkingFuncInfo_NtfHPATrainigPathInfo_RcvP
    connect ADCC_ParkingFuncInfo_Provider.ADCC_ParkingFuncInfo_NtfVPASelfBuildMapDate_SndP -> ADCC_ParkingFuncInfoConsumer_ICC_8155_Android.ADCC_ParkingFuncInfo_NtfVPASelfBuildMapDate_RcvP
    connect ADCC_ParkingFuncInfo_Provider.ADCC_ParkingFuncInfo_NtfMRAInfo_SndP -> ADCC_ParkingFuncInfoConsumer_ICC_8155_Android.ADCC_ParkingFuncInfo_NtfMRAInfo_RcvP
    connect ADCC_ParkingFuncInfo_Provider.ADCC_ParkingFuncInfo_NtfMEBInfo_SndP -> ADCC_ParkingFuncInfoConsumer_ICC_8155_Android.ADCC_ParkingFuncInfo_NtfMEBInfo_RcvP
    connect ADCC_ParkingFuncInfo_Provider.ADCC_ParkingFuncInfo_NtfMAAInfo_SndP -> ADCC_ParkingFuncInfoConsumer_ICC_8155_Android.ADCC_ParkingFuncInfo_NtfMAAInfo_RcvP
    connect ADCC_ParkingFuncInfo_Provider.ADCC_ParkingFuncInfo_NtfHPARepalyPathInfo_SndP -> ADCC_ParkingFuncInfoConsumer_ICC_8155_Android.ADCC_ParkingFuncInfo_NtfHPARepalyPathInfo_RcvP
    connect ADCC_ParkingFuncInfo_Provider.ADCC_ParkingFuncInfo_NtfParkingGenaralInfo_2_SndP -> ADCC_ParkingFuncInfoConsumer_ICC_8155_Android.ADCC_ParkingFuncInfo_NtfParkingGenaralInfo_2_RcvP
    connect ADCC_ParkingFuncInfo_Provider.ADCC_ParkingFuncInfo_NtfMRAInfo_2_SndP -> ADCC_ParkingFuncInfoConsumer_ICC_8155_Android.ADCC_ParkingFuncInfo_NtfMRAInfo_2_RcvP
    connect ADCC_ParkingFuncInfo_Provider.ADCC_ParkingFuncInfo_NtfAPARPAInfo_2_SndP -> ADCC_ParkingFuncInfoConsumer_ICC_8155_Android.ADCC_ParkingFuncInfo_NtfAPARPAInfo_2_RcvP
    connect ADCC_ParkingFuncInfo_Provider.ADCC_ParkingFuncInfo_NtfAdvanceParkingInfo_2_SndP -> ADCC_ParkingFuncInfoConsumer_ICC_8155_Android.ADCC_ParkingFuncInfo_NtfAdvanceParkingInfo_2_RcvP
    connect ADCC_ParkingFuncInfo_Provider.ADCC_ParkingFuncInfo_NtfHPAPathDetail_2_SndP -> ADCC_ParkingFuncInfoConsumer_ICC_8155_Android.ADCC_ParkingFuncInfo_NtfHPAPathDetail_2_RcvP
    connect ADCC_ParkingFuncInfo_Provider.ADCC_ParkingFuncInfo_NtfHPATrainigPathInfo_2_SndP -> ADCC_ParkingFuncInfoConsumer_ICC_8155_Android.ADCC_ParkingFuncInfo_NtfHPATrainigPathInfo_2_RcvP
    connect ADCC_ParkingFuncInfo_Provider.ADCC_ParkingFuncInfo_NtfHPARepalyPathInfo_2_SndP -> ADCC_ParkingFuncInfoConsumer_ICC_8155_Android.ADCC_ParkingFuncInfo_NtfHPARepalyPathInfo_2_RcvP
    connect ADCC_ParkingFuncInfo_Provider.ADCC_ParkingFuncInfo_NtfVPAInfo_SndP -> ADCC_ParkingFuncInfoConsumer_ICC_8155_Android.ADCC_ParkingFuncInfo_NtfVPAInfo_RcvP
    connect ADCC_ParkingFuncInfo_Provider.ADCC_ParkingFuncInfo_NtfParkingHMIInfo_SndP -> ADCC_ParkingFuncInfoConsumer_ICC_8155_Android.ADCC_ParkingFuncInfo_NtfParkingHMIInfo_RcvP
    connect ADCC_ParkingFuncInfo_Provider.ADCC_ParkingFuncInfo_NtfParkingGenaralInfo_SndP -> ADCC_ParkingFuncInfoConsumer_ICC_8155_QNX.ADCC_ParkingFuncInfo_NtfParkingGenaralInfo_RcvP
    connect ADCC_ParkingFuncInfo_Provider.ADCC_ParkingFuncInfo_NtfAPARPAInfo_SndP -> ADCC_ParkingFuncInfoConsumer_ICC_8155_QNX.ADCC_ParkingFuncInfo_NtfAPARPAInfo_RcvP
    connect ADCC_ParkingFuncInfo_Provider.ADCC_ParkingFuncInfo_NtfAdvanceParkingInfo_SndP -> ADCC_ParkingFuncInfoConsumer_ICC_8155_QNX.ADCC_ParkingFuncInfo_NtfAdvanceParkingInfo_RcvP
    connect ADCC_ParkingFuncInfo_Provider.ADCC_ParkingFuncInfo_NtfHPAPathDetail_SndP -> ADCC_ParkingFuncInfoConsumer_ICC_8155_QNX.ADCC_ParkingFuncInfo_NtfHPAPathDetail_RcvP
    connect ADCC_ParkingFuncInfo_Provider.ADCC_ParkingFuncInfo_NtfHPATrainigPathInfo_SndP -> ADCC_ParkingFuncInfoConsumer_ICC_8155_QNX.ADCC_ParkingFuncInfo_NtfHPATrainigPathInfo_RcvP
    connect ADCC_ParkingFuncInfo_Provider.ADCC_ParkingFuncInfo_NtfVPASelfBuildMapDate_SndP -> ADCC_ParkingFuncInfoConsumer_ICC_8155_QNX.ADCC_ParkingFuncInfo_NtfVPASelfBuildMapDate_RcvP
    connect ADCC_ParkingFuncInfo_Provider.ADCC_ParkingFuncInfo_NtfMRAInfo_SndP -> ADCC_ParkingFuncInfoConsumer_ICC_8155_QNX.ADCC_ParkingFuncInfo_NtfMRAInfo_RcvP
    connect ADCC_ParkingFuncInfo_Provider.ADCC_ParkingFuncInfo_NtfMEBInfo_SndP -> ADCC_ParkingFuncInfoConsumer_ICC_8155_QNX.ADCC_ParkingFuncInfo_NtfMEBInfo_RcvP
    connect ADCC_ParkingFuncInfo_Provider.ADCC_ParkingFuncInfo_NtfMAAInfo_SndP -> ADCC_ParkingFuncInfoConsumer_ICC_8155_QNX.ADCC_ParkingFuncInfo_NtfMAAInfo_RcvP
    connect ADCC_ParkingFuncInfo_Provider.ADCC_ParkingFuncInfo_NtfHPARepalyPathInfo_SndP -> ADCC_ParkingFuncInfoConsumer_ICC_8155_QNX.ADCC_ParkingFuncInfo_NtfHPARepalyPathInfo_RcvP
    connect ADCC_ParkingFuncInfo_Provider.ADCC_ParkingFuncInfo_NtfParkingGenaralInfo_2_SndP -> ADCC_ParkingFuncInfoConsumer_ICC_8155_QNX.ADCC_ParkingFuncInfo_NtfParkingGenaralInfo_2_RcvP
    connect ADCC_ParkingFuncInfo_Provider.ADCC_ParkingFuncInfo_NtfMRAInfo_2_SndP -> ADCC_ParkingFuncInfoConsumer_ICC_8155_QNX.ADCC_ParkingFuncInfo_NtfMRAInfo_2_RcvP
    connect ADCC_ParkingFuncInfo_Provider.ADCC_ParkingFuncInfo_NtfAPARPAInfo_2_SndP -> ADCC_ParkingFuncInfoConsumer_ICC_8155_QNX.ADCC_ParkingFuncInfo_NtfAPARPAInfo_2_RcvP
    connect ADCC_ParkingFuncInfo_Provider.ADCC_ParkingFuncInfo_NtfAdvanceParkingInfo_2_SndP -> ADCC_ParkingFuncInfoConsumer_ICC_8155_QNX.ADCC_ParkingFuncInfo_NtfAdvanceParkingInfo_2_RcvP
    connect ADCC_ParkingFuncInfo_Provider.ADCC_ParkingFuncInfo_NtfHPAPathDetail_2_SndP -> ADCC_ParkingFuncInfoConsumer_ICC_8155_QNX.ADCC_ParkingFuncInfo_NtfHPAPathDetail_2_RcvP
    connect ADCC_ParkingFuncInfo_Provider.ADCC_ParkingFuncInfo_NtfHPATrainigPathInfo_2_SndP -> ADCC_ParkingFuncInfoConsumer_ICC_8155_QNX.ADCC_ParkingFuncInfo_NtfHPATrainigPathInfo_2_RcvP
    connect ADCC_ParkingFuncInfo_Provider.ADCC_ParkingFuncInfo_NtfHPARepalyPathInfo_2_SndP -> ADCC_ParkingFuncInfoConsumer_ICC_8155_QNX.ADCC_ParkingFuncInfo_NtfHPARepalyPathInfo_2_RcvP
    connect ADCC_ParkingFuncInfo_Provider.ADCC_ParkingFuncInfo_NtfVPAInfo_SndP -> ADCC_ParkingFuncInfoConsumer_ICC_8155_QNX.ADCC_ParkingFuncInfo_NtfVPAInfo_RcvP
    connect ADCC_ParkingFuncInfo_Provider.ADCC_ParkingFuncInfo_NtfParkingHMIInfo_SndP -> ADCC_ParkingFuncInfoConsumer_ICC_8155_QNX.ADCC_ParkingFuncInfo_NtfParkingHMIInfo_RcvP
    connect ADCC_ParkingHmiEnv_Provider.ADCC_ParkingHmiEnv_NtfDynamicObjectList_Prkg_SndP -> ADCC_ParkingHmiEnvConsumer_ICC_8155_Android.ADCC_ParkingHmiEnv_NtfDynamicObjectList_Prkg_RcvP
    connect ADCC_ParkingHmiEnv_Provider.ADCC_ParkingHmiEnv_NtfStaticObjectList_Prkg_SndP -> ADCC_ParkingHmiEnvConsumer_ICC_8155_Android.ADCC_ParkingHmiEnv_NtfStaticObjectList_Prkg_RcvP
    connect ADCC_ParkingHmiEnv_Provider.ADCC_ParkingHmiEnv_NtfParkingSlot_Prkg_SndP -> ADCC_ParkingHmiEnvConsumer_ICC_8155_Android.ADCC_ParkingHmiEnv_NtfParkingSlot_Prkg_RcvP
    connect ADCC_ParkingHmiEnv_Provider.ADCC_ParkingHmiEnv_NtfHPAStaticObjectList_Prkg_SndP -> ADCC_ParkingHmiEnvConsumer_ICC_8155_Android.ADCC_ParkingHmiEnv_NtfHPAStaticObjectList_Prkg_RcvP
    connect ADCC_ParkingHmiEnv_Provider.ADCC_ParkingHmiEnv_NtfHPAParkingSlot_Prkg_SndP -> ADCC_ParkingHmiEnvConsumer_ICC_8155_Android.ADCC_ParkingHmiEnv_NtfHPAParkingSlot_Prkg_RcvP
    connect ADCC_ParkingHmiEnv_Provider.ADCC_ParkingHmiEnv_NtfVPASelfBuildMapInfo_SndP -> ADCC_ParkingHmiEnvConsumer_ICC_8155_Android.ADCC_ParkingHmiEnv_NtfVPASelfBuildMapInfo_RcvP
    connect ADCC_ParkingHmiEnv_Provider.ADCC_ParkingHmiEnv_NtfVPAParkingLotInfo_SndP -> ADCC_ParkingHmiEnvConsumer_ICC_8155_Android.ADCC_ParkingHmiEnv_NtfVPAParkingLotInfo_RcvP
    connect ADCC_ParkingHmiEnv_Provider.ADCC_ParkingHmiEnv_NtfDynamicObjectList_Prkg_2_SndP -> ADCC_ParkingHmiEnvConsumer_ICC_8155_Android.ADCC_ParkingHmiEnv_NtfDynamicObjectList_Prkg_2_RcvP
    connect ADCC_ParkingHmiEnv_Provider.ADCC_ParkingHmiEnv_NtfStaticObjectList_Prkg_2_SndP -> ADCC_ParkingHmiEnvConsumer_ICC_8155_Android.ADCC_ParkingHmiEnv_NtfStaticObjectList_Prkg_2_RcvP
    connect ADCC_ParkingHmiEnv_Provider.ADCC_ParkingHmiEnv_NtfDynamicObjectList_Prkg_SndP -> ADCC_ParkingHmiEnvConsumer_ICC_8155_QNX.ADCC_ParkingHmiEnv_NtfDynamicObjectList_Prkg_RcvP
    connect ADCC_ParkingHmiEnv_Provider.ADCC_ParkingHmiEnv_NtfStaticObjectList_Prkg_SndP -> ADCC_ParkingHmiEnvConsumer_ICC_8155_QNX.ADCC_ParkingHmiEnv_NtfStaticObjectList_Prkg_RcvP
    connect ADCC_ParkingHmiEnv_Provider.ADCC_ParkingHmiEnv_NtfParkingSlot_Prkg_SndP -> ADCC_ParkingHmiEnvConsumer_ICC_8155_QNX.ADCC_ParkingHmiEnv_NtfParkingSlot_Prkg_RcvP
    connect ADCC_ParkingHmiEnv_Provider.ADCC_ParkingHmiEnv_NtfHPAStaticObjectList_Prkg_SndP -> ADCC_ParkingHmiEnvConsumer_ICC_8155_QNX.ADCC_ParkingHmiEnv_NtfHPAStaticObjectList_Prkg_RcvP
    connect ADCC_ParkingHmiEnv_Provider.ADCC_ParkingHmiEnv_NtfHPAParkingSlot_Prkg_SndP -> ADCC_ParkingHmiEnvConsumer_ICC_8155_QNX.ADCC_ParkingHmiEnv_NtfHPAParkingSlot_Prkg_RcvP
    connect ADCC_ParkingHmiEnv_Provider.ADCC_ParkingHmiEnv_NtfVPASelfBuildMapInfo_SndP -> ADCC_ParkingHmiEnvConsumer_ICC_8155_QNX.ADCC_ParkingHmiEnv_NtfVPASelfBuildMapInfo_RcvP
    connect ADCC_ParkingHmiEnv_Provider.ADCC_ParkingHmiEnv_NtfVPAParkingLotInfo_SndP -> ADCC_ParkingHmiEnvConsumer_ICC_8155_QNX.ADCC_ParkingHmiEnv_NtfVPAParkingLotInfo_RcvP
    connect ADCC_ParkingHmiEnv_Provider.ADCC_ParkingHmiEnv_NtfDynamicObjectList_Prkg_2_SndP -> ADCC_ParkingHmiEnvConsumer_ICC_8155_QNX.ADCC_ParkingHmiEnv_NtfDynamicObjectList_Prkg_2_RcvP
    connect ADCC_ParkingHmiEnv_Provider.ADCC_ParkingHmiEnv_NtfStaticObjectList_Prkg_2_SndP -> ADCC_ParkingHmiEnvConsumer_ICC_8155_QNX.ADCC_ParkingHmiEnv_NtfStaticObjectList_Prkg_2_RcvP
    connect ADCC_AomMMSt_Provider.ADCC_AomMMSt_notifyExtMMResWLnk_SndP -> ADCC_AomMMStConsumer_ICC_8155_Android.ADCC_AomMMSt_notifyExtMMResWLnk_RcvP
    connect ADCC_AomMMSt_Provider.ADCC_AomMMSt_HDMapInfo_SndP -> ADCC_AomMMStConsumer_ICC_8155_Android.ADCC_AomMMSt_HDMapInfo_RcvP
    connect ADCC_AomMMSt_Provider.ADCC_AomMMSt_notifyExtMMResWLnk_SndP -> ADCC_AomMMStConsumer_ICC_8155_QNX.ADCC_AomMMSt_notifyExtMMResWLnk_RcvP
    connect ADCC_AomMMSt_Provider.ADCC_AomMMSt_HDMapInfo_SndP -> ADCC_AomMMStConsumer_ICC_8155_QNX.ADCC_AomMMSt_HDMapInfo_RcvP
    connect ADCC_RtMM_Provider.ADCC_RtMM_notifyRtMatchRes_SndP -> ADCC_RtMMConsumer_ICC_8155_Android.ADCC_RtMM_notifyRtMatchRes_RcvP
    connect ADCC_RtMM_Provider.ADCC_RtMM_notifyRtMatchRes_SndP -> ADCC_RtMMConsumer_ICC_8155_QNX.ADCC_RtMM_notifyRtMatchRes_RcvP
    connect FCM_DrivingHmiEnv_Provider.FCM_DrivingHmiEnv_NtfDynamicObjectList_SndP -> FCM_DrivingHmiEnvConsumer_ICC_8155_QNX.FCM_DrivingHmiEnv_NtfDynamicObjectList_RcvP
    connect FCM_DrivingHmiEnv_Provider.FCM_DrivingHmiEnv_NtfStaticObjectList_SndP -> FCM_DrivingHmiEnvConsumer_ICC_8155_QNX.FCM_DrivingHmiEnv_NtfStaticObjectList_RcvP
    connect FCM_DrivingHmiEnv_Provider.FCM_DrivingHmiEnv_NtfLaneLineList_SndP -> FCM_DrivingHmiEnvConsumer_ICC_8155_QNX.FCM_DrivingHmiEnv_NtfLaneLineList_RcvP
    connect FCM_DrivingHmiEnv_Provider.FCM_DrivingHmiEnv_NtfLaneLineList_2_SndP -> FCM_DrivingHmiEnvConsumer_ICC_8155_QNX.FCM_DrivingHmiEnv_NtfLaneLineList_2_RcvP
    connect FCM_DrivingHmiEnv_Provider.FCM_DrivingHmiEnv_NtfEgoFusionPose_SndP -> FCM_DrivingHmiEnvConsumer_ICC_8155_QNX.FCM_DrivingHmiEnv_NtfEgoFusionPose_RcvP
    connect FCM_DrivingHmiEnv_Provider.FCM_DrivingHmiEnv_NtfDynamicObjectList_2_SndP -> FCM_DrivingHmiEnvConsumer_ICC_8155_QNX.FCM_DrivingHmiEnv_NtfDynamicObjectList_2_RcvP
    connect FCM_DrivingHmiEnv_Provider.FCM_DrivingHmiEnv_NtfStaticObjectList_2_SndP -> FCM_DrivingHmiEnvConsumer_ICC_8155_QNX.FCM_DrivingHmiEnv_NtfStaticObjectList_2_RcvP
    connect FCM_DrivingHmiEnv_Provider.FCM_DrivingHmiEnv_NtfDynamicObjectList_SndP -> FCM_DrivingHmiEnvConsumer_ICC_8155_Android.FCM_DrivingHmiEnv_NtfDynamicObjectList_RcvP
    connect FCM_DrivingHmiEnv_Provider.FCM_DrivingHmiEnv_NtfStaticObjectList_SndP -> FCM_DrivingHmiEnvConsumer_ICC_8155_Android.FCM_DrivingHmiEnv_NtfStaticObjectList_RcvP
    connect FCM_DrivingHmiEnv_Provider.FCM_DrivingHmiEnv_NtfLaneLineList_SndP -> FCM_DrivingHmiEnvConsumer_ICC_8155_Android.FCM_DrivingHmiEnv_NtfLaneLineList_RcvP
    connect FCM_DrivingHmiEnv_Provider.FCM_DrivingHmiEnv_NtfLaneLineList_2_SndP -> FCM_DrivingHmiEnvConsumer_ICC_8155_Android.FCM_DrivingHmiEnv_NtfLaneLineList_2_RcvP
    connect FCM_DrivingHmiEnv_Provider.FCM_DrivingHmiEnv_NtfEgoFusionPose_SndP -> FCM_DrivingHmiEnvConsumer_ICC_8155_Android.FCM_DrivingHmiEnv_NtfEgoFusionPose_RcvP
    connect FCM_DrivingHmiEnv_Provider.FCM_DrivingHmiEnv_NtfDynamicObjectList_2_SndP -> FCM_DrivingHmiEnvConsumer_ICC_8155_Android.FCM_DrivingHmiEnv_NtfDynamicObjectList_2_RcvP
    connect FCM_DrivingHmiEnv_Provider.FCM_DrivingHmiEnv_NtfStaticObjectList_2_SndP -> FCM_DrivingHmiEnvConsumer_ICC_8155_Android.FCM_DrivingHmiEnv_NtfStaticObjectList_2_RcvP
    connect FCM_ActiveSafetyInfo_Provider.FCM_ActiveSafetyInfo_NtfActiveSafetyFcnInfo_SndP -> FCM_ActiveSafetyInfoConsumer_ICC_8155_Android.FCM_ActiveSafetyInfo_NtfActiveSafetyFcnInfo_RcvP
    connect FCM_ActiveSafetyInfo_Provider.FCM_ActiveSafetyInfo_NtfAEBTargetObjInfo_SndP -> FCM_ActiveSafetyInfoConsumer_ICC_8155_Android.FCM_ActiveSafetyInfo_NtfAEBTargetObjInfo_RcvP
    connect FCM_ActiveSafetyInfo_Provider.FCM_ActiveSafetyInfo_NtfActiveSafetyFcnInfo_2_SndP -> FCM_ActiveSafetyInfoConsumer_ICC_8155_Android.FCM_ActiveSafetyInfo_NtfActiveSafetyFcnInfo_2_RcvP
    connect FCM_ActiveSafetyInfo_Provider.FCM_ActiveSafetyInfo_NtfAEBTargetObjInfo_2_SndP -> FCM_ActiveSafetyInfoConsumer_ICC_8155_Android.FCM_ActiveSafetyInfo_NtfAEBTargetObjInfo_2_RcvP
    connect FCM_ActiveSafetyInfo_Provider.FCM_ActiveSafetyInfo_NtfActiveSafetyFcnInfo_SndP -> FCM_ActiveSafetyInfoConsumer_ICC_8155_QNX.FCM_ActiveSafetyInfo_NtfActiveSafetyFcnInfo_RcvP
    connect FCM_ActiveSafetyInfo_Provider.FCM_ActiveSafetyInfo_NtfAEBTargetObjInfo_SndP -> FCM_ActiveSafetyInfoConsumer_ICC_8155_QNX.FCM_ActiveSafetyInfo_NtfAEBTargetObjInfo_RcvP
    connect FCM_ActiveSafetyInfo_Provider.FCM_ActiveSafetyInfo_NtfActiveSafetyFcnInfo_2_SndP -> FCM_ActiveSafetyInfoConsumer_ICC_8155_QNX.FCM_ActiveSafetyInfo_NtfActiveSafetyFcnInfo_2_RcvP
    connect FCM_ActiveSafetyInfo_Provider.FCM_ActiveSafetyInfo_NtfAEBTargetObjInfo_2_SndP -> FCM_ActiveSafetyInfoConsumer_ICC_8155_QNX.FCM_ActiveSafetyInfo_NtfAEBTargetObjInfo_2_RcvP
    connect FCM_DrivingFuncInfo_Provider.FCM_DrivingFuncInfo_NtfTrafficSign_SndP -> FCM_DrivingFuncInfoConsumer_ICC_8155_Android.FCM_DrivingFuncInfo_NtfTrafficSign_RcvP
    connect FCM_DrivingFuncInfo_Provider.FCM_DrivingFuncInfo_NtfISLIinfo_SndP -> FCM_DrivingFuncInfoConsumer_ICC_8155_Android.FCM_DrivingFuncInfo_NtfISLIinfo_RcvP
    connect FCM_DrivingFuncInfo_Provider.FCM_DrivingFuncInfo_NtfACCinfo_SndP -> FCM_DrivingFuncInfoConsumer_ICC_8155_Android.FCM_DrivingFuncInfo_NtfACCinfo_RcvP
    connect FCM_DrivingFuncInfo_Provider.FCM_DrivingFuncInfo_NtfICAInfo_SndP -> FCM_DrivingFuncInfoConsumer_ICC_8155_Android.FCM_DrivingFuncInfo_NtfICAInfo_RcvP
    connect FCM_DrivingFuncInfo_Provider.FCM_DrivingFuncInfo_NtfIntelligentEvasionInfo_SndP -> FCM_DrivingFuncInfoConsumer_ICC_8155_Android.FCM_DrivingFuncInfo_NtfIntelligentEvasionInfo_RcvP
    connect FCM_DrivingFuncInfo_Provider.FCM_DrivingFuncInfo_NtfHodDmsInfo_SndP -> FCM_DrivingFuncInfoConsumer_ICC_8155_Android.FCM_DrivingFuncInfo_NtfHodDmsInfo_RcvP
    connect FCM_DrivingFuncInfo_Provider.FCM_DrivingFuncInfo_NtfLSSInfo_SndP -> FCM_DrivingFuncInfoConsumer_ICC_8155_Android.FCM_DrivingFuncInfo_NtfLSSInfo_RcvP
    connect FCM_DrivingFuncInfo_Provider.FCM_DrivingFuncInfo_NtfESSInfo_SndP -> FCM_DrivingFuncInfoConsumer_ICC_8155_Android.FCM_DrivingFuncInfo_NtfESSInfo_RcvP
    connect FCM_DrivingFuncInfo_Provider.FCM_DrivingFuncInfo_NtfDAIInfo_SndP -> FCM_DrivingFuncInfoConsumer_ICC_8155_Android.FCM_DrivingFuncInfo_NtfDAIInfo_RcvP
    connect FCM_DrivingFuncInfo_Provider.FCM_DrivingFuncInfo_NtfISLIinfo_2_SndP -> FCM_DrivingFuncInfoConsumer_ICC_8155_Android.FCM_DrivingFuncInfo_NtfISLIinfo_2_RcvP
    connect FCM_DrivingFuncInfo_Provider.FCM_DrivingFuncInfo_NtfLSSInfo_2_SndP -> FCM_DrivingFuncInfoConsumer_ICC_8155_Android.FCM_DrivingFuncInfo_NtfLSSInfo_2_RcvP
    connect FCM_DrivingFuncInfo_Provider.FCM_DrivingFuncInfo_NtfDrivingSoundInfo_SndP -> FCM_DrivingFuncInfoConsumer_ICC_8155_Android.FCM_DrivingFuncInfo_NtfDrivingSoundInfo_RcvP
    connect FCM_DrivingFuncInfo_Provider.FCM_DrivingFuncInfo_NtfIHCInfo_SndP -> FCM_DrivingFuncInfoConsumer_ICC_8155_Android.FCM_DrivingFuncInfo_NtfIHCInfo_RcvP
    connect FCM_DrivingFuncInfo_Provider.FCM_DrivingFuncInfo_NtfHNOPfunctionInfo_SndP -> FCM_DrivingFuncInfoConsumer_ICC_8155_Android.FCM_DrivingFuncInfo_NtfHNOPfunctionInfo_RcvP
    connect FCM_DrivingFuncInfo_Provider.FCM_DrivingFuncInfo_NtfTrafficSign_SndP -> FCM_DrivingFuncInfoConsumer_ICC_8155_QNX.FCM_DrivingFuncInfo_NtfTrafficSign_RcvP
    connect FCM_DrivingFuncInfo_Provider.FCM_DrivingFuncInfo_NtfISLIinfo_SndP -> FCM_DrivingFuncInfoConsumer_ICC_8155_QNX.FCM_DrivingFuncInfo_NtfISLIinfo_RcvP
    connect FCM_DrivingFuncInfo_Provider.FCM_DrivingFuncInfo_NtfACCinfo_SndP -> FCM_DrivingFuncInfoConsumer_ICC_8155_QNX.FCM_DrivingFuncInfo_NtfACCinfo_RcvP
    connect FCM_DrivingFuncInfo_Provider.FCM_DrivingFuncInfo_NtfICAInfo_SndP -> FCM_DrivingFuncInfoConsumer_ICC_8155_QNX.FCM_DrivingFuncInfo_NtfICAInfo_RcvP
    connect FCM_DrivingFuncInfo_Provider.FCM_DrivingFuncInfo_NtfIntelligentEvasionInfo_SndP -> FCM_DrivingFuncInfoConsumer_ICC_8155_QNX.FCM_DrivingFuncInfo_NtfIntelligentEvasionInfo_RcvP
    connect FCM_DrivingFuncInfo_Provider.FCM_DrivingFuncInfo_NtfHodDmsInfo_SndP -> FCM_DrivingFuncInfoConsumer_ICC_8155_QNX.FCM_DrivingFuncInfo_NtfHodDmsInfo_RcvP
    connect FCM_DrivingFuncInfo_Provider.FCM_DrivingFuncInfo_NtfLSSInfo_SndP -> FCM_DrivingFuncInfoConsumer_ICC_8155_QNX.FCM_DrivingFuncInfo_NtfLSSInfo_RcvP
    connect FCM_DrivingFuncInfo_Provider.FCM_DrivingFuncInfo_NtfESSInfo_SndP -> FCM_DrivingFuncInfoConsumer_ICC_8155_QNX.FCM_DrivingFuncInfo_NtfESSInfo_RcvP
    connect FCM_DrivingFuncInfo_Provider.FCM_DrivingFuncInfo_NtfDAIInfo_SndP -> FCM_DrivingFuncInfoConsumer_ICC_8155_QNX.FCM_DrivingFuncInfo_NtfDAIInfo_RcvP
    connect FCM_DrivingFuncInfo_Provider.FCM_DrivingFuncInfo_NtfISLIinfo_2_SndP -> FCM_DrivingFuncInfoConsumer_ICC_8155_QNX.FCM_DrivingFuncInfo_NtfISLIinfo_2_RcvP
    connect FCM_DrivingFuncInfo_Provider.FCM_DrivingFuncInfo_NtfLSSInfo_2_SndP -> FCM_DrivingFuncInfoConsumer_ICC_8155_QNX.FCM_DrivingFuncInfo_NtfLSSInfo_2_RcvP
    connect FCM_DrivingFuncInfo_Provider.FCM_DrivingFuncInfo_NtfDrivingSoundInfo_SndP -> FCM_DrivingFuncInfoConsumer_ICC_8155_QNX.FCM_DrivingFuncInfo_NtfDrivingSoundInfo_RcvP
    connect FCM_DrivingFuncInfo_Provider.FCM_DrivingFuncInfo_NtfIHCInfo_SndP -> FCM_DrivingFuncInfoConsumer_ICC_8155_QNX.FCM_DrivingFuncInfo_NtfIHCInfo_RcvP
    connect FCM_DrivingFuncInfo_Provider.FCM_DrivingFuncInfo_NtfHNOPfunctionInfo_SndP -> FCM_DrivingFuncInfoConsumer_ICC_8155_QNX.FCM_DrivingFuncInfo_NtfHNOPfunctionInfo_RcvP
    connect FCM_DVRSts_Provider.FCM_DVRSts_notifyDVRSts_SndP -> FCM_DVRStsConsumer_ICC_8155_Android.FCM_DVRSts_notifyDVRSts_RcvP
    connect FCM_DVRSts_Provider.FCM_DVRSts_notifyDVRcameraSts_SndP -> FCM_DVRStsConsumer_ICC_8155_Android.FCM_DVRSts_notifyDVRcameraSts_RcvP
    connect FCM_DVRSts_Provider.FCM_DVRSts_notifyCameraInterParm_SndP -> FCM_DVRStsConsumer_ICC_8155_Android.FCM_DVRSts_notifyCameraInterParm_RcvP
    connect FCM_DVRSts_Provider.FCM_DVRSts_notifyDVRSts_SndP -> FCM_DVRStsConsumer_ICC_8155_QNX.FCM_DVRSts_notifyDVRSts_RcvP
    connect FCM_DVRSts_Provider.FCM_DVRSts_notifyDVRcameraSts_SndP -> FCM_DVRStsConsumer_ICC_8155_QNX.FCM_DVRSts_notifyDVRcameraSts_RcvP
    connect FCM_DVRSts_Provider.FCM_DVRSts_notifyCameraInterParm_SndP -> FCM_DVRStsConsumer_ICC_8155_QNX.FCM_DVRSts_notifyCameraInterParm_RcvP
    connect LCM_ICC_Data_Provider.LCM_ICC_Data_NtfIMUInfo_SndP -> LCM_ICC_DataConsumer_ICC_8155_QNX.LCM_ICC_Data_NtfIMUInfo_RcvP
    connect LCM_ADCC_RawData_Provider.LCM_ADCC_RawData_NtfGRawInfo_SndP -> LCM_ADCC_RawDataConsumer_ADCC.LCM_ADCC_RawData_NtfGRawInfo_RcvP
    connect ADCC_ActiveSafetyInfo_Provider.ADCC_ActiveSafetyInfo_NtfActiveSafetyFcnInfo_Act_SndP -> ADCC_ActiveSafetyInfoConsumer_ICC_8155_Android.ADCC_ActiveSafetyInfo_NtfActiveSafetyFcnInfo_Act_RcvP
    connect ADCC_ActiveSafetyInfo_Provider.ADCC_ActiveSafetyInfo_NtfAEBTargetObjInfo_Act_SndP -> ADCC_ActiveSafetyInfoConsumer_ICC_8155_Android.ADCC_ActiveSafetyInfo_NtfAEBTargetObjInfo_Act_RcvP
    connect ADCC_ActiveSafetyInfo_Provider.ADCC_ActiveSafetyInfo_NtfActiveSafetyFcnInfo_Act_2_SndP -> ADCC_ActiveSafetyInfoConsumer_ICC_8155_Android.ADCC_ActiveSafetyInfo_NtfActiveSafetyFcnInfo_Act_2_RcvP
    connect ADCC_ActiveSafetyInfo_Provider.ADCC_ActiveSafetyInfo_NtfAEBTargetObjInfo_Act_2_SndP -> ADCC_ActiveSafetyInfoConsumer_ICC_8155_Android.ADCC_ActiveSafetyInfo_NtfAEBTargetObjInfo_Act_2_RcvP
    connect ADCC_ActiveSafetyInfo_Provider.ADCC_ActiveSafetyInfo_NtfAEBTargetObjInfo_Act_3_SndP -> ADCC_ActiveSafetyInfoConsumer_ICC_8155_Android.ADCC_ActiveSafetyInfo_NtfAEBTargetObjInfo_Act_3_RcvP
    connect ADCC_ActiveSafetyInfo_Provider.ADCC_ActiveSafetyInfo_NtfActiveSafetyFcnInfo_Act_SndP -> ADCC_ActiveSafetyInfoConsumer_ICC_8155_QNX.ADCC_ActiveSafetyInfo_NtfActiveSafetyFcnInfo_Act_RcvP
    connect ADCC_ActiveSafetyInfo_Provider.ADCC_ActiveSafetyInfo_NtfAEBTargetObjInfo_Act_SndP -> ADCC_ActiveSafetyInfoConsumer_ICC_8155_QNX.ADCC_ActiveSafetyInfo_NtfAEBTargetObjInfo_Act_RcvP
    connect ADCC_ActiveSafetyInfo_Provider.ADCC_ActiveSafetyInfo_NtfActiveSafetyFcnInfo_Act_2_SndP -> ADCC_ActiveSafetyInfoConsumer_ICC_8155_QNX.ADCC_ActiveSafetyInfo_NtfActiveSafetyFcnInfo_Act_2_RcvP
    connect ADCC_ActiveSafetyInfo_Provider.ADCC_ActiveSafetyInfo_NtfAEBTargetObjInfo_Act_2_SndP -> ADCC_ActiveSafetyInfoConsumer_ICC_8155_QNX.ADCC_ActiveSafetyInfo_NtfAEBTargetObjInfo_Act_2_RcvP
    connect ADCC_ActiveSafetyInfo_Provider.ADCC_ActiveSafetyInfo_NtfAEBTargetObjInfo_Act_3_SndP -> ADCC_ActiveSafetyInfoConsumer_ICC_8155_QNX.ADCC_ActiveSafetyInfo_NtfAEBTargetObjInfo_Act_3_RcvP
    connect FCM_SensorInfo_Provider.FCM_SensorInfo_NtfSensorSt_FCM_SndP -> FCM_SensorInfoConsumer_ICC_8155_Android.FCM_SensorInfo_NtfSensorSt_FCM_RcvP
    connect FCM_SensorInfo_Provider.FCM_SensorInfo_NtfSensorSt_FCM_SndP -> FCM_SensorInfoConsumer_ICC_8155_QNX.FCM_SensorInfo_NtfSensorSt_FCM_RcvP
    connect TBOX_SystemInfo_ICC_Provider.TBOX_SystemInfo_ICC_Event_NetworkStatus_ICC_SndP -> TBOX_SystemInfo_ICCConsumer_ADCC.TBOX_SystemInfo_ICC_Event_NetworkStatus_ICC_RcvP
    connect ADCC_DVRSts_Provider.ADCC_DVRSts_notifyDVRSts_ADCC_SndP -> ADCC_DVRStsConsumer_ICC_8155_Android.ADCC_DVRSts_notifyDVRSts_ADCC_RcvP
    connect ADCC_DVRSts_Provider.ADCC_DVRSts_notifyDVRcameraSts_ADCC_SndP -> ADCC_DVRStsConsumer_ICC_8155_Android.ADCC_DVRSts_notifyDVRcameraSts_ADCC_RcvP
    connect ADCC_DVRSts_Provider.ADCC_DVRSts_notifyCameraInterParm_ADCC_SndP -> ADCC_DVRStsConsumer_ICC_8155_Android.ADCC_DVRSts_notifyCameraInterParm_ADCC_RcvP
    connect ADCC_DVRSts_Provider.ADCC_DVRSts_notifyDVRSts_ADCC_SndP -> ADCC_DVRStsConsumer_ICC_8155_QNX.ADCC_DVRSts_notifyDVRSts_ADCC_RcvP
    connect ADCC_DVRSts_Provider.ADCC_DVRSts_notifyDVRcameraSts_ADCC_SndP -> ADCC_DVRStsConsumer_ICC_8155_QNX.ADCC_DVRSts_notifyDVRcameraSts_ADCC_RcvP
    connect ADCC_DVRSts_Provider.ADCC_DVRSts_notifyCameraInterParm_ADCC_SndP -> ADCC_DVRStsConsumer_ICC_8155_QNX.ADCC_DVRSts_notifyCameraInterParm_ADCC_RcvP
    connect ADAS_DataInLoop_Provider.ADAS_DataInLoop_notifyData_ID_SndP -> ADAS_DataInLoopConsumer_ICC_8155_Android.ADAS_DataInLoop_notifyData_ID_RcvP
    connect ADAS_DataInLoop_Provider.ADAS_DataInLoop_notifyDataInLoop_{1..3}_SndP -> ADAS_DataInLoopConsumer_ICC_8155_Android.ADAS_DataInLoop_notifyDataInLoop_{1..3}_RcvP
    connect ADAS_DataInLoop_Provider.ADAS_DataInLoop_notifyDataInLoop_SndP -> ADAS_DataInLoopConsumer_ICC_8155_Android.ADAS_DataInLoop_notifyDataInLoop_RcvP
    connect IVI_UnixTimestamp_Provider.IVI_UnixTimestamp_notifyUnixTimestamp_SndP -> IVI_UnixTimestampConsumer_FCM.IVI_UnixTimestamp_notifyUnixTimestamp_RcvP
    connect ADAS_GNSSInfo_Provider.ADAS_GNSSInfo_notifyGNSSInfo_SndP -> ADAS_GNSSInfoConsumer_ICC_8155_Android.ADAS_GNSSInfo_notifyGNSSInfo_RcvP
    connect ADAS_GNSSInfo_Provider.ADAS_GNSSInfo_notifyGNSSInfo_SndP -> ADAS_GNSSInfoConsumer_ICC_8155_QNX.ADAS_GNSSInfo_notifyGNSSInfo_RcvP
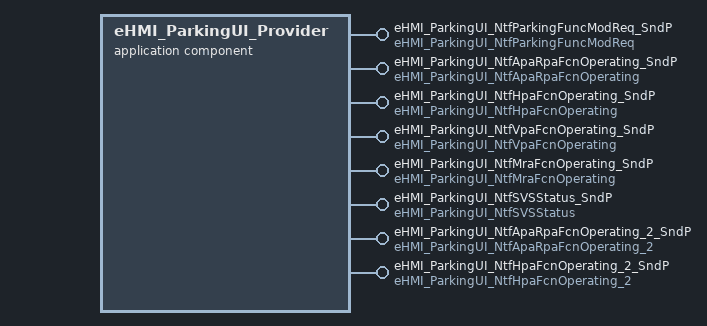
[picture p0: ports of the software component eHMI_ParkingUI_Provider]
  application sw component type eHMI_ParkingUI_Provider
    8 x provide port:
      eHMI_ParkingUI_NtfParkingFuncModReq_SndP: provided-interface=eHMI_ParkingUI_NtfParkingFuncModReq
      eHMI_ParkingUI_NtfApaRpaFcnOperating_SndP: provided-interface=eHMI_ParkingUI_NtfApaRpaFcnOperating
      eHMI_ParkingUI_NtfHpaFcnOperating_SndP: provided-interface=eHMI_ParkingUI_NtfHpaFcnOperating
      eHMI_ParkingUI_NtfVpaFcnOperating_SndP: provided-interface=eHMI_ParkingUI_NtfVpaFcnOperating
      eHMI_ParkingUI_NtfMraFcnOperating_SndP: provided-interface=eHMI_ParkingUI_NtfMraFcnOperating
      eHMI_ParkingUI_NtfSVSStatus_SndP: provided-interface=eHMI_ParkingUI_NtfSVSStatus
      eHMI_ParkingUI_NtfApaRpaFcnOperating_2_SndP: provided-interface=eHMI_ParkingUI_NtfApaRpaFcnOperating_2
      eHMI_ParkingUI_NtfHpaFcnOperating_2_SndP: provided-interface=eHMI_ParkingUI_NtfHpaFcnOperating_2
    behavior InternalBehavior_eHMI_ParkingUI_Provider: data-type-mapping=Data_Type_Mappings
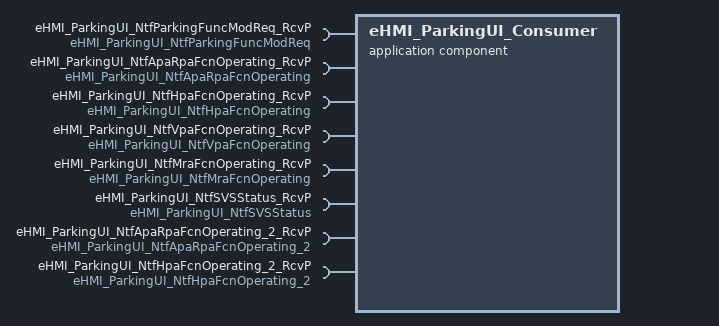
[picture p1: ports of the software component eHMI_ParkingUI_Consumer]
  application sw component type eHMI_ParkingUI_Consumer
    8 x require port:
      eHMI_ParkingUI_NtfParkingFuncModReq_RcvP: required-interface=eHMI_ParkingUI_NtfParkingFuncModReq
      eHMI_ParkingUI_NtfApaRpaFcnOperating_RcvP: required-interface=eHMI_ParkingUI_NtfApaRpaFcnOperating
      eHMI_ParkingUI_NtfHpaFcnOperating_RcvP: required-interface=eHMI_ParkingUI_NtfHpaFcnOperating
      eHMI_ParkingUI_NtfVpaFcnOperating_RcvP: required-interface=eHMI_ParkingUI_NtfVpaFcnOperating
      eHMI_ParkingUI_NtfMraFcnOperating_RcvP: required-interface=eHMI_ParkingUI_NtfMraFcnOperating
      eHMI_ParkingUI_NtfSVSStatus_RcvP: required-interface=eHMI_ParkingUI_NtfSVSStatus
      eHMI_ParkingUI_NtfApaRpaFcnOperating_2_RcvP: required-interface=eHMI_ParkingUI_NtfApaRpaFcnOperating_2
      eHMI_ParkingUI_NtfHpaFcnOperating_2_RcvP: required-interface=eHMI_ParkingUI_NtfHpaFcnOperating_2
    behavior InternalBehavior_eHMI_ParkingUI_Consumer: data-type-mapping=Data_Type_Mappings
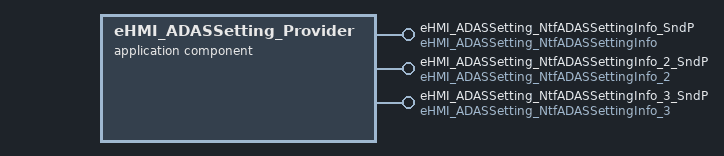
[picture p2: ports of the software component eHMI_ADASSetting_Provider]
  application sw component type eHMI_ADASSetting_Provider
    provide port eHMI_ADASSetting_NtfADASSettingInfo_SndP: provided-interface=eHMI_ADASSetting_NtfADASSettingInfo
    provide port eHMI_ADASSetting_NtfADASSettingInfo_2_SndP: provided-interface=eHMI_ADASSetting_NtfADASSettingInfo_2
    provide port eHMI_ADASSetting_NtfADASSettingInfo_3_SndP: provided-interface=eHMI_ADASSetting_NtfADASSettingInfo_3
    behavior InternalBehavior_eHMI_ADASSetting_Provider: data-type-mapping=Data_Type_Mappings
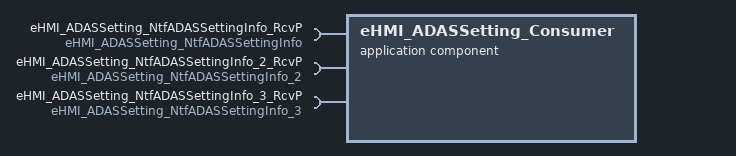
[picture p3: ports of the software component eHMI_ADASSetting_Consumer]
  application sw component type eHMI_ADASSetting_Consumer
    require port eHMI_ADASSetting_NtfADASSettingInfo_RcvP: required-interface=eHMI_ADASSetting_NtfADASSettingInfo
    require port eHMI_ADASSetting_NtfADASSettingInfo_2_RcvP: required-interface=eHMI_ADASSetting_NtfADASSettingInfo_2
    require port eHMI_ADASSetting_NtfADASSettingInfo_3_RcvP: required-interface=eHMI_ADASSetting_NtfADASSettingInfo_3
    behavior InternalBehavior_eHMI_ADASSetting_Consumer: data-type-mapping=Data_Type_Mappings
  application sw component type eHMI_DVRSet_Provider
    provide port eHMI_DVRSet_notifyDVRRequest_SndP: provided-interface=eHMI_DVRSet_notifyDVRRequest
    behavior InternalBehavior_eHMI_DVRSet_Provider: data-type-mapping=Data_Type_Mappings
  application sw component type eHMI_DVRSet_Consumer
    require port eHMI_DVRSet_notifyDVRRequest_RcvP: required-interface=eHMI_DVRSet_notifyDVRRequest
    behavior InternalBehavior_eHMI_DVRSet_Consumer: data-type-mapping=Data_Type_Mappings
  application sw component type TBOX_TimeManagement_Provider
    provide port TBOX_TimeManagement_notifyTimeManagement_SndP: provided-interface=TBOX_TimeManagement_notifyTimeManagement
    behavior InternalBehavior_TBOX_TimeManagement_Provider: data-type-mapping=Data_Type_Mappings
  application sw component type TBOX_TimeManagement_Consumer
    require port TBOX_TimeManagement_notifyTimeManagement_RcvP: required-interface=TBOX_TimeManagement_notifyTimeManagement
    behavior InternalBehavior_TBOX_TimeManagement_Consumer: data-type-mapping=Data_Type_Mappings
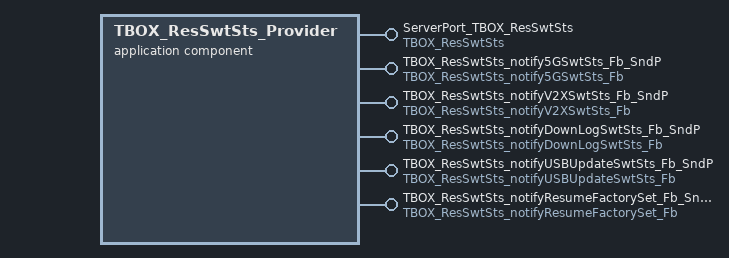
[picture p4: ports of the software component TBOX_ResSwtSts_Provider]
  application sw component type TBOX_ResSwtSts_Provider
    6 x provide port:
      ServerPort_TBOX_ResSwtSts: provided-interface=TBOX_ResSwtSts
      TBOX_ResSwtSts_notify5GSwtSts_Fb_SndP: provided-interface=TBOX_ResSwtSts_notify5GSwtSts_Fb
      TBOX_ResSwtSts_notifyV2XSwtSts_Fb_SndP: provided-interface=TBOX_ResSwtSts_notifyV2XSwtSts_Fb
      TBOX_ResSwtSts_notifyDownLogSwtSts_Fb_SndP: provided-interface=TBOX_ResSwtSts_notifyDownLogSwtSts_Fb
      TBOX_ResSwtSts_notifyUSBUpdateSwtSts_Fb_SndP: provided-interface=TBOX_ResSwtSts_notifyUSBUpdateSwtSts_Fb
      TBOX_ResSwtSts_notifyResumeFactorySet_Fb_SndP: provided-interface=TBOX_ResSwtSts_notifyResumeFactorySet_Fb
    behavior InternalBehavior_TBOX_ResSwtSts_Provider: data-type-mapping=Data_Type_Mappings
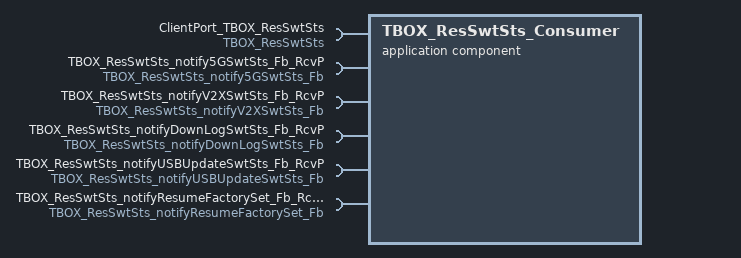
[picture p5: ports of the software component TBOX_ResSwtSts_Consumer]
  application sw component type TBOX_ResSwtSts_Consumer
    6 x require port:
      ClientPort_TBOX_ResSwtSts: required-interface=TBOX_ResSwtSts
      TBOX_ResSwtSts_notify5GSwtSts_Fb_RcvP: required-interface=TBOX_ResSwtSts_notify5GSwtSts_Fb
      TBOX_ResSwtSts_notifyV2XSwtSts_Fb_RcvP: required-interface=TBOX_ResSwtSts_notifyV2XSwtSts_Fb
      TBOX_ResSwtSts_notifyDownLogSwtSts_Fb_RcvP: required-interface=TBOX_ResSwtSts_notifyDownLogSwtSts_Fb
      TBOX_ResSwtSts_notifyUSBUpdateSwtSts_Fb_RcvP: required-interface=TBOX_ResSwtSts_notifyUSBUpdateSwtSts_Fb
      TBOX_ResSwtSts_notifyResumeFactorySet_Fb_RcvP: required-interface=TBOX_ResSwtSts_notifyResumeFactorySet_Fb
    behavior InternalBehavior_TBOX_ResSwtSts_Consumer: data-type-mapping=Data_Type_Mappings
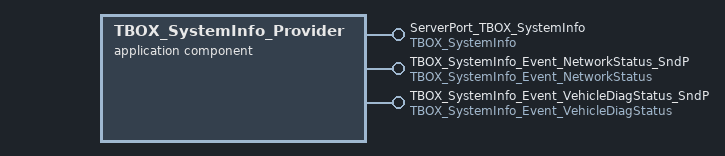
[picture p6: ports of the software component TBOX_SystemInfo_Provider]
  application sw component type TBOX_SystemInfo_Provider
    provide port ServerPort_TBOX_SystemInfo: provided-interface=TBOX_SystemInfo
    provide port TBOX_SystemInfo_Event_NetworkStatus_SndP: provided-interface=TBOX_SystemInfo_Event_NetworkStatus
    provide port TBOX_SystemInfo_Event_VehicleDiagStatus_SndP: provided-interface=TBOX_SystemInfo_Event_VehicleDiagStatus
    behavior InternalBehavior_TBOX_SystemInfo_Provider: data-type-mapping=Data_Type_Mappings
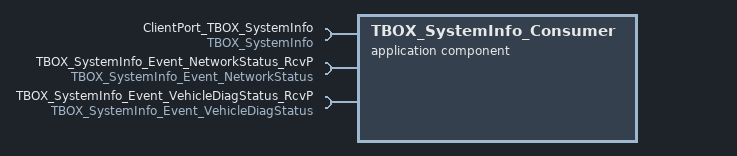
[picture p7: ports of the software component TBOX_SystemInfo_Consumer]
  application sw component type TBOX_SystemInfo_Consumer
    require port ClientPort_TBOX_SystemInfo: required-interface=TBOX_SystemInfo
    require port TBOX_SystemInfo_Event_NetworkStatus_RcvP: required-interface=TBOX_SystemInfo_Event_NetworkStatus
    require port TBOX_SystemInfo_Event_VehicleDiagStatus_RcvP: required-interface=TBOX_SystemInfo_Event_VehicleDiagStatus
    behavior InternalBehavior_TBOX_SystemInfo_Consumer: data-type-mapping=Data_Type_Mappings
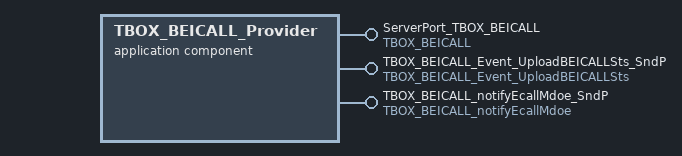
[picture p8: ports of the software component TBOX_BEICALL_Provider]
  application sw component type TBOX_BEICALL_Provider
    provide port ServerPort_TBOX_BEICALL: provided-interface=TBOX_BEICALL
    provide port TBOX_BEICALL_Event_UploadBEICALLSts_SndP: provided-interface=TBOX_BEICALL_Event_UploadBEICALLSts
    provide port TBOX_BEICALL_notifyEcallMdoe_SndP: provided-interface=TBOX_BEICALL_notifyEcallMdoe
    behavior InternalBehavior_TBOX_BEICALL_Provider: data-type-mapping=Data_Type_Mappings
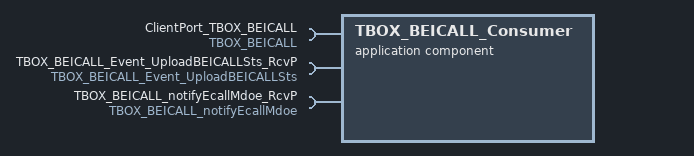
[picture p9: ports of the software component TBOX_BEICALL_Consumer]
  application sw component type TBOX_BEICALL_Consumer
    require port ClientPort_TBOX_BEICALL: required-interface=TBOX_BEICALL
    require port TBOX_BEICALL_Event_UploadBEICALLSts_RcvP: required-interface=TBOX_BEICALL_Event_UploadBEICALLSts
    require port TBOX_BEICALL_notifyEcallMdoe_RcvP: required-interface=TBOX_BEICALL_notifyEcallMdoe
    behavior InternalBehavior_TBOX_BEICALL_Consumer: data-type-mapping=Data_Type_Mappings
  application sw component type TBOX_USBUpdate_Provider
    provide port ServerPort_TBOX_USBUpdate: provided-interface=TBOX_USBUpdate
    provide port TBOX_USBUpdate_Event_UsbUpdateSta_SndP: provided-interface=TBOX_USBUpdate_Event_UsbUpdateSta
    require port TBOX_USBUpdate_FF_UpdateCompleted_RcvP: required-interface=TBOX_USBUpdate_FF_UpdateCompleted
    behavior InternalBehavior_TBOX_USBUpdate_Provider: data-type-mapping=Data_Type_Mappings
  application sw component type TBOX_USBUpdate_Consumer
    require port ClientPort_TBOX_USBUpdate: required-interface=TBOX_USBUpdate
    require port TBOX_USBUpdate_Event_UsbUpdateSta_RcvP: required-interface=TBOX_USBUpdate_Event_UsbUpdateSta
    provide port TBOX_USBUpdate_FF_UpdateCompleted_SndP: provided-interface=TBOX_USBUpdate_FF_UpdateCompleted
    behavior InternalBehavior_TBOX_USBUpdate_Consumer: data-type-mapping=Data_Type_Mappings
  application sw component type TBOX_USBTBOXlog_Provider
    provide port ServerPort_TBOX_USBTBOXlog: provided-interface=TBOX_USBTBOXlog
    behavior InternalBehavior_TBOX_USBTBOXlog_Provider: data-type-mapping=Data_Type_Mappings
  application sw component type TBOX_USBTBOXlog_Consumer
    require port ClientPort_TBOX_USBTBOXlog: required-interface=TBOX_USBTBOXlog
    behavior InternalBehavior_TBOX_USBTBOXlog_Consumer: data-type-mapping=Data_Type_Mappings
  application sw component type TBOX_GNSSInfo_Provider
    provide port ServerPort_TBOX_GNSSInfo: provided-interface=TBOX_GNSSInfo
    provide port TBOX_GNSSInfo_Event_GNSSInfo1_SndP: provided-interface=TBOX_GNSSInfo_Event_GNSSInfo1
    behavior InternalBehavior_TBOX_GNSSInfo_Provider: data-type-mapping=Data_Type_Mappings
  application sw component type TBOX_GNSSInfo_Consumer
    require port ClientPort_TBOX_GNSSInfo: required-interface=TBOX_GNSSInfo
    require port TBOX_GNSSInfo_Event_GNSSInfo1_RcvP: required-interface=TBOX_GNSSInfo_Event_GNSSInfo1
    behavior InternalBehavior_TBOX_GNSSInfo_Consumer: data-type-mapping=Data_Type_Mappings
  application sw component type ICC_Android_OutService_Provider
    provide port ICC_Android_OutService_notifyEcallMdoeFed_SndP: provided-interface=ICC_Android_OutService_notifyEcallMdoeFed
    behavior InternalBehavior_ICC_Android_OutService_Provider: data-type-mapping=Data_Type_Mappings
  application sw component type ICC_Android_OutService_Consumer
    require port ICC_Android_OutService_notifyEcallMdoeFed_RcvP: required-interface=ICC_Android_OutService_notifyEcallMdoeFed
    behavior InternalBehavior_ICC_Android_OutService_Consumer: data-type-mapping=Data_Type_Mappings
  application sw component type ICC_Aom_Provider
    provide port ServerPort_ICC_Aom: provided-interface=ICC_Aom
    provide port ICC_Aom_notifyADCC_Command_SndP: provided-interface=ICC_Aom_notifyADCC_Command
    behavior InternalBehavior_ICC_Aom_Provider: data-type-mapping=Data_Type_Mappings
  application sw component type ICC_Aom_Consumer
    require port ClientPort_ICC_Aom: required-interface=ICC_Aom
    require port ICC_Aom_notifyADCC_Command_RcvP: required-interface=ICC_Aom_notifyADCC_Command
    behavior InternalBehavior_ICC_Aom_Consumer: data-type-mapping=Data_Type_Mappings
  application sw component type ICC_SDmapInfo_Provider
    9 x provide port:
      ICC_SDmapInfo_NtfSDmapInfo_SndP: provided-interface=ICC_SDmapInfo_NtfSDmapInfo
      ICC_SDmapInfo_notifyNOA_SDMapPosInfo_SndP: provided-interface=ICC_SDmapInfo_notifyNOA_SDMapPosInfo
      ICC_SDmapInfo_notifyNOA_SDMapStubInfo_SndP: provided-interface=ICC_SDmapInfo_notifyNOA_SDMapStubInfo
      ICC_SDmapInfo_notifyNOA_SDMapSegmentInfo_SndP: provided-interface=ICC_SDmapInfo_notifyNOA_SDMapSegmentInfo
      ICC_SDmapInfo_notifyNOA_SDMapShortInfo_SndP: provided-interface=ICC_SDmapInfo_notifyNOA_SDMapShortInfo
      ICC_SDmapInfo_notifyNOA_SDMapLongInfo_SndP: provided-interface=ICC_SDmapInfo_notifyNOA_SDMapLongInfo
      ICC_SDmapInfo_notifyNOA_SDMapMetaInfo_SndP: provided-interface=ICC_SDmapInfo_notifyNOA_SDMapMetaInfo
      ICC_SDmapInfo_NtfSDmapInfo_international_SndP: provided-interface=ICC_SDmapInfo_NtfSDmapInfo_international
      ICC_SDmapInfo_NtfSDmapLaneInfo_SndP: provided-interface=ICC_SDmapInfo_NtfSDmapLaneInfo
    behavior InternalBehavior_ICC_SDmapInfo_Provider: data-type-mapping=Data_Type_Mappings
  application sw component type ICC_SDmapInfo_Consumer
    9 x require port:
      ICC_SDmapInfo_NtfSDmapInfo_RcvP: required-interface=ICC_SDmapInfo_NtfSDmapInfo
      ICC_SDmapInfo_notifyNOA_SDMapPosInfo_RcvP: required-interface=ICC_SDmapInfo_notifyNOA_SDMapPosInfo
      ICC_SDmapInfo_notifyNOA_SDMapStubInfo_RcvP: required-interface=ICC_SDmapInfo_notifyNOA_SDMapStubInfo
      ICC_SDmapInfo_notifyNOA_SDMapSegmentInfo_RcvP: required-interface=ICC_SDmapInfo_notifyNOA_SDMapSegmentInfo
      ICC_SDmapInfo_notifyNOA_SDMapShortInfo_RcvP: required-interface=ICC_SDmapInfo_notifyNOA_SDMapShortInfo
      ICC_SDmapInfo_notifyNOA_SDMapLongInfo_RcvP: required-interface=ICC_SDmapInfo_notifyNOA_SDMapLongInfo
      ICC_SDmapInfo_notifyNOA_SDMapMetaInfo_RcvP: required-interface=ICC_SDmapInfo_notifyNOA_SDMapMetaInfo
      ICC_SDmapInfo_NtfSDmapInfo_international_RcvP: required-interface=ICC_SDmapInfo_NtfSDmapInfo_international
      ICC_SDmapInfo_NtfSDmapLaneInfo_RcvP: required-interface=ICC_SDmapInfo_NtfSDmapLaneInfo
    behavior InternalBehavior_ICC_SDmapInfo_Consumer: data-type-mapping=Data_Type_Mappings
  application sw component type ICC_SDmapInfo_2_Provider
    26 x provide port:
      ICC_SDmapInfo_2_NtfSDmapRouteInfo_SndP: provided-interface=ICC_SDmapInfo_2_NtfSDmapRouteInfo
      ICC_SDmapInfo_2_NtfSDmapTBTNaviInfo_SndP: provided-interface=ICC_SDmapInfo_2_NtfSDmapTBTNaviInfo
      ICC_SDmapInfo_2_NtfSDmapNaviCameraInfo_SndP: provided-interface=ICC_SDmapInfo_2_NtfSDmapNaviCameraInfo
      ICC_SDmapInfo_2_NtfSDmapCruiseFacilityInfo_SndP: provided-interface=ICC_SDmapInfo_2_NtfSDmapCruiseFacilityInfo
      ICC_SDmapInfo_2_NtfSDmapTrafficLightCDInfo_SndP: provided-interface=ICC_SDmapInfo_2_NtfSDmapTrafficLightCDInfo
      ICC_SDmapInfo_2_NtfSDmapNaviIntCamDynInfo_SndP: provided-interface=ICC_SDmapInfo_2_NtfSDmapNaviIntCamDynInfo
      ICC_SDmapInfo_2_NtfSDmapNaviWeatherInfo_SndP: provided-interface=ICC_SDmapInfo_2_NtfSDmapNaviWeatherInfo
      ICC_SDmapInfo_2_NtfSDmapNaviCongestionInfo_SndP: provided-interface=ICC_SDmapInfo_2_NtfSDmapNaviCongestionInfo
      ICC_SDmapInfo_2_NtfSDmapNaviGreenWaveCarSpd_SndP: provided-interface=ICC_SDmapInfo_2_NtfSDmapNaviGreenWaveCarSpd
      ICC_SDmapInfo_2_notifySDmapLaneInfo_SndP: provided-interface=ICC_SDmapInfo_2_notifySDmapLaneInfo
      ICC_SDmapInfo_2_NtfSDmapMixForkInfo_SndP: provided-interface=ICC_SDmapInfo_2_NtfSDmapMixForkInfo
      ICC_SDmapInfo_2_NtfSDmapMyLocationInfo_SndP: provided-interface=ICC_SDmapInfo_2_NtfSDmapMyLocationInfo
      ICC_SDmapInfo_2_NtfSDmapNaviStatusInfo_SndP: provided-interface=ICC_SDmapInfo_2_NtfSDmapNaviStatusInfo
      ICC_SDmapInfo_2_NtfSDmapSoundInfo_SndP: provided-interface=ICC_SDmapInfo_2_NtfSDmapSoundInfo
      ICC_SDmapInfo_2_NtfSDmapRouteOption_SndP: provided-interface=ICC_SDmapInfo_2_NtfSDmapRouteOption
      ICC_SDmapInfo_2_NtfSDmapCruiseInfo_SndP: provided-interface=ICC_SDmapInfo_2_NtfSDmapCruiseInfo
      ICC_SDmapInfo_2_NtfSDmapNaviRoadInfo_SndP: provided-interface=ICC_SDmapInfo_2_NtfSDmapNaviRoadInfo
      ICC_SDmapInfo_2_NtfSDmapAheadLaneInfo_SndP: provided-interface=ICC_SDmapInfo_2_NtfSDmapAheadLaneInfo
      ICC_SDmapInfo_2_NtfSDmapTollGateInfo_SndP: provided-interface=ICC_SDmapInfo_2_NtfSDmapTollGateInfo
      ICC_SDmapInfo_2_NtfSDmapServiceAreaInfo_SndP: provided-interface=ICC_SDmapInfo_2_NtfSDmapServiceAreaInfo
      ICC_SDmapInfo_2_NtfSDmapTunnelInfo_SndP: provided-interface=ICC_SDmapInfo_2_NtfSDmapTunnelInfo
      ICC_SDmapInfo_2_NtfSDmapRampInfo_SndP: provided-interface=ICC_SDmapInfo_2_NtfSDmapRampInfo
      ICC_SDmapInfo_2_NtfSDmapFacilityInfo_SndP: provided-interface=ICC_SDmapInfo_2_NtfSDmapFacilityInfo
      ICC_SDmapInfo_2_NtfSDmapLocMatchInfo_SndP: provided-interface=ICC_SDmapInfo_2_NtfSDmapLocMatchInfo
      ICC_SDmapInfo_2_notifySDmapTollGateLaneInfo_SndP: provided-interface=ICC_SDmapInfo_2_notifySDmapTollGateLaneInfo
      ICC_SDmapInfo_2_notifySDmapNavArriveAim_SndP: provided-interface=ICC_SDmapInfo_2_notifySDmapNavArriveAim
    behavior InternalBehavior_ICC_SDmapInfo_2_Provider: data-type-mapping=Data_Type_Mappings
  application sw component type ICC_SDmapInfo_2_Consumer
    26 x require port:
      ICC_SDmapInfo_2_NtfSDmapRouteInfo_RcvP: required-interface=ICC_SDmapInfo_2_NtfSDmapRouteInfo
      ICC_SDmapInfo_2_NtfSDmapTBTNaviInfo_RcvP: required-interface=ICC_SDmapInfo_2_NtfSDmapTBTNaviInfo
      ICC_SDmapInfo_2_NtfSDmapNaviCameraInfo_RcvP: required-interface=ICC_SDmapInfo_2_NtfSDmapNaviCameraInfo
      ICC_SDmapInfo_2_NtfSDmapCruiseFacilityInfo_RcvP: required-interface=ICC_SDmapInfo_2_NtfSDmapCruiseFacilityInfo
      ICC_SDmapInfo_2_NtfSDmapTrafficLightCDInfo_RcvP: required-interface=ICC_SDmapInfo_2_NtfSDmapTrafficLightCDInfo
      ICC_SDmapInfo_2_NtfSDmapNaviIntCamDynInfo_RcvP: required-interface=ICC_SDmapInfo_2_NtfSDmapNaviIntCamDynInfo
      ICC_SDmapInfo_2_NtfSDmapNaviWeatherInfo_RcvP: required-interface=ICC_SDmapInfo_2_NtfSDmapNaviWeatherInfo
      ICC_SDmapInfo_2_NtfSDmapNaviCongestionInfo_RcvP: required-interface=ICC_SDmapInfo_2_NtfSDmapNaviCongestionInfo
      ICC_SDmapInfo_2_NtfSDmapNaviGreenWaveCarSpd_RcvP: required-interface=ICC_SDmapInfo_2_NtfSDmapNaviGreenWaveCarSpd
      ICC_SDmapInfo_2_notifySDmapLaneInfo_RcvP: required-interface=ICC_SDmapInfo_2_notifySDmapLaneInfo
      ICC_SDmapInfo_2_NtfSDmapMixForkInfo_RcvP: required-interface=ICC_SDmapInfo_2_NtfSDmapMixForkInfo
      ICC_SDmapInfo_2_NtfSDmapMyLocationInfo_RcvP: required-interface=ICC_SDmapInfo_2_NtfSDmapMyLocationInfo
      ICC_SDmapInfo_2_NtfSDmapNaviStatusInfo_RcvP: required-interface=ICC_SDmapInfo_2_NtfSDmapNaviStatusInfo
      ICC_SDmapInfo_2_NtfSDmapSoundInfo_RcvP: required-interface=ICC_SDmapInfo_2_NtfSDmapSoundInfo
      ICC_SDmapInfo_2_NtfSDmapRouteOption_RcvP: required-interface=ICC_SDmapInfo_2_NtfSDmapRouteOption
      ICC_SDmapInfo_2_NtfSDmapCruiseInfo_RcvP: required-interface=ICC_SDmapInfo_2_NtfSDmapCruiseInfo
      ICC_SDmapInfo_2_NtfSDmapNaviRoadInfo_RcvP: required-interface=ICC_SDmapInfo_2_NtfSDmapNaviRoadInfo
      ICC_SDmapInfo_2_NtfSDmapAheadLaneInfo_RcvP: required-interface=ICC_SDmapInfo_2_NtfSDmapAheadLaneInfo
      ICC_SDmapInfo_2_NtfSDmapTollGateInfo_RcvP: required-interface=ICC_SDmapInfo_2_NtfSDmapTollGateInfo
      ICC_SDmapInfo_2_NtfSDmapServiceAreaInfo_RcvP: required-interface=ICC_SDmapInfo_2_NtfSDmapServiceAreaInfo
      ICC_SDmapInfo_2_NtfSDmapTunnelInfo_RcvP: required-interface=ICC_SDmapInfo_2_NtfSDmapTunnelInfo
      ICC_SDmapInfo_2_NtfSDmapRampInfo_RcvP: required-interface=ICC_SDmapInfo_2_NtfSDmapRampInfo
      ICC_SDmapInfo_2_NtfSDmapFacilityInfo_RcvP: required-interface=ICC_SDmapInfo_2_NtfSDmapFacilityInfo
      ICC_SDmapInfo_2_NtfSDmapLocMatchInfo_RcvP: required-interface=ICC_SDmapInfo_2_NtfSDmapLocMatchInfo
      ICC_SDmapInfo_2_notifySDmapTollGateLaneInfo_RcvP: required-interface=ICC_SDmapInfo_2_notifySDmapTollGateLaneInfo
      ICC_SDmapInfo_2_notifySDmapNavArriveAim_RcvP: required-interface=ICC_SDmapInfo_2_notifySDmapNavArriveAim
    behavior InternalBehavior_ICC_SDmapInfo_2_Consumer: data-type-mapping=Data_Type_Mappings
  application sw component type ADCC_DrivingHmiEnv_Provider
    16 x provide port:
      ADCC_DrivingHmiEnv_NtfDynamicObjectList_Drvg_SndP: provided-interface=ADCC_DrivingHmiEnv_NtfDynamicObjectList_Drvg
      ADCC_DrivingHmiEnv_NtfStaticObjectList_Drvg_SndP: provided-interface=ADCC_DrivingHmiEnv_NtfStaticObjectList_Drvg
      ADCC_DrivingHmiEnv_NtfLaneLineListt_Drvg_SndP: provided-interface=ADCC_DrivingHmiEnv_NtfLaneLineListt_Drvg
      ADCC_DrivingHmiEnv_NtfEgoFusionPose_Drvg_SndP: provided-interface=ADCC_DrivingHmiEnv_NtfEgoFusionPose_Drvg
      ADCC_DrivingHmiEnv_NtfRoadMarkerList_SndP: provided-interface=ADCC_DrivingHmiEnv_NtfRoadMarkerList
      ADCC_DrivingHmiEnv_NtfLaneLineListt_Drvg_2_SndP: provided-interface=ADCC_DrivingHmiEnv_NtfLaneLineListt_Drvg_2
      ADCC_DrivingHmiEnv_NtfEgoPose_SndP: provided-interface=ADCC_DrivingHmiEnv_NtfEgoPose
      ADCC_DrivingHmiEnv_NtfFusionMapData_SndP: provided-interface=ADCC_DrivingHmiEnv_NtfFusionMapData
      ADCC_DrivingHmiEnv_NtfRoadMarkerListSupplement_SndP: provided-interface=ADCC_DrivingHmiEnv_NtfRoadMarkerListSupplement
      ADCC_DrivingHmiEnv_NtfTrafficLightList_Drvg_SndP: provided-interface=ADCC_DrivingHmiEnv_NtfTrafficLightList_Drvg
      ADCC_DrivingHmiEnv_NtfFreeSpaceList_Drvg_SndP: provided-interface=ADCC_DrivingHmiEnv_NtfFreeSpaceList_Drvg
      ADCC_DrivingHmiEnv_Ntf3DTrafficSignList_Drvg_SndP: provided-interface=ADCC_DrivingHmiEnv_Ntf3DTrafficSignList_Drvg
      ADCC_DrivingHmiEnv_NtfDynamicObjectList_Drvg_2_SndP: provided-interface=ADCC_DrivingHmiEnv_NtfDynamicObjectList_Drvg_2
      ADCC_DrivingHmiEnv_NtfStaticObjectList_Drvg_2_SndP: provided-interface=ADCC_DrivingHmiEnv_NtfStaticObjectList_Drvg_2
      ADCC_DrivingHmiEnv_NtfRoadMarkerList_2_SndP: provided-interface=ADCC_DrivingHmiEnv_NtfRoadMarkerList_2
      ADCC_DrivingHmiEnv_NtfRoadSurfaceMes_SndP: provided-interface=ADCC_DrivingHmiEnv_NtfRoadSurfaceMes
    behavior InternalBehavior_ADCC_DrivingHmiEnv_Provider: data-type-mapping=Data_Type_Mappings
  application sw component type ADCC_DrivingHmiEnv_Consumer
    16 x require port:
      ADCC_DrivingHmiEnv_NtfDynamicObjectList_Drvg_RcvP: required-interface=ADCC_DrivingHmiEnv_NtfDynamicObjectList_Drvg
      ADCC_DrivingHmiEnv_NtfStaticObjectList_Drvg_RcvP: required-interface=ADCC_DrivingHmiEnv_NtfStaticObjectList_Drvg
      ADCC_DrivingHmiEnv_NtfLaneLineListt_Drvg_RcvP: required-interface=ADCC_DrivingHmiEnv_NtfLaneLineListt_Drvg
      ADCC_DrivingHmiEnv_NtfEgoFusionPose_Drvg_RcvP: required-interface=ADCC_DrivingHmiEnv_NtfEgoFusionPose_Drvg
      ADCC_DrivingHmiEnv_NtfRoadMarkerList_RcvP: required-interface=ADCC_DrivingHmiEnv_NtfRoadMarkerList
      ADCC_DrivingHmiEnv_NtfLaneLineListt_Drvg_2_RcvP: required-interface=ADCC_DrivingHmiEnv_NtfLaneLineListt_Drvg_2
      ADCC_DrivingHmiEnv_NtfEgoPose_RcvP: required-interface=ADCC_DrivingHmiEnv_NtfEgoPose
      ADCC_DrivingHmiEnv_NtfFusionMapData_RcvP: required-interface=ADCC_DrivingHmiEnv_NtfFusionMapData
      ADCC_DrivingHmiEnv_NtfRoadMarkerListSupplement_RcvP: required-interface=ADCC_DrivingHmiEnv_NtfRoadMarkerListSupplement
      ADCC_DrivingHmiEnv_NtfTrafficLightList_Drvg_RcvP: required-interface=ADCC_DrivingHmiEnv_NtfTrafficLightList_Drvg
      ADCC_DrivingHmiEnv_NtfFreeSpaceList_Drvg_RcvP: required-interface=ADCC_DrivingHmiEnv_NtfFreeSpaceList_Drvg
      ADCC_DrivingHmiEnv_Ntf3DTrafficSignList_Drvg_RcvP: required-interface=ADCC_DrivingHmiEnv_Ntf3DTrafficSignList_Drvg
      ADCC_DrivingHmiEnv_NtfDynamicObjectList_Drvg_2_RcvP: required-interface=ADCC_DrivingHmiEnv_NtfDynamicObjectList_Drvg_2
      ADCC_DrivingHmiEnv_NtfStaticObjectList_Drvg_2_RcvP: required-interface=ADCC_DrivingHmiEnv_NtfStaticObjectList_Drvg_2
      ADCC_DrivingHmiEnv_NtfRoadMarkerList_2_RcvP: required-interface=ADCC_DrivingHmiEnv_NtfRoadMarkerList_2
      ADCC_DrivingHmiEnv_NtfRoadSurfaceMes_RcvP: required-interface=ADCC_DrivingHmiEnv_NtfRoadSurfaceMes
    behavior InternalBehavior_ADCC_DrivingHmiEnv_Consumer: data-type-mapping=Data_Type_Mappings
  application sw component type ADCC_SensorInfo_Provider
    provide port ServerPort_ADCC_SensorInfo: provided-interface=ADCC_SensorInfo
    provide port ADCC_SensorInfo_NtfSensorSt_SndP: provided-interface=ADCC_SensorInfo_NtfSensorSt
    provide port ADCC_SensorInfo_CamStreamStResp_SndP: provided-interface=ADCC_SensorInfo_CamStreamStResp
    require port ADCC_SensorInfo_CamStreamSwtReq_RcvP: required-interface=ADCC_SensorInfo_CamStreamSwtReq
    behavior InternalBehavior_ADCC_SensorInfo_Provider: data-type-mapping=Data_Type_Mappings
  application sw component type ADCC_SensorInfo_Consumer
    require port ClientPort_ADCC_SensorInfo: required-interface=ADCC_SensorInfo
    require port ADCC_SensorInfo_NtfSensorSt_RcvP: required-interface=ADCC_SensorInfo_NtfSensorSt
    require port ADCC_SensorInfo_CamStreamStResp_RcvP: required-interface=ADCC_SensorInfo_CamStreamStResp
    provide port ADCC_SensorInfo_CamStreamSwtReq_SndP: provided-interface=ADCC_SensorInfo_CamStreamSwtReq
    behavior InternalBehavior_ADCC_SensorInfo_Consumer: data-type-mapping=Data_Type_Mappings
  application sw component type ADCC_DrivingFuncInfo_Provider
    33 x provide port:
      ADCC_DrivingFuncInfo_NtfTrafficSign_Drvg_SndP: provided-interface=ADCC_DrivingFuncInfo_NtfTrafficSign_Drvg
      ADCC_DrivingFuncInfo_NtfISLIInfo_Drvg_SndP: provided-interface=ADCC_DrivingFuncInfo_NtfISLIInfo_Drvg
      ADCC_DrivingFuncInfo_NtfACCInfo_Drvg_SndP: provided-interface=ADCC_DrivingFuncInfo_NtfACCInfo_Drvg
      ADCC_DrivingFuncInfo_NtfALCInfo_Drvg_SndP: provided-interface=ADCC_DrivingFuncInfo_NtfALCInfo_Drvg
      ADCC_DrivingFuncInfo_NtfICAInfo_Drvg_SndP: provided-interface=ADCC_DrivingFuncInfo_NtfICAInfo_Drvg
      ADCC_DrivingFuncInfo_NtfIntelligentEvasionInfo_Drvg_SndP: provided-interface=ADCC_DrivingFuncInfo_NtfIntelligentEvasionInfo_Drvg
      ADCC_DrivingFuncInfo_NtfHNOPfunctionInfo_Drvg_SndP: provided-interface=ADCC_DrivingFuncInfo_NtfHNOPfunctionInfo_Drvg
      ADCC_DrivingFuncInfo_NtfUNOPfunctionInfo_Drvg_SndP: provided-interface=ADCC_DrivingFuncInfo_NtfUNOPfunctionInfo_Drvg
      ADCC_DrivingFuncInfo_NtfHodDmsInfo_Drvg_SndP: provided-interface=ADCC_DrivingFuncInfo_NtfHodDmsInfo_Drvg
      ADCC_DrivingFuncInfo_NtfLSSInfo_Drvg_SndP: provided-interface=ADCC_DrivingFuncInfo_NtfLSSInfo_Drvg
      ADCC_DrivingFuncInfo_NtfESSInfo_Drvg_SndP: provided-interface=ADCC_DrivingFuncInfo_NtfESSInfo_Drvg
      ADCC_DrivingFuncInfo_NtfDAIInfo_Drvg_SndP: provided-interface=ADCC_DrivingFuncInfo_NtfDAIInfo_Drvg
      ADCC_DrivingFuncInfo_NtfNRAInfo_Drvg_SndP: provided-interface=ADCC_DrivingFuncInfo_NtfNRAInfo_Drvg
      ADCC_DrivingFuncInfo_NtfDrivingSoundInfo_Drvg_SndP: provided-interface=ADCC_DrivingFuncInfo_NtfDrivingSoundInfo_Drvg
      ADCC_DrivingFuncInfo_NtfMNPInfo_Drvg_SndP: provided-interface=ADCC_DrivingFuncInfo_NtfMNPInfo_Drvg
      ADCC_DrivingFuncInfo_NtfMNPRoutesInfo_Drvg_SndP: provided-interface=ADCC_DrivingFuncInfo_NtfMNPRoutesInfo_Drvg
      ADCC_DrivingFuncInfo_NtfIHCInfo_Drvg_SndP: provided-interface=ADCC_DrivingFuncInfo_NtfIHCInfo_Drvg
      ADCC_DrivingFuncInfo_NtfISLIInfo_Drvg_2_SndP: provided-interface=ADCC_DrivingFuncInfo_NtfISLIInfo_Drvg_2
      ADCC_DrivingFuncInfo_NtfALCInfo_Drvg_2_SndP: provided-interface=ADCC_DrivingFuncInfo_NtfALCInfo_Drvg_2
      ADCC_DrivingFuncInfo_NtfICAInfo_Drvg_2_SndP: provided-interface=ADCC_DrivingFuncInfo_NtfICAInfo_Drvg_2
      ADCC_DrivingFuncInfo_NtfLSSInfo_Drvg_2_SndP: provided-interface=ADCC_DrivingFuncInfo_NtfLSSInfo_Drvg_2
      ADCC_DrivingFuncInfo_NtfESSInfo_Drvg_2_SndP: provided-interface=ADCC_DrivingFuncInfo_NtfESSInfo_Drvg_2
      ADCC_DrivingFuncInfo_NtfTrafficSignIdentify_Drvg_SndP: provided-interface=ADCC_DrivingFuncInfo_NtfTrafficSignIdentify_Drvg
      ADCC_DrivingFuncInfo_NtfACCSupplementInfo_Drvg_SndP: provided-interface=ADCC_DrivingFuncInfo_NtfACCSupplementInfo_Drvg
      ADCC_DrivingFuncInfo_NtfHNOPSupplementInfo_Drvg_SndP: provided-interface=ADCC_DrivingFuncInfo_NtfHNOPSupplementInfo_Drvg
      ADCC_DrivingFuncInfo_NtfMNPAllRoutesInfo_Drvg_SndP: provided-interface=ADCC_DrivingFuncInfo_NtfMNPAllRoutesInfo_Drvg
      ADCC_DrivingFuncInfo_NtfMNPMemRouteInfo_Drvg_SndP: provided-interface=ADCC_DrivingFuncInfo_NtfMNPMemRouteInfo_Drvg
      ADCC_DrivingFuncInfo_NtfTLRInfo_Drvg_SndP: provided-interface=ADCC_DrivingFuncInfo_NtfTLRInfo_Drvg
      ADCC_DrivingFuncInfo_NtfTLAInfo_Drvg_SndP: provided-interface=ADCC_DrivingFuncInfo_NtfTLAInfo_Drvg
      ADCC_DrivingFuncInfo_NtfMNPInfo_Drvg_2_SndP: provided-interface=ADCC_DrivingFuncInfo_NtfMNPInfo_Drvg_2
      ADCC_DrivingFuncInfo_NtfTrafficSign_Drvg_2_SndP: provided-interface=ADCC_DrivingFuncInfo_NtfTrafficSign_Drvg_2
      ADCC_DrivingFuncInfo_TolNtfADDrivingCardinfo_SndP: provided-interface=ADCC_DrivingFuncInfo_TolNtfADDrivingCardinfo
      ADCC_DrivingFuncInfo_SglNtfADDrivingCardinfo_SndP: provided-interface=ADCC_DrivingFuncInfo_SglNtfADDrivingCardinfo
    behavior InternalBehavior_ADCC_DrivingFuncInfo_Provider: data-type-mapping=Data_Type_Mappings
  application sw component type ADCC_DrivingFuncInfo_Consumer
    33 x require port:
      ADCC_DrivingFuncInfo_NtfTrafficSign_Drvg_RcvP: required-interface=ADCC_DrivingFuncInfo_NtfTrafficSign_Drvg
      ADCC_DrivingFuncInfo_NtfISLIInfo_Drvg_RcvP: required-interface=ADCC_DrivingFuncInfo_NtfISLIInfo_Drvg
      ADCC_DrivingFuncInfo_NtfACCInfo_Drvg_RcvP: required-interface=ADCC_DrivingFuncInfo_NtfACCInfo_Drvg
      ADCC_DrivingFuncInfo_NtfALCInfo_Drvg_RcvP: required-interface=ADCC_DrivingFuncInfo_NtfALCInfo_Drvg
      ADCC_DrivingFuncInfo_NtfICAInfo_Drvg_RcvP: required-interface=ADCC_DrivingFuncInfo_NtfICAInfo_Drvg
      ADCC_DrivingFuncInfo_NtfIntelligentEvasionInfo_Drvg_RcvP: required-interface=ADCC_DrivingFuncInfo_NtfIntelligentEvasionInfo_Drvg
      ADCC_DrivingFuncInfo_NtfHNOPfunctionInfo_Drvg_RcvP: required-interface=ADCC_DrivingFuncInfo_NtfHNOPfunctionInfo_Drvg
      ADCC_DrivingFuncInfo_NtfUNOPfunctionInfo_Drvg_RcvP: required-interface=ADCC_DrivingFuncInfo_NtfUNOPfunctionInfo_Drvg
      ADCC_DrivingFuncInfo_NtfHodDmsInfo_Drvg_RcvP: required-interface=ADCC_DrivingFuncInfo_NtfHodDmsInfo_Drvg
      ADCC_DrivingFuncInfo_NtfLSSInfo_Drvg_RcvP: required-interface=ADCC_DrivingFuncInfo_NtfLSSInfo_Drvg
      ADCC_DrivingFuncInfo_NtfESSInfo_Drvg_RcvP: required-interface=ADCC_DrivingFuncInfo_NtfESSInfo_Drvg
      ADCC_DrivingFuncInfo_NtfDAIInfo_Drvg_RcvP: required-interface=ADCC_DrivingFuncInfo_NtfDAIInfo_Drvg
      ADCC_DrivingFuncInfo_NtfNRAInfo_Drvg_RcvP: required-interface=ADCC_DrivingFuncInfo_NtfNRAInfo_Drvg
      ADCC_DrivingFuncInfo_NtfDrivingSoundInfo_Drvg_RcvP: required-interface=ADCC_DrivingFuncInfo_NtfDrivingSoundInfo_Drvg
      ADCC_DrivingFuncInfo_NtfMNPInfo_Drvg_RcvP: required-interface=ADCC_DrivingFuncInfo_NtfMNPInfo_Drvg
      ADCC_DrivingFuncInfo_NtfMNPRoutesInfo_Drvg_RcvP: required-interface=ADCC_DrivingFuncInfo_NtfMNPRoutesInfo_Drvg
      ADCC_DrivingFuncInfo_NtfIHCInfo_Drvg_RcvP: required-interface=ADCC_DrivingFuncInfo_NtfIHCInfo_Drvg
      ADCC_DrivingFuncInfo_NtfISLIInfo_Drvg_2_RcvP: required-interface=ADCC_DrivingFuncInfo_NtfISLIInfo_Drvg_2
      ADCC_DrivingFuncInfo_NtfALCInfo_Drvg_2_RcvP: required-interface=ADCC_DrivingFuncInfo_NtfALCInfo_Drvg_2
      ADCC_DrivingFuncInfo_NtfICAInfo_Drvg_2_RcvP: required-interface=ADCC_DrivingFuncInfo_NtfICAInfo_Drvg_2
      ADCC_DrivingFuncInfo_NtfLSSInfo_Drvg_2_RcvP: required-interface=ADCC_DrivingFuncInfo_NtfLSSInfo_Drvg_2
      ADCC_DrivingFuncInfo_NtfESSInfo_Drvg_2_RcvP: required-interface=ADCC_DrivingFuncInfo_NtfESSInfo_Drvg_2
      ADCC_DrivingFuncInfo_NtfTrafficSignIdentify_Drvg_RcvP: required-interface=ADCC_DrivingFuncInfo_NtfTrafficSignIdentify_Drvg
      ADCC_DrivingFuncInfo_NtfACCSupplementInfo_Drvg_RcvP: required-interface=ADCC_DrivingFuncInfo_NtfACCSupplementInfo_Drvg
      ADCC_DrivingFuncInfo_NtfHNOPSupplementInfo_Drvg_RcvP: required-interface=ADCC_DrivingFuncInfo_NtfHNOPSupplementInfo_Drvg
      ADCC_DrivingFuncInfo_NtfMNPAllRoutesInfo_Drvg_RcvP: required-interface=ADCC_DrivingFuncInfo_NtfMNPAllRoutesInfo_Drvg
      ADCC_DrivingFuncInfo_NtfMNPMemRouteInfo_Drvg_RcvP: required-interface=ADCC_DrivingFuncInfo_NtfMNPMemRouteInfo_Drvg
      ADCC_DrivingFuncInfo_NtfTLRInfo_Drvg_RcvP: required-interface=ADCC_DrivingFuncInfo_NtfTLRInfo_Drvg
      ADCC_DrivingFuncInfo_NtfTLAInfo_Drvg_RcvP: required-interface=ADCC_DrivingFuncInfo_NtfTLAInfo_Drvg
      ADCC_DrivingFuncInfo_NtfMNPInfo_Drvg_2_RcvP: required-interface=ADCC_DrivingFuncInfo_NtfMNPInfo_Drvg_2
      ADCC_DrivingFuncInfo_NtfTrafficSign_Drvg_2_RcvP: required-interface=ADCC_DrivingFuncInfo_NtfTrafficSign_Drvg_2
      ADCC_DrivingFuncInfo_TolNtfADDrivingCardinfo_RcvP: required-interface=ADCC_DrivingFuncInfo_TolNtfADDrivingCardinfo
      ADCC_DrivingFuncInfo_SglNtfADDrivingCardinfo_RcvP: required-interface=ADCC_DrivingFuncInfo_SglNtfADDrivingCardinfo
    behavior InternalBehavior_ADCC_DrivingFuncInfo_Consumer: data-type-mapping=Data_Type_Mappings
  application sw component type ADCC_ParkingFuncInfo_Provider
    19 x provide port:
      ADCC_ParkingFuncInfo_NtfParkingGenaralInfo_SndP: provided-interface=ADCC_ParkingFuncInfo_NtfParkingGenaralInfo
      ADCC_ParkingFuncInfo_NtfAPARPAInfo_SndP: provided-interface=ADCC_ParkingFuncInfo_NtfAPARPAInfo
      ADCC_ParkingFuncInfo_NtfAdvanceParkingInfo_SndP: provided-interface=ADCC_ParkingFuncInfo_NtfAdvanceParkingInfo
      ADCC_ParkingFuncInfo_NtfHPAPathDetail_SndP: provided-interface=ADCC_ParkingFuncInfo_NtfHPAPathDetail
      ADCC_ParkingFuncInfo_NtfHPATrainigPathInfo_SndP: provided-interface=ADCC_ParkingFuncInfo_NtfHPATrainigPathInfo
      ADCC_ParkingFuncInfo_NtfVPASelfBuildMapDate_SndP: provided-interface=ADCC_ParkingFuncInfo_NtfVPASelfBuildMapDate
      ADCC_ParkingFuncInfo_NtfMRAInfo_SndP: provided-interface=ADCC_ParkingFuncInfo_NtfMRAInfo
      ADCC_ParkingFuncInfo_NtfMEBInfo_SndP: provided-interface=ADCC_ParkingFuncInfo_NtfMEBInfo
      ADCC_ParkingFuncInfo_NtfMAAInfo_SndP: provided-interface=ADCC_ParkingFuncInfo_NtfMAAInfo
      ADCC_ParkingFuncInfo_NtfHPARepalyPathInfo_SndP: provided-interface=ADCC_ParkingFuncInfo_NtfHPARepalyPathInfo
      ADCC_ParkingFuncInfo_NtfParkingGenaralInfo_2_SndP: provided-interface=ADCC_ParkingFuncInfo_NtfParkingGenaralInfo_2
      ADCC_ParkingFuncInfo_NtfMRAInfo_2_SndP: provided-interface=ADCC_ParkingFuncInfo_NtfMRAInfo_2
      ADCC_ParkingFuncInfo_NtfAPARPAInfo_2_SndP: provided-interface=ADCC_ParkingFuncInfo_NtfAPARPAInfo_2
      ADCC_ParkingFuncInfo_NtfAdvanceParkingInfo_2_SndP: provided-interface=ADCC_ParkingFuncInfo_NtfAdvanceParkingInfo_2
      ADCC_ParkingFuncInfo_NtfHPAPathDetail_2_SndP: provided-interface=ADCC_ParkingFuncInfo_NtfHPAPathDetail_2
      ADCC_ParkingFuncInfo_NtfHPATrainigPathInfo_2_SndP: provided-interface=ADCC_ParkingFuncInfo_NtfHPATrainigPathInfo_2
      ADCC_ParkingFuncInfo_NtfHPARepalyPathInfo_2_SndP: provided-interface=ADCC_ParkingFuncInfo_NtfHPARepalyPathInfo_2
      ADCC_ParkingFuncInfo_NtfVPAInfo_SndP: provided-interface=ADCC_ParkingFuncInfo_NtfVPAInfo
      ADCC_ParkingFuncInfo_NtfParkingHMIInfo_SndP: provided-interface=ADCC_ParkingFuncInfo_NtfParkingHMIInfo
    behavior InternalBehavior_ADCC_ParkingFuncInfo_Provider: data-type-mapping=Data_Type_Mappings
  application sw component type ADCC_ParkingFuncInfo_Consumer
    19 x require port:
      ADCC_ParkingFuncInfo_NtfParkingGenaralInfo_RcvP: required-interface=ADCC_ParkingFuncInfo_NtfParkingGenaralInfo
      ADCC_ParkingFuncInfo_NtfAPARPAInfo_RcvP: required-interface=ADCC_ParkingFuncInfo_NtfAPARPAInfo
      ADCC_ParkingFuncInfo_NtfAdvanceParkingInfo_RcvP: required-interface=ADCC_ParkingFuncInfo_NtfAdvanceParkingInfo
      ADCC_ParkingFuncInfo_NtfHPAPathDetail_RcvP: required-interface=ADCC_ParkingFuncInfo_NtfHPAPathDetail
      ADCC_ParkingFuncInfo_NtfHPATrainigPathInfo_RcvP: required-interface=ADCC_ParkingFuncInfo_NtfHPATrainigPathInfo
      ADCC_ParkingFuncInfo_NtfVPASelfBuildMapDate_RcvP: required-interface=ADCC_ParkingFuncInfo_NtfVPASelfBuildMapDate
      ADCC_ParkingFuncInfo_NtfMRAInfo_RcvP: required-interface=ADCC_ParkingFuncInfo_NtfMRAInfo
      ADCC_ParkingFuncInfo_NtfMEBInfo_RcvP: required-interface=ADCC_ParkingFuncInfo_NtfMEBInfo
      ADCC_ParkingFuncInfo_NtfMAAInfo_RcvP: required-interface=ADCC_ParkingFuncInfo_NtfMAAInfo
      ADCC_ParkingFuncInfo_NtfHPARepalyPathInfo_RcvP: required-interface=ADCC_ParkingFuncInfo_NtfHPARepalyPathInfo
      ADCC_ParkingFuncInfo_NtfParkingGenaralInfo_2_RcvP: required-interface=ADCC_ParkingFuncInfo_NtfParkingGenaralInfo_2
      ADCC_ParkingFuncInfo_NtfMRAInfo_2_RcvP: required-interface=ADCC_ParkingFuncInfo_NtfMRAInfo_2
      ADCC_ParkingFuncInfo_NtfAPARPAInfo_2_RcvP: required-interface=ADCC_ParkingFuncInfo_NtfAPARPAInfo_2
      ADCC_ParkingFuncInfo_NtfAdvanceParkingInfo_2_RcvP: required-interface=ADCC_ParkingFuncInfo_NtfAdvanceParkingInfo_2
      ADCC_ParkingFuncInfo_NtfHPAPathDetail_2_RcvP: required-interface=ADCC_ParkingFuncInfo_NtfHPAPathDetail_2
      ADCC_ParkingFuncInfo_NtfHPATrainigPathInfo_2_RcvP: required-interface=ADCC_ParkingFuncInfo_NtfHPATrainigPathInfo_2
      ADCC_ParkingFuncInfo_NtfHPARepalyPathInfo_2_RcvP: required-interface=ADCC_ParkingFuncInfo_NtfHPARepalyPathInfo_2
      ADCC_ParkingFuncInfo_NtfVPAInfo_RcvP: required-interface=ADCC_ParkingFuncInfo_NtfVPAInfo
      ADCC_ParkingFuncInfo_NtfParkingHMIInfo_RcvP: required-interface=ADCC_ParkingFuncInfo_NtfParkingHMIInfo
    behavior InternalBehavior_ADCC_ParkingFuncInfo_Consumer: data-type-mapping=Data_Type_Mappings
  application sw component type ADCC_ParkingHmiEnv_Provider
    9 x provide port:
      ADCC_ParkingHmiEnv_NtfDynamicObjectList_Prkg_SndP: provided-interface=ADCC_ParkingHmiEnv_NtfDynamicObjectList_Prkg
      ADCC_ParkingHmiEnv_NtfStaticObjectList_Prkg_SndP: provided-interface=ADCC_ParkingHmiEnv_NtfStaticObjectList_Prkg
      ADCC_ParkingHmiEnv_NtfParkingSlot_Prkg_SndP: provided-interface=ADCC_ParkingHmiEnv_NtfParkingSlot_Prkg
      ADCC_ParkingHmiEnv_NtfHPAStaticObjectList_Prkg_SndP: provided-interface=ADCC_ParkingHmiEnv_NtfHPAStaticObjectList_Prkg
      ADCC_ParkingHmiEnv_NtfHPAParkingSlot_Prkg_SndP: provided-interface=ADCC_ParkingHmiEnv_NtfHPAParkingSlot_Prkg
      ADCC_ParkingHmiEnv_NtfVPASelfBuildMapInfo_SndP: provided-interface=ADCC_ParkingHmiEnv_NtfVPASelfBuildMapInfo
      ADCC_ParkingHmiEnv_NtfVPAParkingLotInfo_SndP: provided-interface=ADCC_ParkingHmiEnv_NtfVPAParkingLotInfo
      ADCC_ParkingHmiEnv_NtfDynamicObjectList_Prkg_2_SndP: provided-interface=ADCC_ParkingHmiEnv_NtfDynamicObjectList_Prkg_2
      ADCC_ParkingHmiEnv_NtfStaticObjectList_Prkg_2_SndP: provided-interface=ADCC_ParkingHmiEnv_NtfStaticObjectList_Prkg_2
    behavior InternalBehavior_ADCC_ParkingHmiEnv_Provider: data-type-mapping=Data_Type_Mappings
  application sw component type ADCC_ParkingHmiEnv_Consumer
    9 x require port:
      ADCC_ParkingHmiEnv_NtfDynamicObjectList_Prkg_RcvP: required-interface=ADCC_ParkingHmiEnv_NtfDynamicObjectList_Prkg
      ADCC_ParkingHmiEnv_NtfStaticObjectList_Prkg_RcvP: required-interface=ADCC_ParkingHmiEnv_NtfStaticObjectList_Prkg
      ADCC_ParkingHmiEnv_NtfParkingSlot_Prkg_RcvP: required-interface=ADCC_ParkingHmiEnv_NtfParkingSlot_Prkg
      ADCC_ParkingHmiEnv_NtfHPAStaticObjectList_Prkg_RcvP: required-interface=ADCC_ParkingHmiEnv_NtfHPAStaticObjectList_Prkg
      ADCC_ParkingHmiEnv_NtfHPAParkingSlot_Prkg_RcvP: required-interface=ADCC_ParkingHmiEnv_NtfHPAParkingSlot_Prkg
      ADCC_ParkingHmiEnv_NtfVPASelfBuildMapInfo_RcvP: required-interface=ADCC_ParkingHmiEnv_NtfVPASelfBuildMapInfo
      ADCC_ParkingHmiEnv_NtfVPAParkingLotInfo_RcvP: required-interface=ADCC_ParkingHmiEnv_NtfVPAParkingLotInfo
      ADCC_ParkingHmiEnv_NtfDynamicObjectList_Prkg_2_RcvP: required-interface=ADCC_ParkingHmiEnv_NtfDynamicObjectList_Prkg_2
      ADCC_ParkingHmiEnv_NtfStaticObjectList_Prkg_2_RcvP: required-interface=ADCC_ParkingHmiEnv_NtfStaticObjectList_Prkg_2
    behavior InternalBehavior_ADCC_ParkingHmiEnv_Consumer: data-type-mapping=Data_Type_Mappings
  application sw component type ADCC_AomMMSt_Provider
    provide port ADCC_AomMMSt_notifyExtMMResWLnk_SndP: provided-interface=ADCC_AomMMSt_notifyExtMMResWLnk
    provide port ADCC_AomMMSt_HDMapInfo_SndP: provided-interface=ADCC_AomMMSt_HDMapInfo
    behavior InternalBehavior_ADCC_AomMMSt_Provider: data-type-mapping=Data_Type_Mappings
  application sw component type ADCC_AomMMSt_Consumer
    require port ADCC_AomMMSt_notifyExtMMResWLnk_RcvP: required-interface=ADCC_AomMMSt_notifyExtMMResWLnk
    require port ADCC_AomMMSt_HDMapInfo_RcvP: required-interface=ADCC_AomMMSt_HDMapInfo
    behavior InternalBehavior_ADCC_AomMMSt_Consumer: data-type-mapping=Data_Type_Mappings
  application sw component type ADCC_AomDB_Provider
    provide port ServerPort_ADCC_AomDB: provided-interface=ADCC_AomDB
    behavior InternalBehavior_ADCC_AomDB_Provider: data-type-mapping=Data_Type_Mappings
  application sw component type ADCC_AomDB_Consumer
    require port ClientPort_ADCC_AomDB: required-interface=ADCC_AomDB
    behavior InternalBehavior_ADCC_AomDB_Consumer: data-type-mapping=Data_Type_Mappings
  application sw component type ADCC_RtMM_Provider
    provide port ADCC_RtMM_notifyRtMatchRes_SndP: provided-interface=ADCC_RtMM_notifyRtMatchRes
    behavior InternalBehavior_ADCC_RtMM_Provider: data-type-mapping=Data_Type_Mappings
  application sw component type ADCC_RtMM_Consumer
    require port ADCC_RtMM_notifyRtMatchRes_RcvP: required-interface=ADCC_RtMM_notifyRtMatchRes
    behavior InternalBehavior_ADCC_RtMM_Consumer: data-type-mapping=Data_Type_Mappings
  application sw component type FCM_DrivingHmiEnv_Provider
    7 x provide port:
      FCM_DrivingHmiEnv_NtfDynamicObjectList_SndP: provided-interface=FCM_DrivingHmiEnv_NtfDynamicObjectList
      FCM_DrivingHmiEnv_NtfStaticObjectList_SndP: provided-interface=FCM_DrivingHmiEnv_NtfStaticObjectList
      FCM_DrivingHmiEnv_NtfLaneLineList_SndP: provided-interface=FCM_DrivingHmiEnv_NtfLaneLineList
      FCM_DrivingHmiEnv_NtfLaneLineList_2_SndP: provided-interface=FCM_DrivingHmiEnv_NtfLaneLineList_2
      FCM_DrivingHmiEnv_NtfEgoFusionPose_SndP: provided-interface=FCM_DrivingHmiEnv_NtfEgoFusionPose
      FCM_DrivingHmiEnv_NtfDynamicObjectList_2_SndP: provided-interface=FCM_DrivingHmiEnv_NtfDynamicObjectList_2
      FCM_DrivingHmiEnv_NtfStaticObjectList_2_SndP: provided-interface=FCM_DrivingHmiEnv_NtfStaticObjectList_2
    behavior InternalBehavior_FCM_DrivingHmiEnv_Provider: data-type-mapping=Data_Type_Mappings
  application sw component type FCM_DrivingHmiEnv_Consumer
    7 x require port:
      FCM_DrivingHmiEnv_NtfDynamicObjectList_RcvP: required-interface=FCM_DrivingHmiEnv_NtfDynamicObjectList
      FCM_DrivingHmiEnv_NtfStaticObjectList_RcvP: required-interface=FCM_DrivingHmiEnv_NtfStaticObjectList
      FCM_DrivingHmiEnv_NtfLaneLineList_RcvP: required-interface=FCM_DrivingHmiEnv_NtfLaneLineList
      FCM_DrivingHmiEnv_NtfLaneLineList_2_RcvP: required-interface=FCM_DrivingHmiEnv_NtfLaneLineList_2
      FCM_DrivingHmiEnv_NtfEgoFusionPose_RcvP: required-interface=FCM_DrivingHmiEnv_NtfEgoFusionPose
      FCM_DrivingHmiEnv_NtfDynamicObjectList_2_RcvP: required-interface=FCM_DrivingHmiEnv_NtfDynamicObjectList_2
      FCM_DrivingHmiEnv_NtfStaticObjectList_2_RcvP: required-interface=FCM_DrivingHmiEnv_NtfStaticObjectList_2
    behavior InternalBehavior_FCM_DrivingHmiEnv_Consumer: data-type-mapping=Data_Type_Mappings
  application sw component type FCM_ActiveSafetyInfo_Provider
    4 x provide port:
      FCM_ActiveSafetyInfo_NtfActiveSafetyFcnInfo_SndP: provided-interface=FCM_ActiveSafetyInfo_NtfActiveSafetyFcnInfo
      FCM_ActiveSafetyInfo_NtfAEBTargetObjInfo_SndP: provided-interface=FCM_ActiveSafetyInfo_NtfAEBTargetObjInfo
      FCM_ActiveSafetyInfo_NtfActiveSafetyFcnInfo_2_SndP: provided-interface=FCM_ActiveSafetyInfo_NtfActiveSafetyFcnInfo_2
      FCM_ActiveSafetyInfo_NtfAEBTargetObjInfo_2_SndP: provided-interface=FCM_ActiveSafetyInfo_NtfAEBTargetObjInfo_2
    behavior InternalBehavior_FCM_ActiveSafetyInfo_Provider: data-type-mapping=Data_Type_Mappings
  application sw component type FCM_ActiveSafetyInfo_Consumer
    4 x require port:
      FCM_ActiveSafetyInfo_NtfActiveSafetyFcnInfo_RcvP: required-interface=FCM_ActiveSafetyInfo_NtfActiveSafetyFcnInfo
      FCM_ActiveSafetyInfo_NtfAEBTargetObjInfo_RcvP: required-interface=FCM_ActiveSafetyInfo_NtfAEBTargetObjInfo
      FCM_ActiveSafetyInfo_NtfActiveSafetyFcnInfo_2_RcvP: required-interface=FCM_ActiveSafetyInfo_NtfActiveSafetyFcnInfo_2
      FCM_ActiveSafetyInfo_NtfAEBTargetObjInfo_2_RcvP: required-interface=FCM_ActiveSafetyInfo_NtfAEBTargetObjInfo_2
    behavior InternalBehavior_FCM_ActiveSafetyInfo_Consumer: data-type-mapping=Data_Type_Mappings
  application sw component type FCM_DrivingFuncInfo_Provider
    14 x provide port:
      FCM_DrivingFuncInfo_NtfTrafficSign_SndP: provided-interface=FCM_DrivingFuncInfo_NtfTrafficSign
      FCM_DrivingFuncInfo_NtfISLIinfo_SndP: provided-interface=FCM_DrivingFuncInfo_NtfISLIinfo
      FCM_DrivingFuncInfo_NtfACCinfo_SndP: provided-interface=FCM_DrivingFuncInfo_NtfACCinfo
      FCM_DrivingFuncInfo_NtfICAInfo_SndP: provided-interface=FCM_DrivingFuncInfo_NtfICAInfo
      FCM_DrivingFuncInfo_NtfIntelligentEvasionInfo_SndP: provided-interface=FCM_DrivingFuncInfo_NtfIntelligentEvasionInfo
      FCM_DrivingFuncInfo_NtfHodDmsInfo_SndP: provided-interface=FCM_DrivingFuncInfo_NtfHodDmsInfo
      FCM_DrivingFuncInfo_NtfLSSInfo_SndP: provided-interface=FCM_DrivingFuncInfo_NtfLSSInfo
      FCM_DrivingFuncInfo_NtfESSInfo_SndP: provided-interface=FCM_DrivingFuncInfo_NtfESSInfo
      FCM_DrivingFuncInfo_NtfDAIInfo_SndP: provided-interface=FCM_DrivingFuncInfo_NtfDAIInfo
      FCM_DrivingFuncInfo_NtfISLIinfo_2_SndP: provided-interface=FCM_DrivingFuncInfo_NtfISLIinfo_2
      FCM_DrivingFuncInfo_NtfLSSInfo_2_SndP: provided-interface=FCM_DrivingFuncInfo_NtfLSSInfo_2
      FCM_DrivingFuncInfo_NtfDrivingSoundInfo_SndP: provided-interface=FCM_DrivingFuncInfo_NtfDrivingSoundInfo
      FCM_DrivingFuncInfo_NtfIHCInfo_SndP: provided-interface=FCM_DrivingFuncInfo_NtfIHCInfo
      FCM_DrivingFuncInfo_NtfHNOPfunctionInfo_SndP: provided-interface=FCM_DrivingFuncInfo_NtfHNOPfunctionInfo
    behavior InternalBehavior_FCM_DrivingFuncInfo_Provider: data-type-mapping=Data_Type_Mappings
  application sw component type FCM_DrivingFuncInfo_Consumer
    14 x require port:
      FCM_DrivingFuncInfo_NtfTrafficSign_RcvP: required-interface=FCM_DrivingFuncInfo_NtfTrafficSign
      FCM_DrivingFuncInfo_NtfISLIinfo_RcvP: required-interface=FCM_DrivingFuncInfo_NtfISLIinfo
      FCM_DrivingFuncInfo_NtfACCinfo_RcvP: required-interface=FCM_DrivingFuncInfo_NtfACCinfo
      FCM_DrivingFuncInfo_NtfICAInfo_RcvP: required-interface=FCM_DrivingFuncInfo_NtfICAInfo
      FCM_DrivingFuncInfo_NtfIntelligentEvasionInfo_RcvP: required-interface=FCM_DrivingFuncInfo_NtfIntelligentEvasionInfo
      FCM_DrivingFuncInfo_NtfHodDmsInfo_RcvP: required-interface=FCM_DrivingFuncInfo_NtfHodDmsInfo
      FCM_DrivingFuncInfo_NtfLSSInfo_RcvP: required-interface=FCM_DrivingFuncInfo_NtfLSSInfo
      FCM_DrivingFuncInfo_NtfESSInfo_RcvP: required-interface=FCM_DrivingFuncInfo_NtfESSInfo
      FCM_DrivingFuncInfo_NtfDAIInfo_RcvP: required-interface=FCM_DrivingFuncInfo_NtfDAIInfo
      FCM_DrivingFuncInfo_NtfISLIinfo_2_RcvP: required-interface=FCM_DrivingFuncInfo_NtfISLIinfo_2
      FCM_DrivingFuncInfo_NtfLSSInfo_2_RcvP: required-interface=FCM_DrivingFuncInfo_NtfLSSInfo_2
      FCM_DrivingFuncInfo_NtfDrivingSoundInfo_RcvP: required-interface=FCM_DrivingFuncInfo_NtfDrivingSoundInfo
      FCM_DrivingFuncInfo_NtfIHCInfo_RcvP: required-interface=FCM_DrivingFuncInfo_NtfIHCInfo
      FCM_DrivingFuncInfo_NtfHNOPfunctionInfo_RcvP: required-interface=FCM_DrivingFuncInfo_NtfHNOPfunctionInfo
    behavior InternalBehavior_FCM_DrivingFuncInfo_Consumer: data-type-mapping=Data_Type_Mappings
  application sw component type FCM_DVRSts_Provider
    4 x provide port:
      ServerPort_FCM_DVRSts: provided-interface=FCM_DVRSts
      FCM_DVRSts_notifyDVRSts_SndP: provided-interface=FCM_DVRSts_notifyDVRSts
      FCM_DVRSts_notifyDVRcameraSts_SndP: provided-interface=FCM_DVRSts_notifyDVRcameraSts
      FCM_DVRSts_notifyCameraInterParm_SndP: provided-interface=FCM_DVRSts_notifyCameraInterParm
    behavior InternalBehavior_FCM_DVRSts_Provider: data-type-mapping=Data_Type_Mappings
  application sw component type FCM_DVRSts_Consumer
    4 x require port:
      ClientPort_FCM_DVRSts: required-interface=FCM_DVRSts
      FCM_DVRSts_notifyDVRSts_RcvP: required-interface=FCM_DVRSts_notifyDVRSts
      FCM_DVRSts_notifyDVRcameraSts_RcvP: required-interface=FCM_DVRSts_notifyDVRcameraSts
      FCM_DVRSts_notifyCameraInterParm_RcvP: required-interface=FCM_DVRSts_notifyCameraInterParm
    behavior InternalBehavior_FCM_DVRSts_Consumer: data-type-mapping=Data_Type_Mappings
  application sw component type FCM_UUID_Provider
    provide port ServerPort_FCM_UUID: provided-interface=FCM_UUID
    behavior InternalBehavior_FCM_UUID_Provider: data-type-mapping=Data_Type_Mappings
  application sw component type FCM_UUID_Consumer
    require port ClientPort_FCM_UUID: required-interface=FCM_UUID
    behavior InternalBehavior_FCM_UUID_Consumer: data-type-mapping=Data_Type_Mappings
  application sw component type LCM_ICC_Data_Provider
    provide port LCM_ICC_Data_NtfIMUInfo_SndP: provided-interface=LCM_ICC_Data_NtfIMUInfo
    behavior InternalBehavior_LCM_ICC_Data_Provider: data-type-mapping=Data_Type_Mappings
  application sw component type LCM_ICC_Data_Consumer
    require port LCM_ICC_Data_NtfIMUInfo_RcvP: required-interface=LCM_ICC_Data_NtfIMUInfo
    behavior InternalBehavior_LCM_ICC_Data_Consumer: data-type-mapping=Data_Type_Mappings
  application sw component type LCM_ADCC_RawData_Provider
    provide port LCM_ADCC_RawData_NtfGRawInfo_SndP: provided-interface=LCM_ADCC_RawData_NtfGRawInfo
    behavior InternalBehavior_LCM_ADCC_RawData_Provider: data-type-mapping=Data_Type_Mappings
  application sw component type LCM_ADCC_RawData_Consumer
    require port LCM_ADCC_RawData_NtfGRawInfo_RcvP: required-interface=LCM_ADCC_RawData_NtfGRawInfo
    behavior InternalBehavior_LCM_ADCC_RawData_Consumer: data-type-mapping=Data_Type_Mappings
  application sw component type ADCC_ActiveSafetyInfo_Provider
    5 x provide port:
      ADCC_ActiveSafetyInfo_NtfActiveSafetyFcnInfo_Act_SndP: provided-interface=ADCC_ActiveSafetyInfo_NtfActiveSafetyFcnInfo_Act
      ADCC_ActiveSafetyInfo_NtfAEBTargetObjInfo_Act_SndP: provided-interface=ADCC_ActiveSafetyInfo_NtfAEBTargetObjInfo_Act
      ADCC_ActiveSafetyInfo_NtfActiveSafetyFcnInfo_Act_2_SndP: provided-interface=ADCC_ActiveSafetyInfo_NtfActiveSafetyFcnInfo_Act_2
      ADCC_ActiveSafetyInfo_NtfAEBTargetObjInfo_Act_2_SndP: provided-interface=ADCC_ActiveSafetyInfo_NtfAEBTargetObjInfo_Act_2
      ADCC_ActiveSafetyInfo_NtfAEBTargetObjInfo_Act_3_SndP: provided-interface=ADCC_ActiveSafetyInfo_NtfAEBTargetObjInfo_Act_3
    behavior InternalBehavior_ADCC_ActiveSafetyInfo_Provider: data-type-mapping=Data_Type_Mappings
  application sw component type ADCC_ActiveSafetyInfo_Consumer
    5 x require port:
      ADCC_ActiveSafetyInfo_NtfActiveSafetyFcnInfo_Act_RcvP: required-interface=ADCC_ActiveSafetyInfo_NtfActiveSafetyFcnInfo_Act
      ADCC_ActiveSafetyInfo_NtfAEBTargetObjInfo_Act_RcvP: required-interface=ADCC_ActiveSafetyInfo_NtfAEBTargetObjInfo_Act
      ADCC_ActiveSafetyInfo_NtfActiveSafetyFcnInfo_Act_2_RcvP: required-interface=ADCC_ActiveSafetyInfo_NtfActiveSafetyFcnInfo_Act_2
      ADCC_ActiveSafetyInfo_NtfAEBTargetObjInfo_Act_2_RcvP: required-interface=ADCC_ActiveSafetyInfo_NtfAEBTargetObjInfo_Act_2
      ADCC_ActiveSafetyInfo_NtfAEBTargetObjInfo_Act_3_RcvP: required-interface=ADCC_ActiveSafetyInfo_NtfAEBTargetObjInfo_Act_3
    behavior InternalBehavior_ADCC_ActiveSafetyInfo_Consumer: data-type-mapping=Data_Type_Mappings
  application sw component type ADCC_UUID_Provider
    provide port ServerPort_ADCC_UUID: provided-interface=ADCC_UUID
    behavior InternalBehavior_ADCC_UUID_Provider: data-type-mapping=Data_Type_Mappings
  application sw component type ADCC_UUID_Consumer
    require port ClientPort_ADCC_UUID: required-interface=ADCC_UUID
    behavior InternalBehavior_ADCC_UUID_Consumer: data-type-mapping=Data_Type_Mappings
  application sw component type FCM_SensorInfo_Provider
    provide port FCM_SensorInfo_NtfSensorSt_FCM_SndP: provided-interface=FCM_SensorInfo_NtfSensorSt_FCM
    behavior InternalBehavior_FCM_SensorInfo_Provider: data-type-mapping=Data_Type_Mappings
  application sw component type FCM_SensorInfo_Consumer
    require port FCM_SensorInfo_NtfSensorSt_FCM_RcvP: required-interface=FCM_SensorInfo_NtfSensorSt_FCM
    behavior InternalBehavior_FCM_SensorInfo_Consumer: data-type-mapping=Data_Type_Mappings
  application sw component type TBOX_SystemInfo_ICC_Provider
    provide port ServerPort_TBOX_SystemInfo_ICC: provided-interface=TBOX_SystemInfo_ICC
    provide port TBOX_SystemInfo_ICC_Event_NetworkStatus_ICC_SndP: provided-interface=TBOX_SystemInfo_ICC_Event_NetworkStatus_ICC
    behavior InternalBehavior_TBOX_SystemInfo_ICC_Provider: data-type-mapping=Data_Type_Mappings
  application sw component type TBOX_SystemInfo_ICC_Consumer
    require port ClientPort_TBOX_SystemInfo_ICC: required-interface=TBOX_SystemInfo_ICC
    require port TBOX_SystemInfo_ICC_Event_NetworkStatus_ICC_RcvP: required-interface=TBOX_SystemInfo_ICC_Event_NetworkStatus_ICC
    behavior InternalBehavior_TBOX_SystemInfo_ICC_Consumer: data-type-mapping=Data_Type_Mappings
  application sw component type ADCC_DVRSts_Provider
    4 x provide port:
      ServerPort_ADCC_DVRSts: provided-interface=ADCC_DVRSts
      ADCC_DVRSts_notifyDVRSts_ADCC_SndP: provided-interface=ADCC_DVRSts_notifyDVRSts_ADCC
      ADCC_DVRSts_notifyDVRcameraSts_ADCC_SndP: provided-interface=ADCC_DVRSts_notifyDVRcameraSts_ADCC
      ADCC_DVRSts_notifyCameraInterParm_ADCC_SndP: provided-interface=ADCC_DVRSts_notifyCameraInterParm_ADCC
    behavior InternalBehavior_ADCC_DVRSts_Provider: data-type-mapping=Data_Type_Mappings
  application sw component type ADCC_DVRSts_Consumer
    4 x require port:
      ClientPort_ADCC_DVRSts: required-interface=ADCC_DVRSts
      ADCC_DVRSts_notifyDVRSts_ADCC_RcvP: required-interface=ADCC_DVRSts_notifyDVRSts_ADCC
      ADCC_DVRSts_notifyDVRcameraSts_ADCC_RcvP: required-interface=ADCC_DVRSts_notifyDVRcameraSts_ADCC
      ADCC_DVRSts_notifyCameraInterParm_ADCC_RcvP: required-interface=ADCC_DVRSts_notifyCameraInterParm_ADCC
    behavior InternalBehavior_ADCC_DVRSts_Consumer: data-type-mapping=Data_Type_Mappings
  application sw component type ADAS_DataInLoop_Provider
    5 x provide port:
      ADAS_DataInLoop_notifyData_ID_SndP: provided-interface=ADAS_DataInLoop_notifyData_ID
      ADAS_DataInLoop_notifyDataInLoop_{1..3}_SndP: provided-interface=ADAS_DataInLoop_notifyDataInLoop_{1..3}
      ADAS_DataInLoop_notifyDataInLoop_SndP: provided-interface=ADAS_DataInLoop_notifyDataInLoop
    behavior InternalBehavior_ADAS_DataInLoop_Provider: data-type-mapping=Data_Type_Mappings
  application sw component type ADAS_DataInLoop_Consumer
    5 x require port:
      ADAS_DataInLoop_notifyData_ID_RcvP: required-interface=ADAS_DataInLoop_notifyData_ID
      ADAS_DataInLoop_notifyDataInLoop_{1..3}_RcvP: required-interface=ADAS_DataInLoop_notifyDataInLoop_{1..3}
      ADAS_DataInLoop_notifyDataInLoop_RcvP: required-interface=ADAS_DataInLoop_notifyDataInLoop
    behavior InternalBehavior_ADAS_DataInLoop_Consumer: data-type-mapping=Data_Type_Mappings
  application sw component type IVI_UnixTimestamp_Provider
    provide port IVI_UnixTimestamp_notifyUnixTimestamp_SndP: provided-interface=IVI_UnixTimestamp_notifyUnixTimestamp
    behavior InternalBehavior_IVI_UnixTimestamp_Provider: data-type-mapping=Data_Type_Mappings
  application sw component type IVI_UnixTimestamp_Consumer
    require port IVI_UnixTimestamp_notifyUnixTimestamp_RcvP: required-interface=IVI_UnixTimestamp_notifyUnixTimestamp
    behavior InternalBehavior_IVI_UnixTimestamp_Consumer: data-type-mapping=Data_Type_Mappings
  application sw component type ADAS_GNSSInfo_Provider
    provide port ServerPort_ADAS_GNSSInfo: provided-interface=ADAS_GNSSInfo
    provide port ADAS_GNSSInfo_notifyGNSSInfo_SndP: provided-interface=ADAS_GNSSInfo_notifyGNSSInfo
    behavior InternalBehavior_ADAS_GNSSInfo_Provider: data-type-mapping=Data_Type_Mappings
  application sw component type ADAS_GNSSInfo_Consumer
    require port ClientPort_ADAS_GNSSInfo: required-interface=ADAS_GNSSInfo
    require port ADAS_GNSSInfo_notifyGNSSInfo_RcvP: required-interface=ADAS_GNSSInfo_notifyGNSSInfo
    behavior InternalBehavior_ADAS_GNSSInfo_Consumer: data-type-mapping=Data_Type_Mappings
